VERSION "Generated from PQ35_46 ACAN KMatrix"

NS_ :

BS_:

BU_: XXX AFS Airbag Allrad AppGW_SK BAP_Tester BMS_Hybrid Bremse_ESP_AU714 Bremse_ESP_EPB_EBC460Vi Bremse_MK100_ESC Bremse_MK60EC Bremse_MK70MABS Bremse_TRW_EBC450M Bremse_TRW_ESP Daempfer EPB_TRW EPB_TRW_VW411CS ESP_AU316 FLA Gateway_PQ35 Getriebe_AG6 Getriebe_DL800_R8 Getriebe_DL800_ZSG_R8 Getriebe_DQ Getriebe_DQ_Hyb Getriebe_Sele Gurtmikro_PQ35 HCA LEH_Hybrid LH_EPS_APA LH_EPS_ZF_2G LH_EPS_ZF_3G LPG_Interface_Box LWR LWS Magne_Ride Motor_Diesel Motor_Hybrid Motor_Otto Motor_Slave PDC_PLA Quersperre_VAQ RKA_Plus SAK Waehlhebel Waehlhebel_Sele

BO_ 1827 NMH_ABS: 7 XXX
 SG_ NMH_ABS_Start_1 : 0|1@1+ (1,0) [1|1] "" BMS_Hybrid,EPB_TRW_VW411CS,Gateway_PQ35,Getriebe_AG6,Getriebe_DL800_ZSG_R8,LEH_Hybrid,Motor_Diesel,Motor_Hybrid,Motor_Otto
 SG_ NMH_ABS_Start_2 : 1|1@1+ (1,0) [1|1] "" XXX
 SG_ NMH_ABS_Normal_Mode_1 : 2|1@1+ (1,0) [1|1] "" XXX
 SG_ NMH_ABS_Normal_Mode_2 : 3|1@1+ (1,0) [1|1] "" XXX
 SG_ NMH_ABS_Per_WakeUp : 8|5@1+ (1,0) [0|3] "" XXX
 SG_ NMH_ABS_Fkt_WakeUp : 13|3@1+ (1,0) [0|0] "" XXX
 SG_ NMH_ABS_NM_aktiv_Klemme_15 : 16|1@1+ (1,0) [1|1] "" XXX
 SG_ NMH_ABS_NM_aktiv_Diagnose : 17|1@1+ (1,0) [1|1] "" XXX
 SG_ NMH_ABS_NM_aktiv_Start : 18|1@1+ (1,0) [1|1] "" XXX
 SG_ NMH_ABS_NL_aktiv_4 : 19|1@1+ (1,0) [1|1] "" XXX
 SG_ NMH_ABS_TimeOut_Fehler : 33|1@1+ (1,0) [1|1] "" XXX
 SG_ NMH_ABS_CAN_Diag_deaktiv : 34|1@1+ (1,0) [1|1] "" XXX
 SG_ NMH_ABS_KompSchutz : 35|1@1+ (1,0) [1|1] "" XXX
 SG_ NMH_ABS_Mute_Mode : 36|1@1+ (1,0) [1|1] "" XXX
 SG_ NMH_ABS_Transport_Mode : 37|1@1+ (1,0) [1|1] "" XXX
 SG_ NMH_ABS_Abschaltstufe_aktiv : 38|1@1+ (1,0) [1|1] "" XXX
 SG_ NMH_ABS_Eindraht_Fehler : 39|1@1+ (1,0) [1|1] "" XXX
 SG_ NMH_ABS_Car_WakeUp : 6|1@1+ (1,0) [1|1] "" XXX
 SG_ NMH_ABS_NL_aktiv_5 : 20|1@1+ (1,0) [1|1] "" XXX
 SG_ NMH_ABS_NL_aktiv_6 : 21|1@1+ (1,0) [1|1] "" XXX
 SG_ NMH_ABS_NL_aktiv_7 : 22|1@1+ (1,0) [1|1] "" XXX
 SG_ NMH_ABS_NL_aktiv_8 : 23|1@1+ (1,0) [1|1] "" XXX
 SG_ NMH_ABS_NL_0 : 24|1@1+ (1,0) [0|1] "" XXX
 SG_ NMH_ABS_NL_1 : 25|1@1+ (1,0) [0|1] "" XXX
 SG_ NMH_ABS_NL_2 : 26|1@1+ (1,0) [0|1] "" XXX
 SG_ NMH_ABS_NL_3 : 27|1@1+ (1,0) [0|1] "" XXX
 SG_ NMH_ABS_NL_4 : 28|1@1+ (1,0) [0|1] "" XXX
 SG_ NMH_ABS_NL_5 : 29|1@1+ (1,0) [0|1] "" XXX
 SG_ NMH_ABS_NL_6 : 30|1@1+ (1,0) [0|1] "" XXX
 SG_ NMH_ABS_NL_7 : 31|1@1+ (1,0) [0|1] "" XXX

BO_ 768 mTP_Dyn_Diag_1_1: 8 XXX
 SG_ TPDyn_Diag_1_1 : 0|64@1+ (1,0) [0|0] "" Gateway_PQ35

BO_ 769 mTP_Dyn_Diag_1_2: 8 XXX
 SG_ TPDyn_Diag_1_2 : 0|64@1+ (1,0) [0|0] "" Gateway_PQ35

BO_ 770 mTP_Dyn_Diag_1_3: 8 XXX
 SG_ TPDyn_Diag_1_3 : 0|64@1+ (1,0) [0|0] "" Gateway_PQ35

BO_ 771 mTP_Dyn_Diag_1_4: 8 XXX
 SG_ TPDyn_Diag_1_4 : 0|64@1+ (1,0) [0|0] "" Gateway_PQ35

BO_ 772 mTP_Dyn_Diag_1_5: 8 XXX
 SG_ TPDyn_Diag_1_5 : 0|64@1+ (1,0) [0|0] "" Gateway_PQ35

BO_ 773 mTP_Dyn_Diag_1_6: 8 XXX
 SG_ TPDyn_Diag_1_6 : 0|64@1+ (1,0) [0|0] "" Gateway_PQ35

BO_ 774 mTP_Dyn_Diag_1_7: 8 XXX
 SG_ TPDyn_Diag_1_7 : 0|64@1+ (1,0) [0|0] "" Gateway_PQ35

BO_ 775 mTP_Dyn_Diag_1_8: 8 XXX
 SG_ TPDyn_Diag_1_8 : 0|64@1+ (1,0) [0|0] "" Gateway_PQ35

BO_ 515 mTP_Er_ABS: 7 XXX
 SG_ ABS_TP_Er : 0|56@1+ (1,0) [0|0] "" Gateway_PQ35

BO_ 1440 mBremse_2: 8 XXX
 SG_ BR2_Blinkmode : 39|1@1+ (1,0) [0|1] "" Gateway_PQ35
 SG_ BR2_Querbeschl : 0|8@1+ (0.01,-1.27) [-1.27|1.27] "Unit_ForceOfGravi" AFS,Allrad,AppGW_SK,Daempfer,Gateway_PQ35,Getriebe_AG6,Getriebe_DL800_R8,Getriebe_DQ,Getriebe_DQ_Hyb,Getriebe_Sele,HCA,LWR,Magne_Ride,Motor_Diesel,Motor_Otto,RKA_Plus
 SG_ BR2_Zahnzahl : 0|6@1+ (1,0) [0|63] "" Gateway_PQ35,Getriebe_AG6,Getriebe_DL800_R8,Getriebe_DQ,Getriebe_DQ_Hyb,PDC_PLA,RKA_Plus
 SG_ BR2_Querb_Zahn : 8|1@1+ (1,0) [0|1] "" AFS,Allrad,AppGW_SK,Daempfer,Gateway_PQ35,Getriebe_AG6,Getriebe_DL800_R8,Getriebe_DQ,Getriebe_DQ_Hyb,Getriebe_Sele,HCA,LWR,Magne_Ride,Motor_Diesel,Motor_Otto,PDC_PLA,RKA_Plus
 SG_ BR2_mi_Radgeschw : 9|15@1+ (0.002,0) [0|65.278] "Unit_Hertz" Gateway_PQ35,Getriebe_DL800_R8,Getriebe_DQ,Getriebe_DQ_Hyb
 SG_ BR2_Lampe_ABS : 24|1@1+ (1,0) [0|1] "" Airbag,AppGW_SK,Gateway_PQ35
 SG_ BR2_Lampe_ASR : 25|1@1+ (1,0) [0|1] "" AppGW_SK,Gateway_PQ35,PDC_PLA
 SG_ BR2_Lampe_BK : 26|1@1+ (1,0) [0|1] "" Gateway_PQ35
 SG_ BR2_Lampe_RKA : 27|1@1+ (1,0) [0|1] "" AppGW_SK,Gateway_PQ35
 SG_ BR2_Zaehler : 28|4@1+ (1,0) [0|15] "" Daempfer,Gateway_PQ35,Getriebe_AG6,HCA,Magne_Ride
 SG_ BR2_Text : 32|4@1+ (1,0) [0|14] "" Gateway_PQ35,Getriebe_DL800_R8
 SG_ BR2_Aku_Warn : 36|2@1+ (1,0) [0|3] "" Gateway_PQ35
 SG_ BR2_HDC_aktiv : 38|1@1+ (1,0) [0|1] "" Gateway_PQ35,Getriebe_DL800_R8,Getriebe_DQ,Getriebe_DQ_Hyb,Motor_Diesel,Motor_Hybrid,Motor_Otto
 SG_ BR2_Wegimpulse : 40|11@1+ (1,0) [0|2047] "" AppGW_SK,Gateway_PQ35,Getriebe_DL800_R8,Getriebe_DQ,Getriebe_DQ_Hyb
 SG_ BR2_Ueberl_Imp : 51|1@1+ (1,0) [0|1] "" Gateway_PQ35
 SG_ BR2_Fehlereintr : 52|1@1+ (1,0) [0|1] "" Gateway_PQ35
 SG_ BR2_LampeHDC : 53|1@1+ (1,0) [0|1] "" Gateway_PQ35,Getriebe_DL800_R8,Getriebe_DQ,Getriebe_DQ_Hyb
 SG_ BR2_QB_Querbeschl : 54|1@1+ (1,0) [0|1] "" AFS,Allrad,AppGW_SK,Gateway_PQ35,HCA,LWR,Magne_Ride,Motor_Diesel,Motor_Otto,RKA_Plus
 SG_ BR2_Sta_Imp : 55|1@1+ (1,0) [0|1] "" Gateway_PQ35
 SG_ BR2_Impulszahl : 56|6@1+ (1,0) [0|63] "" AppGW_SK,Gateway_PQ35,Getriebe_AG6,Getriebe_DL800_R8,Getriebe_DQ,Getriebe_DQ_Hyb
 SG_ BR2_SleepInd : 62|1@1+ (1,0) [0|1] "" Gateway_PQ35
 SG_ BR2_Sta_Quer : 63|1@1+ (1,0) [0|1] "" Allrad,Gateway_PQ35,Getriebe_DL800_R8,Getriebe_DQ,Getriebe_DQ_Hyb

BO_ 416 mBremse_1: 8 XXX
 SG_ BR1_ASR_Anf : 0|1@1+ (1,0) [0|1] "" Airbag,Allrad,Gateway_PQ35,Getriebe_AG6,Getriebe_DL800_R8,Getriebe_DQ,Getriebe_DQ_Hyb,LH_EPS_APA,Motor_Diesel,Motor_Hybrid,Motor_Otto,PDC_PLA,RKA_Plus
 SG_ BR1_MSR_Anf : 1|1@1+ (1,0) [0|1] "" Airbag,Gateway_PQ35,Getriebe_AG6,Getriebe_DL800_R8,Getriebe_DQ,Getriebe_DQ_Hyb,LH_EPS_APA,Motor_Diesel,Motor_Hybrid,Motor_Otto,PDC_PLA,RKA_Plus
 SG_ BR1_ABS_Brems : 2|1@1+ (1,0) [0|1] "" Airbag,Allrad,Daempfer,EPB_TRW,EPB_TRW_VW411CS,Gateway_PQ35,Getriebe_AG6,Getriebe_DL800_R8,Getriebe_DQ,Getriebe_DQ_Hyb,HCA,LH_EPS_APA,Magne_Ride,Motor_Diesel,Motor_Hybrid,Motor_Otto,PDC_PLA,RKA_Plus
 SG_ BR1_EDS_Eingr : 3|1@1+ (1,0) [0|1] "" Airbag,Allrad,Daempfer,Gateway_PQ35,Getriebe_AG6,Getriebe_DL800_R8,Getriebe_DQ,Getriebe_DQ_Hyb,LH_EPS_APA,Motor_Diesel,Motor_Hybrid,Motor_Otto,PDC_PLA,RKA_Plus
 SG_ BR1_ESP_Eingr : 4|1@1+ (1,0) [0|1] "" AFS,Airbag,Allrad,Daempfer,Gateway_PQ35,Getriebe_AG6,Getriebe_DL800_R8,Getriebe_DQ,Getriebe_DQ_Hyb,Getriebe_Sele,HCA,LH_EPS_APA,LH_EPS_ZF_2G,LH_EPS_ZF_3G,Motor_Diesel,Motor_Hybrid,Motor_Otto,PDC_PLA,RKA_Plus
 SG_ BR1_ASR_Eingr : 5|2@1+ (1,0) [0|3] "" Gateway_PQ35,Getriebe_AG6,Getriebe_DL800_R8,Getriebe_DQ,Getriebe_DQ_Hyb,LH_EPS_APA
 SG_ BR1_EBV_Eingr : 7|1@1+ (1,0) [0|1] "" Daempfer,Gateway_PQ35,LH_EPS_APA,RKA_Plus
 SG_ BR1_Lampe_ABS : 8|1@1+ (1,0) [0|1] "" Gateway_PQ35
 SG_ BR1_Lampe_ASR : 9|1@1+ (1,0) [0|1] "" Gateway_PQ35
 SG_ BR1_Lampe_BK : 10|1@1+ (1,0) [0|1] "" Gateway_PQ35
 SG_ BR1_Lichtschalt : 11|1@1+ (1,0) [0|1] "" AFS,Allrad,Gateway_PQ35,LH_EPS_APA,LH_EPS_ZF_2G,LH_EPS_ZF_3G,LWR,Motor_Diesel,Motor_Hybrid,Motor_Otto,RKA_Plus
 SG_ BR1_StaDruckschw : 12|1@1+ (1,0) [0|1] "" Gateway_PQ35,Motor_Diesel,Motor_Hybrid,Motor_Otto
 SG_ BR1_Diagnose : 15|1@1+ (1,0) [0|1] "" Airbag,Gateway_PQ35
 SG_ BR1_Rad_kmh : 17|15@1+ (0.01,0) [0|326.39] "Unit_KiloMeterPerHour" Airbag,BMS_Hybrid,Daempfer,FLA,Gateway_PQ35,Getriebe_AG6,Getriebe_DL800_R8,Getriebe_DL800_ZSG_R8,Getriebe_DQ,Getriebe_DQ_Hyb,Getriebe_Sele,HCA,LH_EPS_APA,LH_EPS_ZF_2G,LH_EPS_ZF_3G,Magne_Ride,Motor_Diesel,Motor_Hybrid,Motor_Otto,PDC_PLA,SAK
 SG_ BR1_ASRMo_fa : 40|8@1+ (0.39,0) [0|99.06] "Unit_PerCent" Gateway_PQ35,Motor_Diesel,Motor_Hybrid,Motor_Otto
 SG_ BR1_MSR_Mo_inv : 40|8@1+ (-0.39,99.45) [0|99.06] "Unit_PerCent" Gateway_PQ35,Motor_Diesel,Motor_Hybrid,Motor_Otto
 SG_ BR1_MSR_Mo : 48|8@1+ (0.39,0) [0|99.06] "Unit_PerCent" Gateway_PQ35,Motor_Diesel,Motor_Hybrid,Motor_Otto
 SG_ BR1_Zaehler : 56|4@1+ (1,0) [0|15] "" Airbag,Daempfer,EPB_TRW,EPB_TRW_VW411CS,Gateway_PQ35,Getriebe_AG6,HCA,LH_EPS_APA,LH_EPS_ZF_2G,LH_EPS_ZF_3G,Magne_Ride,Motor_Diesel,Motor_Hybrid,Motor_Otto,PDC_PLA
 SG_ BR1_ASR_ESP : 60|1@1+ (1,0) [0|1] "" Gateway_PQ35
 SG_ BR1_ESPASR_passiv : 61|1@1+ (1,0) [0|1] "" Gateway_PQ35,Getriebe_AG6,Getriebe_DL800_R8,Getriebe_DQ,Getriebe_DQ_Hyb,Getriebe_Sele,HCA,Magne_Ride,Motor_Diesel,Motor_Otto,PDC_PLA
 SG_ BR1_Sta_ESP : 62|1@1+ (1,0) [0|1] "" Gateway_PQ35,Getriebe_DL800_R8,Getriebe_DQ,Getriebe_DQ_Hyb,Magne_Ride,Motor_Diesel,Motor_Otto,PDC_PLA,RKA_Plus
 SG_ BR1_Ersatz_Kmh : 63|1@1+ (1,0) [0|1] "" Airbag,Gateway_PQ35,HCA,LH_EPS_APA,LH_EPS_ZF_2G,LH_EPS_ZF_3G,Motor_Diesel,Motor_Hybrid,Motor_Otto,PDC_PLA
 SG_ BR1_MAD : 13|1@1+ (1,0) [0|1] "" Gateway_PQ35
 SG_ BR1_Sta_MAD : 14|1@1+ (1,0) [0|1] "" Gateway_PQ35
 SG_ BR1_BKV_aktiv : 16|1@1+ (1,0) [0|1] "" Gateway_PQ35,Motor_Diesel,Motor_Hybrid,Motor_Otto
 SG_ BR1_ASRMo_sl : 32|8@1+ (0.39,0) [0|99.06] "Unit_PerCent" Gateway_PQ35,Motor_Hybrid,Motor_Otto

BO_ 928 mBremse_10: 8 XXX
 SG_ B10_Checksumme : 0|8@1+ (1,0) [0|255] "" Gateway_PQ35,Motor_Diesel,Motor_Otto,PDC_PLA
 SG_ B10_Zaehler : 8|4@1+ (1,0) [0|15] "" Gateway_PQ35,Motor_Diesel,Motor_Otto,PDC_PLA
 SG_ B10_QB_Wegimp_VL : 12|1@1+ (1,0) [0|1] "" Gateway_PQ35,Motor_Diesel,Motor_Otto,PDC_PLA
 SG_ B10_QB_Wegimp_VR : 13|1@1+ (1,0) [0|1] "" Gateway_PQ35,Motor_Diesel,Motor_Otto,PDC_PLA
 SG_ B10_QB_Wegimp_HL : 14|1@1+ (1,0) [0|1] "" Gateway_PQ35,Motor_Diesel,Motor_Otto,PDC_PLA
 SG_ B10_QB_Wegimp_HR : 15|1@1+ (1,0) [0|1] "" Gateway_PQ35,Motor_Diesel,Motor_Otto,PDC_PLA
 SG_ B10_Wegimp_VL : 16|10@1+ (1,0) [0|1000] "" Gateway_PQ35,Motor_Diesel,Motor_Otto,PDC_PLA
 SG_ B10_Wegimp_VR : 26|10@1+ (1,0) [0|1000] "" Gateway_PQ35,Motor_Diesel,Motor_Otto,PDC_PLA
 SG_ B10_Wegimp_HL : 36|10@1+ (1,0) [0|1000] "" Gateway_PQ35,Motor_Diesel,Motor_Otto,PDC_PLA
 SG_ B10_Wegimp_HR : 46|10@1+ (1,0) [0|1000] "" Gateway_PQ35,Motor_Diesel,Motor_Otto,PDC_PLA
 SG_ B10_QB_Fahrtr_VL : 56|1@1+ (1,0) [0|1] "" Gateway_PQ35,PDC_PLA
 SG_ B10_QB_Fahrtr_VR : 57|1@1+ (1,0) [0|1] "" Gateway_PQ35,PDC_PLA
 SG_ B10_QB_Fahrtr_HL : 58|1@1+ (1,0) [0|1] "" Gateway_PQ35,PDC_PLA
 SG_ B10_QB_Fahrtr_HR : 59|1@1+ (1,0) [0|1] "" Gateway_PQ35,PDC_PLA
 SG_ B10_Fahrtr_VL : 60|1@1+ (1,0) [0|1] "" Gateway_PQ35,PDC_PLA
 SG_ B10_Fahrtr_VR : 61|1@1+ (1,0) [0|1] "" Gateway_PQ35,PDC_PLA
 SG_ B10_Fahrtr_HL : 62|1@1+ (1,0) [0|1] "" Gateway_PQ35,PDC_PLA
 SG_ B10_Fahrtr_HR : 63|1@1+ (1,0) [0|1] "" Gateway_PQ35,PDC_PLA

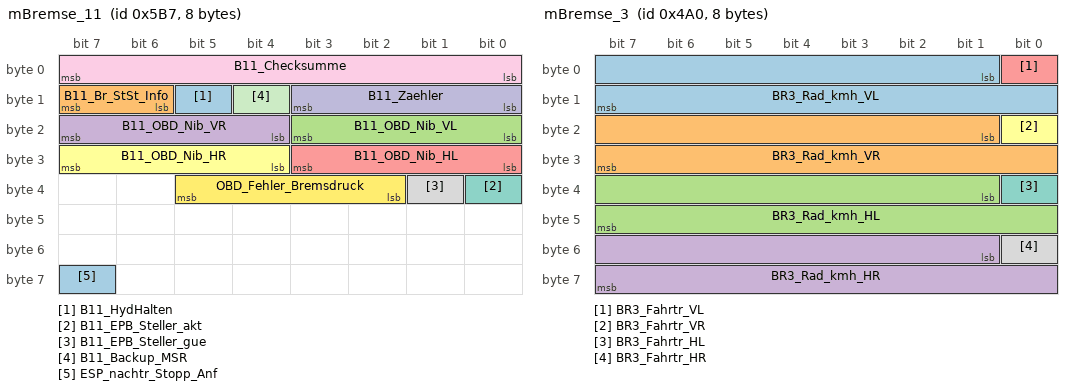
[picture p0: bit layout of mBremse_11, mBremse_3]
BO_ 1463 mBremse_11: 8 XXX
 SG_ B11_HydHalten : 13|1@1+ (1,0) [0|1] "" EPB_TRW_VW411CS,Gateway_PQ35,Getriebe_DQ,Getriebe_DQ_Hyb,Motor_Diesel,Motor_Otto,PDC_PLA
 SG_ B11_Br_StSt_Info : 14|2@1+ (1,0) [0|3] "" EPB_TRW_VW411CS,Gateway_PQ35,Motor_Diesel,Motor_Otto
 SG_ B11_OBD_Nib_VL : 16|4@1+ (1,0) [0|15] "" Gateway_PQ35,Motor_Diesel,Motor_Otto
 SG_ B11_OBD_Nib_VR : 20|4@1+ (1,0) [0|15] "" Gateway_PQ35,Motor_Diesel,Motor_Otto
 SG_ B11_OBD_Nib_HL : 24|4@1+ (1,0) [0|15] "" Gateway_PQ35,Motor_Diesel,Motor_Otto
 SG_ B11_OBD_Nib_HR : 28|4@1+ (1,0) [0|15] "" Gateway_PQ35,Motor_Diesel,Motor_Otto
 SG_ B11_EPB_Steller_akt : 32|1@1+ (1,0) [0|1] "" Gateway_PQ35,Motor_Diesel,Motor_Otto
 SG_ B11_EPB_Steller_gue : 33|1@1+ (1,0) [0|1] "" Gateway_PQ35,Motor_Diesel,Motor_Otto
 SG_ B11_Checksumme : 0|8@1+ (1,0) [0|255] "" Gateway_PQ35,Motor_Hybrid
 SG_ B11_Zaehler : 8|4@1+ (1,0) [0|15] "" Gateway_PQ35,Motor_Hybrid
 SG_ B11_Backup_MSR : 12|1@1+ (1,0) [0|1] "" Gateway_PQ35,Motor_Hybrid
 SG_ OBD_Fehler_Bremsdruck : 34|4@1+ (1,0) [0|15] "" Gateway_PQ35,Motor_Hybrid
 SG_ ESP_nachtr_Stopp_Anf : 63|1@1+ (1,0) [0|1] "" Gateway_PQ35,Motor_Diesel,Motor_Otto

BO_ 1184 mBremse_3: 8 XXX
 SG_ BR3_Rad_kmh_VL : 1|15@1+ (0.01,0) [0|326.39] "Unit_KiloMeterPerHour" AFS,Allrad,EPB_TRW,EPB_TRW_VW411CS,Gateway_PQ35,Getriebe_AG6,Getriebe_DL800_R8,Getriebe_DQ,Getriebe_DQ_Hyb,Getriebe_Sele,LH_EPS_APA,LH_EPS_ZF_2G,LH_EPS_ZF_3G,LWR,LWS,Magne_Ride,Motor_Diesel,Motor_Hybrid,Motor_Otto,PDC_PLA
 SG_ BR3_Rad_kmh_VR : 17|15@1+ (0.01,0) [0|326.39] "Unit_KiloMeterPerHour" AFS,Allrad,EPB_TRW,EPB_TRW_VW411CS,Gateway_PQ35,Getriebe_AG6,Getriebe_DL800_R8,Getriebe_DQ,Getriebe_DQ_Hyb,Getriebe_Sele,LH_EPS_APA,LH_EPS_ZF_2G,LH_EPS_ZF_3G,LWR,LWS,Magne_Ride,Motor_Diesel,Motor_Hybrid,Motor_Otto,PDC_PLA
 SG_ BR3_Rad_kmh_HL : 33|15@1+ (0.01,0) [0|326.39] "Unit_KiloMeterPerHour" AFS,Allrad,EPB_TRW,EPB_TRW_VW411CS,Gateway_PQ35,Getriebe_AG6,Getriebe_DL800_R8,Getriebe_DQ,Getriebe_DQ_Hyb,Getriebe_Sele,LH_EPS_APA,LH_EPS_ZF_2G,LH_EPS_ZF_3G,LWR,LWS,Magne_Ride,Motor_Diesel,Motor_Hybrid,Motor_Otto,PDC_PLA
 SG_ BR3_Rad_kmh_HR : 49|15@1+ (0.01,0) [0|326.39] "Unit_KiloMeterPerHour" AFS,Allrad,EPB_TRW,EPB_TRW_VW411CS,Gateway_PQ35,Getriebe_AG6,Getriebe_DL800_R8,Getriebe_DQ,Getriebe_DQ_Hyb,Getriebe_Sele,LH_EPS_APA,LH_EPS_ZF_2G,LH_EPS_ZF_3G,LWR,LWS,Magne_Ride,Motor_Diesel,Motor_Hybrid,Motor_Otto,PDC_PLA
 SG_ BR3_Fahrtr_VL : 0|1@1+ (1,0) [0|1] "" AFS,EPB_TRW_VW411CS,Gateway_PQ35,Getriebe_AG6,LWR,Magne_Ride
 SG_ BR3_Fahrtr_VR : 16|1@1+ (1,0) [0|1] "" AFS,EPB_TRW_VW411CS,Gateway_PQ35,Getriebe_AG6,LWR,Magne_Ride
 SG_ BR3_Fahrtr_HL : 32|1@1+ (1,0) [0|1] "" EPB_TRW_VW411CS,Gateway_PQ35,Getriebe_AG6,Magne_Ride
 SG_ BR3_Fahrtr_HR : 48|1@1+ (1,0) [0|1] "" EPB_TRW_VW411CS,Gateway_PQ35,Getriebe_AG6,Magne_Ride

BO_ 672 mBremse_4: 8 XXX
 SG_ BR4_Vorgabe_Mi : 0|8@1+ (7,-896) [-896|882] "Unit_NewtoMeter" Allrad,Gateway_PQ35
 SG_ BR4_Einheit : 16|2@1+ (1,0) [0|2] "" Allrad,Gateway_PQ35,Quersperre_VAQ
 SG_ BR4_Schwelle : 18|2@1+ (1,0) [0|3] "" Gateway_PQ35,Getriebe_AG6,Motor_Hybrid,Motor_Otto
 SG_ BR4_Lampentrennung_gue : 26|1@1+ (1,0) [0|1] "" Gateway_PQ35
 SG_ BR4_Lampe_ASRESP : 27|1@1+ (1,0) [0|1] "" AppGW_SK,Gateway_PQ35
 SG_ BR4_ESP_Off : 28|1@1+ (1,0) [0|1] "" Gateway_PQ35
 SG_ BR1_ASR_ESP : 29|1@1+ (1,0) [0|1] "" Gateway_PQ35
 SG_ BR4_Unterdruck : 32|8@1+ (4,0) [0|1016] "Unit_MilliBar" Gateway_PQ35,Getriebe_AG6,Motor_Hybrid,Motor_Otto
 SG_ BR4_Zaehler : 52|4@1+ (1,0) [0|15] "" Gateway_PQ35,Motor_Diesel,Motor_Hybrid,Motor_Otto,Quersperre_VAQ
 SG_ BR4_Checksum : 56|8@1+ (1,0) [0|255] "" Gateway_PQ35,Motor_Diesel,Motor_Hybrid,Motor_Otto,Quersperre_VAQ
 SG_ BR4_Vorgabe_Mi_308 : 0|8@1+ (0.7874015748031496063,-100.0000000000000000001) [0|100.0000000000000000001] "Unit_PerCent" Gateway_PQ35
 SG_ BR4_Vorgabe_Max : 0|8@1+ (10,0) [0|2540] "Unit_NewtoMeter" Gateway_PQ35,Quersperre_VAQ
 SG_ BR4_Vorgabe_Hi : 8|8@1+ (0.7874015748031496063,-100.0000000000000000001) [0|100.0000000000000000001] "Unit_PerCent" Gateway_PQ35
 SG_ BR4_Vorgabe_Min : 8|8@1+ (10,0) [0|2540] "Unit_NewtoMeter" Gateway_PQ35,Quersperre_VAQ
 SG_ BR4_Abschaltung_VL : 20|1@1+ (1,0) [0|1] "" Gateway_PQ35
 SG_ BR4_Abschaltung_VR : 21|1@1+ (1,0) [0|1] "" Gateway_PQ35
 SG_ BR4_Abschaltung_HL : 22|1@1+ (1,0) [0|1] "" Gateway_PQ35
 SG_ BR4_Abschaltung_HR : 23|1@1+ (1,0) [0|1] "" Gateway_PQ35
 SG_ BR4_Lampe_RKA : 24|1@1+ (1,0) [0|1] "" Gateway_PQ35
 SG_ BR4_Summer_RKA : 25|1@1+ (1,0) [0|1] "" Gateway_PQ35
 SG_ BR4_Status_ESP : 40|4@1+ (1,0) [0|5] "" Gateway_PQ35,Quersperre_VAQ
 SG_ BR4_MABS_Verbau : 51|1@1+ (1,0) [0|1] "" Gateway_PQ35
 SG_ BR4_RKA_Verbau : 30|2@1+ (1,0) [0|2] "" AppGW_SK,Gateway_PQ35

BO_ 1192 mBremse_5: 8 XXX
 SG_ BR5_Giergeschw : 0|14@1+ (0.01,0) [0|100] "Unit_DegreOfArcPerSecond" AFS,Allrad,Daempfer,FLA,Gateway_PQ35,HCA,LWR,Magne_Ride,PDC_PLA,RKA_Plus
 SG_ BR5_Sta_Gierrate : 14|1@1+ (1,0) [0|1] "" AFS,Allrad,Daempfer,FLA,Gateway_PQ35,HCA,LWR,Magne_Ride,PDC_PLA,RKA_Plus
 SG_ BR5_Vorzeichen : 15|1@1+ (1,0) [0|1] "" AFS,Allrad,Daempfer,FLA,Gateway_PQ35,HCA,LWR,Magne_Ride,PDC_PLA,RKA_Plus
 SG_ BR5_Bremsdruck : 16|12@1+ (0.1,0) [0|409.4] "Unit_Bar" Daempfer,EPB_TRW,EPB_TRW_VW411CS,Gateway_PQ35,Getriebe_AG6,Getriebe_DL800_R8,Getriebe_DQ,Getriebe_DQ_Hyb,HCA,Magne_Ride,Motor_Diesel,Motor_Otto,PDC_PLA
 SG_ BR5_Stillstand : 28|1@1+ (1,0) [0|1] "" Gateway_PQ35,HCA,Magne_Ride,PDC_PLA
 SG_ BR5_Druckgueltig : 29|1@1+ (1,0) [0|1] "" Daempfer,EPB_TRW,EPB_TRW_VW411CS,Gateway_PQ35,Getriebe_AG6,Getriebe_DL800_R8,Getriebe_DQ,Getriebe_DQ_Hyb,HCA,Magne_Ride,Motor_Diesel,Motor_Otto,PDC_PLA
 SG_ BR5_Sta_Druck : 30|1@1+ (1,0) [0|1] "" EPB_TRW_VW411CS,Gateway_PQ35
 SG_ BR5_Sign_Druck : 31|1@1+ (1,0) [0|1] "" Daempfer,EPB_TRW_VW411CS,Gateway_PQ35,Getriebe_AG6,Getriebe_DL800_R8,Getriebe_DQ,Getriebe_DQ_Hyb,HCA,Magne_Ride,Motor_Diesel,Motor_Otto
 SG_ BR5_Bremslicht : 43|1@1+ (1,0) [0|1] "" Gateway_PQ35
 SG_ BR5_AWV2_Bremsruck : 46|1@1+ (1,0) [0|1] "" Gateway_PQ35
 SG_ BR5_AWV2_Fehler : 47|1@1+ (1,0) [0|1] "" Gateway_PQ35
 SG_ BR5_Zaehler : 52|4@1+ (1,0) [0|15] "" Daempfer,EPB_TRW,EPB_TRW_VW411CS,Gateway_PQ35,Getriebe_AG6,HCA,Magne_Ride,Motor_Diesel,Motor_Hybrid,Motor_Otto,PDC_PLA
 SG_ BR5_Checksumme : 56|8@1+ (1,0) [0|255] "" Daempfer,EPB_TRW,EPB_TRW_VW411CS,Gateway_PQ35,Getriebe_AG6,HCA,Magne_Ride,Motor_Diesel,Motor_Hybrid,Motor_Otto
 SG_ ESP_Rollenmodus_Deaktivieren : 34|1@1+ (1,0) [0|1] "" Gateway_PQ35
 SG_ ESP_Stat_FallBack_eBKV : 35|1@1+ (1,0) [0|1] "" Gateway_PQ35
 SG_ ESP_Anforderung_EPB : 36|2@1+ (1,0) [0|3] "" EPB_TRW_VW411CS,Gateway_PQ35
 SG_ BR5_Anhi_akt : 41|1@1+ (1,0) [0|1] "" Gateway_PQ35,Getriebe_DL800_R8,Getriebe_DQ,Getriebe_DQ_Hyb
 SG_ BR5_v_Ueberw : 42|1@1+ (1,0) [0|1] "" Gateway_PQ35
 SG_ BR5_Fahrer_tritt_ZBR_Schw : 45|1@1+ (1,0) [0|1] "" Gateway_PQ35
 SG_ BR5_ECD_Lampe : 51|1@1+ (1,0) [0|1] "" Gateway_PQ35
 SG_ ESP_Autohold_aktiv : 38|1@1+ (1,0) [0|1] "" EPB_TRW_VW411CS,Gateway_PQ35,Motor_Diesel,Motor_Otto
 SG_ ESP_Autohold_Standby : 39|1@1+ (1,0) [0|1] "" EPB_TRW_VW411CS,Gateway_PQ35,Motor_Diesel,Motor_Otto
 SG_ BR5_Anhi_Sta : 40|1@1+ (1,0) [0|1] "" Gateway_PQ35,Getriebe_DL800_R8,Getriebe_DQ,Getriebe_DQ_Hyb
 SG_ BR5_Notbremsung : 44|1@1+ (1,0) [0|1] "" Gateway_PQ35
 SG_ BR5_ZT_Rueckk_Umsetz : 48|1@1+ (1,0) [0|1] "" Gateway_PQ35,Motor_Diesel,Motor_Otto
 SG_ BR5_ANB_CM_Rueckk_Umsetz : 49|1@1+ (1,0) [0|1] "" Gateway_PQ35
 SG_ BR5_HDC_bereit : 50|1@1+ (1,0) [0|1] "" Gateway_PQ35

BO_ 428 mBremse_8: 8 XXX
 SG_ BR8_Checksumme : 0|8@1+ (1,0) [0|255] "" Airbag,EPB_TRW,EPB_TRW_VW411CS,Gateway_PQ35,Getriebe_AG6,Getriebe_DL800_R8,Getriebe_DQ,Getriebe_DQ_Hyb,Motor_Diesel,Motor_Otto,PDC_PLA
 SG_ BR8_Zaehler : 8|4@1+ (1,0) [0|15] "" Airbag,EPB_TRW,EPB_TRW_VW411CS,Gateway_PQ35,Getriebe_AG6,Motor_Diesel,Motor_Otto,PDC_PLA
 SG_ BR8_Sta_ACC_Anf : 12|1@1+ (1,0) [0|1] "" Gateway_PQ35,Getriebe_AG6,Getriebe_DL800_R8,Getriebe_DQ,Motor_Diesel,Motor_Otto
 SG_ BR8_Verz_EPB_akt : 13|1@1+ (1,0) [0|1] "" EPB_TRW,EPB_TRW_VW411CS,Gateway_PQ35,Getriebe_AG6,Motor_Diesel,Motor_Otto
 SG_ BR8_Sta_Br_temp : 14|1@1+ (1,0) [0|1] "" Gateway_PQ35,Motor_Diesel,Motor_Otto
 SG_ BR8_Sta_Br_Druck : 15|1@1+ (1,0) [0|1] "" Gateway_PQ35,Motor_Diesel,Motor_Otto
 SG_ BR8_Istbeschl : 32|9@1+ (0.02,-7.22) [-7.22|2.98] "Unit_MeterPerSeconSquar" Gateway_PQ35,Motor_Diesel,Motor_Otto
 SG_ BR8_QB_LBeschl : 42|1@1+ (1,0) [0|1] "" AppGW_SK,EPB_TRW_VW411CS,Gateway_PQ35,Getriebe_DL800_R8,Getriebe_DQ,Getriebe_DQ_Hyb,Motor_Diesel,Motor_Otto,PDC_PLA
 SG_ BR8_aktBrSyst : 45|1@1+ (1,0) [0|1] "" Gateway_PQ35,Motor_Diesel,Motor_Otto
 SG_ BR8_StaBrSyst : 47|1@1+ (1,0) [0|1] "" Gateway_PQ35,Motor_Diesel,Motor_Otto
 SG_ BR8_Laengsbeschl : 48|10@1+ (0.03125,-16) [-15.96875|15.9375] "Unit_MeterPerSeconSquar" AppGW_SK,EPB_TRW_VW411CS,Gateway_PQ35,Getriebe_AG6,Getriebe_DL800_R8,Getriebe_DQ,Getriebe_DQ_Hyb,Motor_Diesel,Motor_Otto,PDC_PLA
 SG_ BR8_Sta_ADR_BR : 58|1@1+ (1,0) [0|1] "" Gateway_PQ35,Motor_Diesel,Motor_Otto
 SG_ BR8_Sta_VerzReg : 60|1@1+ (1,0) [0|1] "" Gateway_PQ35,Motor_Diesel,Motor_Otto
 SG_ BR8_Verz_EPB : 62|1@1+ (1,0) [0|1] "" EPB_TRW,EPB_TRW_VW411CS,Gateway_PQ35
 SG_ BR8_Check_EPB : 63|1@1+ (1,0) [0|1] "" EPB_TRW_VW411CS,Gateway_PQ35
 SG_ BR8_HHC_Haltebestaetigung : 16|1@1+ (1,0) [0|1] "" Gateway_PQ35,Getriebe_DL800_R8
 SG_ BR8_HHC_Signal_QBit : 17|1@1+ (1,0) [0|1] "" Gateway_PQ35,Getriebe_DL800_R8
 SG_ BR8_Sta_HW_BLS : 41|1@1+ (1,0) [0|1] "" Gateway_PQ35
 SG_ BR8_ESC_Mode : 43|2@1+ (1,0) [0|3] "" Gateway_PQ35
 SG_ BR8_Fa_bremst : 46|1@1+ (1,0) [0|1] "" Gateway_PQ35,Motor_Diesel,Motor_Otto
 SG_ BR8_Quattro : 59|1@1+ (1,0) [0|1] "" Gateway_PQ35
 SG_ BR8_Sta_BLS : 61|1@1+ (1,0) [0|1] "" Gateway_PQ35,Motor_Diesel,Motor_Otto
 SG_ ESP_MKB_ausloesbar : 20|1@1+ (1,0) [0|1] "" Airbag,Gateway_PQ35
 SG_ ESP_Haltebestaetigung : 21|1@1+ (1,0) [0|1] "" Gateway_PQ35,Motor_Diesel,Motor_Otto
 SG_ ESC_Motorstartverzoegerung : 22|1@1+ (1,0) [0|1] "" Gateway_PQ35,Motor_Diesel,Motor_Otto

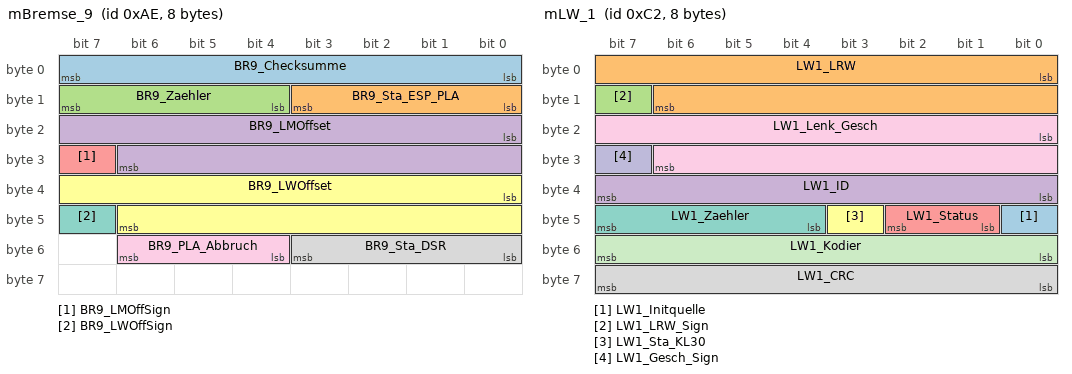
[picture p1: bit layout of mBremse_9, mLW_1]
BO_ 174 mBremse_9: 8 XXX
 SG_ BR9_Checksumme : 0|8@1+ (1,0) [0|255] "" LH_EPS_APA,LH_EPS_ZF_2G,LH_EPS_ZF_3G
 SG_ BR9_Sta_ESP_PLA : 8|4@1+ (1,0) [0|10] "" Getriebe_DQ,Getriebe_DQ_Hyb,PDC_PLA
 SG_ BR9_Zaehler : 12|4@1+ (1,0) [0|15] "" LH_EPS_APA,LH_EPS_ZF_2G,LH_EPS_ZF_3G
 SG_ BR9_LMOffset : 16|15@1+ (0.0003052,0) [0|10.0004884] "Unit_NewtoMeter" LH_EPS_APA,LH_EPS_ZF_2G,LH_EPS_ZF_3G
 SG_ BR9_LMOffSign : 31|1@1+ (1,0) [0|1] "" LH_EPS_APA,LH_EPS_ZF_2G,LH_EPS_ZF_3G
 SG_ BR9_LWOffset : 32|15@1+ (0.04375,0) [0|1433.55625] "Unit_DegreOfArc" LH_EPS_APA,LH_EPS_ZF_2G,LH_EPS_ZF_3G
 SG_ BR9_LWOffSign : 47|1@1+ (1,0) [0|1] "" LH_EPS_APA,LH_EPS_ZF_2G,LH_EPS_ZF_3G
 SG_ BR9_Sta_DSR : 48|4@1+ (1,0) [0|7] "" LH_EPS_APA,LH_EPS_ZF_2G,LH_EPS_ZF_3G
 SG_ BR9_PLA_Abbruch : 52|3@1+ (1,0) [1|6] "" PDC_PLA

BO_ 1986 mLWS_Init: 4 XXX
 SG_ LWI_Init_ID : 0|8@1+ (1,0) [0|255] "" LWS
 SG_ LWI_Codierbytes : 8|24@1+ (1,0) [0|16777215] "" LWS

BO_ 912 mGate_Komf_1: 8 XXX
 SG_ GK1_SleepAckn : 7|1@1+ (1,0) [0|1] "" Bremse_ESP_AU714,Bremse_MK60EC,Bremse_MK70MABS,Bremse_TRW_ESP,EPB_TRW,ESP_AU316,Getriebe_DL800_R8,Getriebe_DL800_ZSG_R8,Getriebe_DQ,Getriebe_DQ_Hyb,Getriebe_Sele,LH_EPS_APA,LH_EPS_ZF_2G,LH_EPS_ZF_3G,LWS,Motor_Diesel,Motor_Hybrid,Motor_Otto,Waehlhebel,Waehlhebel_Sele
 SG_ GK1_Sta_Anhaen : 1|1@1+ (1,0) [0|1] "" Bremse_ESP_EPB_EBC460Vi,Bremse_MK100_ESC,Bremse_MK60EC,Bremse_TRW_EBC450M,Bremse_TRW_ESP,ESP_AU316,Getriebe_DL800_R8,Getriebe_DQ,Getriebe_DQ_Hyb,HCA,Motor_Diesel,Motor_Otto,PDC_PLA,RKA_Plus
 SG_ GK1_Sta_Licht1 : 2|1@1+ (1,0) [0|1] "" AFS,AppGW_SK,Bremse_ESP_AU714,Bremse_ESP_EPB_EBC460Vi,Bremse_MK100_ESC,Bremse_MK60EC,Bremse_MK70MABS,Bremse_TRW_EBC450M,Bremse_TRW_ESP,EPB_TRW,EPB_TRW_VW411CS,ESP_AU316,FLA,LH_EPS_APA,LH_EPS_ZF_2G,LH_EPS_ZF_3G,Motor_Diesel,Motor_Otto,PDC_PLA
 SG_ GK1_Sta_Tuerkont : 4|1@1+ (1,0) [0|1] "" Bremse_ESP_EPB_EBC460Vi,Bremse_MK100_ESC,Bremse_MK60EC,Bremse_MK70MABS,Bremse_TRW_EBC450M,Bremse_TRW_ESP,EPB_TRW,EPB_TRW_VW411CS,ESP_AU316,Getriebe_DL800_R8,Getriebe_DQ,Getriebe_DQ_Hyb,Motor_Diesel,Motor_Hybrid,Motor_Otto,PDC_PLA
 SG_ GK1_Fa_Tuerkont : 16|1@1+ (1,0) [0|1] "" AppGW_SK,Bremse_ESP_EPB_EBC460Vi,Bremse_MK100_ESC,Bremse_MK60EC,Bremse_MK70MABS,Bremse_TRW_EBC450M,Bremse_TRW_ESP,EPB_TRW,EPB_TRW_VW411CS,ESP_AU316,Getriebe_AG6,Getriebe_DL800_R8,Getriebe_DQ,Getriebe_DQ_Hyb,Motor_Diesel,Motor_Hybrid,Motor_Otto,PDC_PLA
 SG_ GK1_Rueckfahr : 28|1@1+ (1,0) [1|1] "" AFS,Allrad,AppGW_SK,Bremse_ESP_AU714,Bremse_ESP_EPB_EBC460Vi,Bremse_MK100_ESC,Bremse_MK60EC,Bremse_MK70MABS,Bremse_TRW_EBC450M,Bremse_TRW_ESP,EPB_TRW,EPB_TRW_VW411CS,ESP_AU316,FLA,LH_EPS_APA,LH_EPS_ZF_2G,LH_EPS_ZF_3G,Motor_Diesel,Motor_Otto,PDC_PLA
 SG_ GK1_Anhaenger : 46|1@1+ (1,0) [0|1] "" Bremse_ESP_EPB_EBC460Vi,Bremse_MK100_ESC,Bremse_MK60EC,Bremse_TRW_EBC450M,Bremse_TRW_ESP,ESP_AU316,Getriebe_DL800_R8,Getriebe_DQ,Getriebe_DQ_Hyb,HCA,Motor_Diesel,Motor_Otto,PDC_PLA,RKA_Plus
 SG_ GK1_Wischer_vorn : 50|1@1+ (1,0) [0|1] "" AFS,Bremse_ESP_AU714,Bremse_ESP_EPB_EBC460Vi,Bremse_MK100_ESC,Bremse_MK60EC,Bremse_MK70MABS,Bremse_TRW_EBC450M,Bremse_TRW_ESP,ESP_AU316,HCA,Motor_Diesel,Motor_Hybrid,Motor_Otto
 SG_ GK1_Sta_ILM_F_1 : 51|1@1+ (1,0) [0|1] "" AFS,Bremse_ESP_AU714,Bremse_ESP_EPB_EBC460Vi,Bremse_MK100_ESC,Bremse_MK60EC,Bremse_MK70MABS,Bremse_TRW_EBC450M,Bremse_TRW_ESP,ESP_AU316,HCA,Motor_Diesel,Motor_Hybrid,Motor_Otto
 SG_ GK1_Warnblk_Status : 55|1@1+ (1,0) [1|1] "" AppGW_SK,Bremse_ESP_EPB_EBC460Vi,Bremse_MK100_ESC,Bremse_TRW_EBC450M,Bremse_TRW_ESP,ESP_AU316
 SG_ GK1_Sta_RDK_Warn : 0|1@1+ (1,0) [0|1] "" XXX
 SG_ GK1_Sta_Licht3 : 3|1@1+ (1,0) [0|1] "" AFS
 SG_ GK1_Sta_Li_vorn : 5|1@1+ (1,0) [0|1] "" AFS
 SG_ LIA_Standlicht : 6|1@1+ (1,0) [1|1] "" XXX
 SG_ GK1_CharismaModus : 8|4@1+ (1,0) [0|3] "" Daempfer,Getriebe_DL800_R8,Getriebe_DQ,Getriebe_DQ_Hyb,LH_EPS_APA,LH_EPS_ZF_2G,LH_EPS_ZF_3G,Magne_Ride,Motor_Diesel,Motor_Otto
 SG_ GK1_SamFktNr : 12|4@1+ (1,0) [0|1] "" Daempfer,Getriebe_DL800_R8,Getriebe_DQ,Getriebe_DQ_Hyb,LH_EPS_APA,LH_EPS_ZF_2G,LH_EPS_ZF_3G,Magne_Ride,Motor_Diesel,Motor_Otto
 SG_ GK1_RueckfahrSch : 17|1@1+ (1,0) [0|1] "" Bremse_ESP_AU714
 SG_ GK1_ELV_verrieg : 18|1@1+ (1,0) [0|1] "" XXX
 SG_ GK1_Sta_Kessy_2 : 19|1@1+ (1,0) [0|1] "" Motor_Diesel,Motor_Otto
 SG_ GK1_Sta_Stdhzg : 20|1@1+ (1,0) [0|1] "" Motor_Diesel,Motor_Hybrid,Motor_Otto
 SG_ GK1_SH_Verbau : 21|1@1+ (1,0) [0|1] "" Motor_Diesel,Motor_Hybrid,Motor_Otto
 SG_ GK1_ParkFrontWi : 22|1@1+ (1,0) [0|1] "" XXX
 SG_ GK1_KW_Warm : 23|1@1+ (1,0) [0|1] "" Motor_Diesel,Motor_Hybrid,Motor_Otto
 SG_ BCM_Remotestart_Betrieb : 24|1@1+ (1,0) [0|1] "" Getriebe_DQ,Getriebe_DQ_Hyb,Motor_Diesel,Motor_Otto
 SG_ BSK_HL_geoeffnet : 26|1@1+ (1,0) [0|1] "" AppGW_SK,Motor_Diesel,Motor_Otto,PDC_PLA
 SG_ BSK_HR_geoeffnet : 27|1@1+ (1,0) [0|1] "" AppGW_SK,Motor_Diesel,Motor_Otto,PDC_PLA
 SG_ GK1_BrLi_links : 29|1@1+ (1,0) [0|1] "" XXX
 SG_ GK1_BrLi_rechts : 30|1@1+ (1,0) [0|1] "" XXX
 SG_ GK1_BrLi_mitte : 31|1@1+ (1,0) [0|1] "" XXX
 SG_ GK1_BLS_ILM : 32|1@1+ (1,0) [0|1] "" XXX
 SG_ GK1_EDC_ILM : 33|1@1+ (1,0) [0|1] "" XXX
 SG_ GK1_Blinker_li : 34|1@1+ (1,0) [0|1] "" AFS,AppGW_SK,LWR,Motor_Diesel,Motor_Otto,PDC_PLA
 SG_ GK1_Blinker_re : 35|1@1+ (1,0) [0|1] "" AFS,AppGW_SK,LWR,Motor_Diesel,Motor_Otto,PDC_PLA
 SG_ GK1_def_P_verr : 36|1@1+ (1,0) [0|1] "" Getriebe_AG6
 SG_ GK1_LS1_Fernlicht : 37|1@1+ (1,0) [0|1] "" AFS,FLA,LWR
 SG_ GK1_Sta_Licht2 : 38|1@1+ (1,0) [0|1] "" AFS
 SG_ GK1_Sta_LSM : 39|1@1+ (1,0) [0|1] "" AFS,FLA,LWR,Motor_Diesel,Motor_Otto,PDC_PLA
 SG_ WI1_Front_Wasch : 40|1@1+ (1,0) [0|1] "" XXX
 SG_ BSK_BT_geoeffnet : 41|1@1+ (1,0) [0|1] "" AppGW_SK,Motor_Diesel,Motor_Otto,PDC_PLA
 SG_ BCM_CV_Taster : 42|1@1+ (1,0) [0|1] "" XXX
 SG_ BSK_HD_Hauptraste : 43|1@1+ (1,0) [0|1] "" Motor_Diesel,Motor_Hybrid,Motor_Otto
 SG_ BSK_Tankklappe : 44|1@1+ (1,0) [0|1] "" Motor_Hybrid
 SG_ EV1_Anf_Klemme_50 : 45|1@1+ (1,0) [0|1] "" Motor_Diesel,Motor_Otto
 SG_ GK1_BrLi_Anhaen : 47|1@1+ (1,0) [0|1] "" XXX
 SG_ GK1_Abblendlicht : 48|1@1+ (1,0) [0|1] "" AFS,AppGW_SK,FLA,LWR
 SG_ GK1_Fernlicht : 49|1@1+ (1,0) [0|1] "" AFS,AppGW_SK,FLA,LWR
 SG_ GK1_Abbl_VL_def : 52|1@1+ (1,0) [0|1] "" AFS
 SG_ GK1_Abbl_VR_def : 53|1@1+ (1,0) [0|1] "" AFS
 SG_ GK1_Blink_Autob : 54|1@1+ (1,0) [0|1] "" XXX
 SG_ GK1_SH_laeuft : 56|1@1+ (1,0) [0|1] "" XXX
 SG_ SH1_ein_Wasserpumpe : 57|1@1+ (1,0) [0|1] "" XXX
 SG_ GK1_Nebel_ein : 58|1@1+ (1,0) [0|1] "" AFS,AppGW_SK,FLA
 SG_ GK1_Bremslicht : 59|1@1+ (1,0) [0|1] "" XXX
 SG_ GK1_Anh_abgesteckt : 60|1@1+ (1,0) [0|1] "" XXX
 SG_ GK1_AnhKonLamp : 61|1@1+ (1,0) [0|1] "" XXX
 SG_ LDS_Stellung_AFL : 62|1@1+ (1,0) [1|1] "" XXX
 SG_ GK1_SH_Zusatzfkt : 63|1@1+ (1,0) [0|1] "" XXX
 SG_ BCM_Offroad_Taster : 25|1@1+ (1,0) [0|1] "" Bremse_ESP_EPB_EBC460Vi,ESP_AU316,Motor_Diesel,Motor_Otto

BO_ 194 mLW_1: 8 XXX
 SG_ LW1_Initquelle : 40|1@1+ (1,0) [0|1] "" Bremse_MK100_ESC,Bremse_MK60EC,Bremse_TRW_ESP,ESP_AU316,Gateway_PQ35,LH_EPS_APA,LH_EPS_ZF_2G
 SG_ LW1_LRW : 0|15@1+ (0.04375,0) [0|1433.55625] "Unit_DegreOfArc" AFS,Allrad,Bremse_ESP_EPB_EBC460Vi,Bremse_MK100_ESC,Bremse_MK60EC,Bremse_TRW_EBC450M,Bremse_TRW_ESP,Daempfer,ESP_AU316,Gateway_PQ35,Getriebe_DL800_R8,Getriebe_DQ,Getriebe_DQ_Hyb,Getriebe_Sele,LH_EPS_APA,LH_EPS_ZF_2G,LWR,Magne_Ride,Motor_Diesel,Motor_Hybrid,Motor_Otto,RKA_Plus
 SG_ LW1_LRW_Sign : 15|1@1+ (1,0) [0|1] "" AFS,Allrad,Bremse_ESP_EPB_EBC460Vi,Bremse_MK100_ESC,Bremse_MK60EC,Bremse_TRW_EBC450M,Bremse_TRW_ESP,Daempfer,ESP_AU316,Gateway_PQ35,Getriebe_DL800_R8,Getriebe_DQ,Getriebe_DQ_Hyb,LH_EPS_APA,LH_EPS_ZF_2G,LWR,Magne_Ride,Motor_Diesel,Motor_Hybrid,Motor_Otto,RKA_Plus
 SG_ LW1_ID : 32|8@1+ (1,0) [0|128] "" Allrad,Bremse_ESP_EPB_EBC460Vi,Bremse_MK100_ESC,Bremse_MK60EC,Bremse_TRW_EBC450M,Bremse_TRW_ESP,ESP_AU316,Gateway_PQ35,LH_EPS_APA,LH_EPS_ZF_2G,LWR,Magne_Ride
 SG_ LW1_Status : 41|2@1+ (1,0) [0|3] "" AFS,Allrad,Bremse_ESP_EPB_EBC460Vi,Bremse_MK100_ESC,Bremse_MK60EC,Bremse_TRW_EBC450M,Bremse_TRW_ESP,Daempfer,ESP_AU316,Gateway_PQ35,Getriebe_DL800_R8,Getriebe_DQ,Getriebe_DQ_Hyb,HCA,LH_EPS_APA,LH_EPS_ZF_2G,LWR,Magne_Ride,Motor_Diesel,Motor_Hybrid,Motor_Otto,RKA_Plus
 SG_ LW1_Sta_KL30 : 43|1@1+ (1,0) [0|1] "" Bremse_ESP_EPB_EBC460Vi,Bremse_MK100_ESC,Bremse_MK60EC,Bremse_TRW_EBC450M,Bremse_TRW_ESP,ESP_AU316,Gateway_PQ35,LH_EPS_APA,LWR,Magne_Ride
 SG_ LW1_Zaehler : 44|4@1+ (1,0) [0|15] "" AFS,Bremse_ESP_EPB_EBC460Vi,Bremse_MK100_ESC,Bremse_MK60EC,Bremse_TRW_EBC450M,Bremse_TRW_ESP,Daempfer,ESP_AU316,Gateway_PQ35,HCA,LH_EPS_APA,LWR,Magne_Ride
 SG_ LW1_CRC : 56|8@1+ (1,0) [0|255] "" AFS,Bremse_ESP_EPB_EBC460Vi,Bremse_MK100_ESC,Bremse_MK60EC,Bremse_TRW_EBC450M,Bremse_TRW_ESP,Daempfer,ESP_AU316,Gateway_PQ35,HCA,LH_EPS_APA,LWR,Magne_Ride
 SG_ LW1_Lenk_Gesch : 16|15@1+ (0.04375,0) [0|1433.55625] "Unit_DegreOfArcPerSecond" Bremse_MK100_ESC,Bremse_MK60EC,Gateway_PQ35,HCA,LH_EPS_APA,LH_EPS_ZF_2G,Magne_Ride
 SG_ LW1_Gesch_Sign : 31|1@1+ (1,0) [0|1] "" Bremse_MK100_ESC,Bremse_MK60EC,Gateway_PQ35,HCA,LH_EPS_APA,LH_EPS_ZF_2G,Magne_Ride
 SG_ LW1_Kodier : 48|8@1+ (1,0) [0|255] "" Gateway_PQ35,LH_EPS_APA

BO_ 1420 mMotor_10: 8 XXX
 SG_ M10_StartStopp_Fahrerwunsch : 44|2@1+ (1,0) [0|3] "" Bremse_MK60EC,Bremse_TRW_ESP,ESP_AU316,Gateway_PQ35,Getriebe_DL800_R8,Getriebe_DQ,Getriebe_DQ_Hyb,PDC_PLA
 SG_ M10_Status_StSt : 8|2@1+ (1,0) [0|3] "" AppGW_SK,Bremse_ESP_EPB_EBC460Vi,Bremse_MK100_ESC,Bremse_MK60EC,Bremse_TRW_EBC450M,Bremse_TRW_ESP,EPB_TRW,ESP_AU316,Gateway_PQ35,Getriebe_DL800_R8,Getriebe_DQ,Getriebe_DQ_Hyb,PDC_PLA
 SG_ M10_Wiederstart : 11|1@1+ (1,0) [0|1] "" AFS,Bremse_ESP_EPB_EBC460Vi,Bremse_MK100_ESC,Bremse_MK60EC,Bremse_TRW_EBC450M,Bremse_TRW_ESP,EPB_TRW,EPB_TRW_VW411CS,ESP_AU316,FLA,Gateway_PQ35,Getriebe_DL800_R8,Getriebe_DQ,Getriebe_DQ_Hyb,LWR,PDC_PLA
 SG_ M10_Anzeige : 0|4@1+ (1,0) [0|15] "" Gateway_PQ35
 SG_ M10_Anf_Kl75 : 4|1@1+ (1,0) [0|1] "" Gateway_PQ35
 SG_ MSG_Remotestart_Betrieb : 5|1@1+ (1,0) [0|1] "" Gateway_PQ35,Getriebe_DQ,Getriebe_DQ_Hyb
 SG_ M10_SpannungsAnf : 6|1@1+ (1,0) [0|1] "" Gateway_PQ35
 SG_ M10_UDruckDyn : 7|1@1+ (1,0) [0|1] "" Bremse_MK60EC,Gateway_PQ35
 SG_ M10_Freigabe_Reku : 14|2@1+ (1,0) [0|3] "" Gateway_PQ35
 SG_ M10_Fahrbereitschaft : 22|1@1+ (1,0) [0|1] "" Bremse_MK60EC,Gateway_PQ35,LH_EPS_ZF_2G,LH_EPS_ZF_3G
 SG_ M10_Hybrid : 23|1@1+ (1,0) [0|1] "" Bremse_MK60EC,Gateway_PQ35,LH_EPS_ZF_2G,LH_EPS_ZF_3G
 SG_ M10_EM_aktiv : 24|1@1+ (1,0) [0|1] "" Gateway_PQ35
 SG_ M10_VM_aktiv : 25|1@1+ (1,0) [0|1] "" Gateway_PQ35
 SG_ M10_HYB_Bereitlampe : 26|1@1+ (1,0) [0|1] "" Gateway_PQ35
 SG_ M10_HYB_Warnlampe : 27|1@1+ (1,0) [0|1] "" Gateway_PQ35
 SG_ M10_HYB_Fehlerlampe : 28|1@1+ (1,0) [0|1] "" Gateway_PQ35
 SG_ M10_Fehler_HV_Netz : 29|1@1+ (1,0) [0|1] "" Gateway_PQ35
 SG_ M10_EKlKomLeiRed : 30|2@1+ (1,0) [0|3] "" Gateway_PQ35
 SG_ M10_Klimadruck : 32|8@1+ (0.2,0) [0|37] "Unit_Bar" Gateway_PQ35
 SG_ M10_KompAusCode : 40|4@1+ (1,0) [0|7] "" Gateway_PQ35
 SG_ M10_Akustik : 46|2@1+ (1,0) [0|3] "" Gateway_PQ35
 SG_ M10_Text_1_Hybrid : 48|1@1+ (1,0) [0|1] "" Gateway_PQ35
 SG_ M10_Text_2_Hybrid : 49|1@1+ (1,0) [0|1] "" Gateway_PQ35
 SG_ M10_Text_3_Hybrid : 50|1@1+ (1,0) [0|1] "" Gateway_PQ35
 SG_ M10_Text_4_Hybrid : 51|1@1+ (1,0) [0|1] "" Gateway_PQ35
 SG_ M10_Text_5_Hybrid : 52|1@1+ (1,0) [0|1] "" Gateway_PQ35
 SG_ M10_Text_6_Hybrid : 53|1@1+ (1,0) [0|1] "" Gateway_PQ35
 SG_ M10_Text_7_Hybrid : 54|1@1+ (1,0) [0|1] "" Gateway_PQ35
 SG_ M10_Text_8_Hybrid : 55|1@1+ (1,0) [0|1] "" Gateway_PQ35
 SG_ M10_ShiftLockLampe : 56|1@1+ (1,0) [0|1] "" Gateway_PQ35
 SG_ MO_Auth_Aufforderung_WFS : 57|1@1+ (1,0) [0|1] "" Gateway_PQ35
 SG_ M10_BMSInfo_gue : 58|1@1+ (1,0) [0|1] "" Gateway_PQ35
 SG_ M10_VentilationReq : 59|1@1+ (1,0) [0|1] "" Gateway_PQ35
 SG_ M10_BattFanSpd : 60|4@1+ (10,0) [0|100] "Unit_PerCent" Gateway_PQ35
 SG_ M10_MotorStopp : 10|1@1+ (1,0) [0|1] "" AFS,AppGW_SK,Bremse_ESP_EPB_EBC460Vi,Bremse_MK100_ESC,Bremse_TRW_EBC450M,EPB_TRW,ESP_AU316,Gateway_PQ35,Getriebe_AG6,Getriebe_DL800_R8,Getriebe_DQ,Getriebe_DQ_Hyb,LWR,PDC_PLA
 SG_ M10_Schubabschaltung : 12|1@1+ (1,0) [0|1] "" Bremse_ESP_EPB_EBC460Vi,Bremse_MK100_ESC,Bremse_MK60EC,Bremse_TRW_EBC450M,Gateway_PQ35
 SG_ M10_Druck_err_gem : 13|1@1+ (1,0) [0|1] "" Bremse_ESP_EPB_EBC460Vi,Bremse_TRW_EBC450M,Gateway_PQ35
 SG_ M10_rel_Saugrohrdruck : 16|6@1+ (18,0) [0|1116] "Unit_MilliBar" Bremse_ESP_EPB_EBC460Vi,Bremse_MK100_ESC,Bremse_MK60EC,Bremse_TRW_EBC450M,Gateway_PQ35

BO_ 1152 mMotor_5: 8 XXX
 SG_ MO5_Motortyp : 0|6@1+ (1,0) [0|63] "" Allrad,AppGW_SK,Bremse_MK100_ESC,Bremse_MK60EC,Bremse_TRW_ESP,Gateway_PQ35,RKA_Plus
 SG_ MO5_Mp_Code : 6|2@1+ (1,0) [0|3] "" Allrad,AppGW_SK,BMS_Hybrid,Bremse_MK100_ESC,Bremse_MK60EC,Bremse_TRW_ESP,Gateway_PQ35,Getriebe_AG6,Getriebe_DL800_R8,Getriebe_DQ,Getriebe_DQ_Hyb,LEH_Hybrid,RKA_Plus
 SG_ MO5_max_Moment : 0|6@1+ (10,0) [0|630] "Unit_NewtoMeter" Gateway_PQ35
 SG_ MO5_Drehzahl : 0|6@1+ (100,0) [0|6300] "Unit_MinutInver" Gateway_PQ35
 SG_ MO5_Abgastyp : 0|1@1+ (1,0) [0|1] "" BMS_Hybrid,Gateway_PQ35,LEH_Hybrid
 SG_ MO5_Abgastyp2 : 1|1@1+ (1,0) [0|1] "" BMS_Hybrid,Gateway_PQ35,LEH_Hybrid
 SG_ MO5_Abgastyp3 : 2|1@1+ (1,0) [0|1] "" Gateway_PQ35
 SG_ OBD_Kaltstart_Denominator : 3|1@1+ (1,0) [0|1] "" BMS_Hybrid,Gateway_PQ35,LEH_Hybrid
 SG_ OBD_Minimum_Trip : 4|1@1+ (1,0) [0|1] "" BMS_Hybrid,Gateway_PQ35,Getriebe_AG6,Getriebe_DL800_R8,Getriebe_DQ,Getriebe_DQ_Hyb,LEH_Hybrid
 SG_ MO5_DPF_reg : 5|1@1+ (1,0) [0|1] "" Gateway_PQ35
 SG_ MO5_Vorgluehen : 9|1@1+ (1,0) [0|1] "" Gateway_PQ35
 SG_ MO5_E_Gas : 10|1@1+ (1,0) [0|1] "" Gateway_PQ35
 SG_ MO5_OBD_2 : 11|1@1+ (1,0) [0|1] "" Gateway_PQ35
 SG_ MO5_Heissl : 12|1@1+ (1,0) [0|1] "" AppGW_SK,Gateway_PQ35
 SG_ MO5_KlimaKompr : 13|1@1+ (1,0) [0|1] "" Gateway_PQ35
 SG_ MO5_Feld_kuehl : 14|1@1+ (1,0) [0|1] "" Gateway_PQ35
 SG_ MO5_KliKo_Red : 15|1@1+ (1,0) [0|1] "" Gateway_PQ35
 SG_ MO5_Verbrauch : 16|15@1+ (1,0) [0|32767] "Unit_MicroLiter" AppGW_SK,Gateway_PQ35
 SG_ MO5_UeberlVerb : 31|1@1+ (1,0) [0|1] "" Gateway_PQ35
 SG_ MO5_Luefter : 32|8@1+ (0.4,0) [0|101.6] "Unit_PerCent" Gateway_PQ35,Getriebe_DL800_R8,Getriebe_DQ,Getriebe_DQ_Hyb
 SG_ MO5_HLeuchte : 40|1@1+ (1,0) [0|1] "" Gateway_PQ35
 SG_ MO5_PartikelLamp : 41|1@1+ (1,0) [0|1] "" Gateway_PQ35
 SG_ MO5_Sta_BKU : 42|1@1+ (1,0) [0|1] "" Gateway_PQ35
 SG_ MO5_TypStartSteu : 43|1@1+ (1,0) [0|1] "" Gateway_PQ35
 SG_ MO5_TDE_Lampe : 44|1@1+ (1,0) [0|1] "" Gateway_PQ35
 SG_ MO5_TDE_Text : 45|1@1+ (1,0) [0|1] "" Gateway_PQ35
 SG_ MO5_DZM_Daempf : 46|1@1+ (1,0) [0|1] "" Gateway_PQ35
 SG_ MO5_Interlock : 47|1@1+ (1,0) [0|1] "" Bremse_ESP_AU714,EPB_TRW_VW411CS,Gateway_PQ35
 SG_ MO5_Start : 48|1@1+ (1,0) [0|1] "" Gateway_PQ35
 SG_ MO5_Anlasser : 49|1@1+ (1,0) [0|1] "" Gateway_PQ35
 SG_ MO5_GRA_Hauptsch : 50|1@1+ (1,0) [0|1] "" Gateway_PQ35
 SG_ MO5_Momente : 51|1@1+ (1,0) [0|1] "" Allrad,Bremse_ESP_AU714,Bremse_MK100_ESC,Bremse_MK60EC,Bremse_MK70MABS,EPB_TRW_VW411CS,Gateway_PQ35,Getriebe_AG6,Getriebe_DL800_R8,Getriebe_DQ,Getriebe_DQ_Hyb,RKA_Plus
 SG_ MO5_Motortext1 : 52|1@1+ (1,0) [0|1] "" Gateway_PQ35
 SG_ MO5_Motortext2 : 53|1@1+ (1,0) [0|1] "" Gateway_PQ35
 SG_ MO5_Motortext3 : 54|1@1+ (1,0) [0|1] "" Gateway_PQ35
 SG_ MO5_Motortext4 : 55|1@1+ (1,0) [0|1] "" Gateway_PQ35
 SG_ MO5_Checksumme : 56|8@1+ (1,0) [0|255] "" Bremse_ESP_AU714,Bremse_MK100_ESC,Bremse_MK60EC,Bremse_MK70MABS,EPB_TRW_VW411CS,Gateway_PQ35,Getriebe_AG6

BO_ 1408 mMotor_Flexia_neu: 8 XXX
 SG_ MFN_Warmup_Cycle : 5|1@1+ (1,0) [0|1] "" BMS_Hybrid,Bremse_TRW_ESP,ESP_AU316,Gateway_PQ35,Getriebe_AG6,Getriebe_DL800_R8,Getriebe_DL800_ZSG_R8,Getriebe_DQ,Getriebe_DQ_Hyb,Getriebe_Sele,LEH_Hybrid
 SG_ MFN_Zaehler : 0|2@1+ (1,0) [0|3] "" Bremse_ESP_AU714,Bremse_ESP_EPB_EBC460Vi,Bremse_TRW_EBC450M,Bremse_TRW_ESP,EPB_TRW,EPB_TRW_VW411CS,ESP_AU316,Gateway_PQ35
 SG_ MFN_Zaehler_278 : 2|2@1+ (1,0) [0|3] "" Bremse_ESP_AU714,Bremse_ESP_EPB_EBC460Vi,Bremse_TRW_EBC450M,Bremse_TRW_ESP,EPB_TRW,EPB_TRW_VW411CS,ESP_AU316,Gateway_PQ35
 SG_ MFN_Verbrenn_Typ : 7|1@1+ (1,0) [0|1] "" Bremse_ESP_AU714,Bremse_ESP_EPB_EBC460Vi,Bremse_TRW_EBC450M,Bremse_TRW_ESP,EPB_TRW,EPB_TRW_VW411CS,ESP_AU316,Gateway_PQ35,Getriebe_AG6,Getriebe_DL800_R8,Getriebe_DQ,Getriebe_DQ_Hyb
 SG_ MFN_Motorleistung : 40|9@1+ (1,0) [0|511] "Unit_KiloWatt" Bremse_ESP_AU714,Bremse_ESP_EPB_EBC460Vi,Bremse_TRW_EBC450M,Bremse_TRW_ESP,EPB_TRW,ESP_AU316,Gateway_PQ35
 SG_ MFN_Motorleistung_281 : 40|9@1+ (1,0) [0|511] "Unit_KiloWatt" Bremse_ESP_AU714,Bremse_ESP_EPB_EBC460Vi,Bremse_TRW_EBC450M,Bremse_TRW_ESP,EPB_TRW,ESP_AU316,Gateway_PQ35
 SG_ MFN_Hubraum : 56|7@1+ (0.1,0) [0|12.7] "Unit_Liter" Bremse_ESP_AU714,Bremse_ESP_EPB_EBC460Vi,Bremse_TRW_EBC450M,Bremse_TRW_ESP,EPB_TRW,ESP_AU316,Gateway_PQ35
 SG_ MFN_Hubraum_283 : 56|7@1+ (0.1,0) [0|12.7] "Unit_Liter" Bremse_ESP_AU714,Bremse_ESP_EPB_EBC460Vi,Bremse_TRW_EBC450M,Bremse_TRW_ESP,EPB_TRW,ESP_AU316,Gateway_PQ35
 SG_ MFN_Drive_Cycle : 4|1@1+ (1,0) [0|1] "" BMS_Hybrid,Gateway_PQ35,Getriebe_AG6,Getriebe_DL800_R8,Getriebe_DL800_ZSG_R8,Getriebe_DQ,Getriebe_DQ_Hyb,Getriebe_Sele,LEH_Hybrid
 SG_ MFN_NormedTrip : 6|1@1+ (1,0) [0|1] "" BMS_Hybrid,Gateway_PQ35,Getriebe_AG6,Getriebe_DL800_R8,Getriebe_DL800_ZSG_R8,Getriebe_DQ,Getriebe_DQ_Hyb,Getriebe_Sele,LEH_Hybrid
 SG_ MFN_Russindex : 8|16@1+ (0.00000002,0) [0|0.00131068] "" Gateway_PQ35
 SG_ MFN_Verschl : 8|16@1+ (0.00000002,0) [0|0.00131068] "" Gateway_PQ35
 SG_ MFN_Russindex_1488 : 8|16@1+ (0.00000002,0) [0|0.00131068] "" Gateway_PQ35
 SG_ MFN_Verschl_1489 : 8|16@1+ (0.00000002,0) [0|0.00131068] "" Gateway_PQ35
 SG_ MFN_Drz_max_Mo : 24|8@1+ (100,0) [0|25500] "Unit_MinutInver" Gateway_PQ35
 SG_ MFN_KurzzeitMW : 24|8@1+ (15,-1905) [-1890|1905] "Unit_MilliLiter" Gateway_PQ35
 SG_ MFN_Drz_max_Mo_1492 : 24|8@1+ (100,0) [0|25500] "Unit_MinutInver" Gateway_PQ35
 SG_ MFN_Interv_Wmin : 24|7@1+ (1000,0) [0|127000] "Unit_KiloMeter" Gateway_PQ35
 SG_ MFN_Fuell_Erk : 31|1@1+ (1,0) [0|1] "" Gateway_PQ35
 SG_ MFN_max_Moment : 32|8@1+ (10,0) [0|2550] "Unit_NewtoMeter" Gateway_PQ35
 SG_ MFN_Oelstand : 32|6@1+ (1,0) [0|63] "" Gateway_PQ35
 SG_ MFN_max_Moment_1497 : 32|8@1+ (10,0) [0|2550] "Unit_NewtoMeter" Gateway_PQ35
 SG_ MFN_Interv_Wmax : 32|7@1+ (1000,0) [0|127000] "Unit_KiloMeter" Gateway_PQ35
 SG_ MFN_Oelwarnung : 38|1@1+ (1,0) [0|1] "" Gateway_PQ35
 SG_ MFN_Sensorwarn : 39|1@1+ (1,0) [0|1] "" Gateway_PQ35
 SG_ MFN_MaxOelst : 39|5@1+ (100,0) [0|3100] "Unit_MilliLiter" Gateway_PQ35
 SG_ MFN_AnzMitOel : 40|4@1+ (100,0) [0|1500] "" Gateway_PQ35
 SG_ MFN_Max_Offset : 44|4@1+ (50,0) [0|750] "Unit_MilliLiter" Gateway_PQ35
 SG_ MFN_Anz_Mittel : 44|4@1+ (500,0) [500|7500] "" Gateway_PQ35
 SG_ MFN_Fuell_Hyst : 48|4@1+ (50,0) [0|750] "Unit_MilliLiter" Gateway_PQ35
 SG_ MFN_Interv_tmin : 48|6@1+ (1,0) [0|63] "Unit_Month" Gateway_PQ35
 SG_ MFN_Ventile : 49|3@1+ (1,0) [0|7] "" Gateway_PQ35
 SG_ MFN_Ventile_1508 : 49|3@1+ (1,0) [0|7] "" Gateway_PQ35
 SG_ MFN_Offset_Nachf : 52|6@1+ (10,0) [0|630] "Unit_MilliLiter" Gateway_PQ35
 SG_ MFN_Interv_tmax : 54|6@1+ (1,0) [0|63] "Unit_Month" Gateway_PQ35
 SG_ MFN_Tol_Oelwarn : 58|6@1+ (10,0) [0|630] "Unit_MilliLiter" Gateway_PQ35
 SG_ MFN_Str_Mittel : 60|4@1+ (25,0) [25|375] "Unit_KiloMeter" Gateway_PQ35
 SG_ MFN_Ansaugsys : 63|1@1+ (1,0) [0|1] "" Bremse_ESP_AU714,Gateway_PQ35
 SG_ MFN_Ansaugsys_1514 : 63|1@1+ (1,0) [0|1] "" Bremse_ESP_AU714,Gateway_PQ35
 SG_ MFN_Zylinder : 52|4@1+ (1,0) [0|15] "" Bremse_ESP_AU714,Bremse_ESP_EPB_EBC460Vi,EPB_TRW,ESP_AU316,Gateway_PQ35
 SG_ MFN_Zylinder_2161 : 52|4@1+ (1,0) [0|15] "" Bremse_ESP_EPB_EBC460Vi,EPB_TRW,ESP_AU316,Gateway_PQ35

CM_ "Generated from VW PQ35_46 ACAN KMatrix V5.20.6F, 2016-05-30.";
CM_ SG_ 1827 NMH_ABS_Start_1 "Zustand Start (<--Sleep)";
CM_ SG_ 1827 NMH_ABS_Start_2 "Zustand Start (<--Prepare to Sleep)";
CM_ SG_ 1827 NMH_ABS_Normal_Mode_1 "Zustand Normal Mode (<-- Start)";
CM_ SG_ 1827 NMH_ABS_Normal_Mode_2 "Zustand Normal Mode (<-- Ready to Sleep)";
CM_ SG_ 1827 NMH_ABS_Per_WakeUp "Weckurasche Peripherie | 0 = wenn Funktionswakeup | 1 = CAN | 2 = P-Wakeup, Ursache nicht bekannt | 3 = KL 15 HW (falls vorhanden)";
CM_ SG_ 1827 NMH_ABS_Fkt_WakeUp "\"Weckursache Funktion\" | 0 = wenn Peripheriewakeup";
CM_ SG_ 1827 NMH_ABS_NM_aktiv_Klemme_15 "NM-Nachlaufursache, nicht \"Ready To Sleep\" | 1 = Klemme 15 ein";
CM_ SG_ 1827 NMH_ABS_NM_aktiv_Diagnose "NM-Nachlaufursache, nicht \"Ready To Sleep\" | 1 = Diagnose bei Kl 15 aus";
CM_ SG_ 1827 NMH_ABS_NM_aktiv_Start "NM-Nachlaufursache, nicht \"Ready To Sleep\" | 1 = Mindestaktivzeit Zustand \"Start\"";
CM_ SG_ 1827 NMH_ABS_NL_aktiv_4 "Nachlaufursache 4 | 1 = kein Stillstand aller Raeder erkannt";
CM_ SG_ 1827 NMH_ABS_TimeOut_Fehler "1 = Timeout Fehlerspeichereintrag";
CM_ SG_ 1827 NMH_ABS_CAN_Diag_deaktiv "1 = Keine CAN Bus bezogene Eigendiagnose";
CM_ SG_ 1827 NMH_ABS_KompSchutz "1 = Funktionseinschraenkung aufgrund Komponentenschutz / WFS aktiv";
CM_ SG_ 1827 NMH_ABS_Mute_Mode "1 = Funktionseinschraenkung aufgrund Mute Mode aktiv, nur VW";
CM_ SG_ 1827 NMH_ABS_Transport_Mode "1 = Funktionseinschraenkung aufgrund Transport Mode aktiv";
CM_ SG_ 1827 NMH_ABS_Abschaltstufe_aktiv "1 = Funktionsabschaltung wegen Abschaltstufe";
CM_ SG_ 1827 NMH_ABS_Eindraht_Fehler "1 = Eindrahtbetrieb erkannt";
CM_ SG_ 1827 NMH_ABS_Car_WakeUp "Car WakeUp optional";
CM_ SG_ 1827 NMH_ABS_NL_aktiv_5 "Nachlaufursache 5";
CM_ SG_ 1827 NMH_ABS_NL_aktiv_6 "Nachlaufursache 6";
CM_ SG_ 1827 NMH_ABS_NL_aktiv_7 "Nachlaufursache 7";
CM_ SG_ 1827 NMH_ABS_NL_aktiv_8 "Nachlaufursache 8";
CM_ SG_ 1827 NMH_ABS_NL_0 "Nachlauf 0";
CM_ SG_ 1827 NMH_ABS_NL_1 "Nachlauf 1";
CM_ SG_ 1827 NMH_ABS_NL_2 "Nachlauf 2";
CM_ SG_ 1827 NMH_ABS_NL_3 "Nachlauf 3";
CM_ SG_ 1827 NMH_ABS_NL_4 "Nachlauf 4";
CM_ SG_ 1827 NMH_ABS_NL_5 "Nachlauf 5";
CM_ SG_ 1827 NMH_ABS_NL_6 "Nachlauf 6";
CM_ SG_ 1827 NMH_ABS_NL_7 "Nachlauf 7";
CM_ SG_ 768 TPDyn_Diag_1_1 "Tester | TP 2.0 Empfangskanal 1 fuer Tester";
CM_ SG_ 769 TPDyn_Diag_1_2 "Tester | TP 2.0 Empfangskanal 2 fuer Tester";
CM_ SG_ 770 TPDyn_Diag_1_3 "Tester | TP 2.0 Empfangskanal 3 fuer Tester";
CM_ SG_ 771 TPDyn_Diag_1_4 "Tester | TP 2.0 Empfangskanal 4 fuer Tester";
CM_ SG_ 772 TPDyn_Diag_1_5 "Tester | TP 2.0 Empfangskanal 5 fuer Tester";
CM_ SG_ 773 TPDyn_Diag_1_6 "Tester | TP 2.0 Empfangskanal 6 fuer Tester";
CM_ SG_ 774 TPDyn_Diag_1_7 "Tester | TP 2.0 Empfangskanal 7 fuer Tester";
CM_ SG_ 775 TPDyn_Diag_1_8 "Tester | TP 2.0 Empfangskanal 8 fuer Tester";
CM_ SG_ 515 ABS_TP_Er "TP 2.0 Eroeffnungskanal";
CM_ SG_ 1440 BR2_Blinkmode "Bremskontroll-Lampe soll im Warnfall mit 1Hz blinken, wenn das Bit gesetzt ist (z. Zt. nur bei VW) (nicht D1GP/BY61x/MK70 alt)";
CM_ SG_ 1440 BR2_Querbeschl "Wenn BR2_Querb_Zahn = 0: errechnete Groesse (bei ABS-Systemen) zur Kurvenfahrterkennung fuer das Getriebe, oder gemessener Sensorwert (sieheBR2_Sta_Quer) (im PQ35 kein Rohwert). Bei Linkskurve positives Vorzeichen. | Achtung: Die Guete bei errechneten Groessen (z. B. bei MK70 neu) kann situationsbedingt sehr schlecht sein! | | ESC-Systeme: 0xFF bedeutet Querbeschleunigungs-Sensor defekt. | | ABS-Systeme: 0x7F (= Initwert entspricht physikalisch 0 g, mit gesetztem Q-Bit) die Groesse kann fahrsituationsbedingt nicht berechnet werden (z. b. ABS-Regelung, v < X km/h) / | 0xFF (mit gesetztem Q-Bit) bedeutet hier die Groesse kann aufgrund im System vorliegender Fehler nicht berechnet werden. | Hinweis: ABS TRW EBC460 sendet noch bis KW22/14 0xFF, wenn die Groesse fahrsituationsbedingt nicht berechnet werden kann.";
CM_ SG_ 1440 BR2_Zahnzahl "Wenn Byte 2, Bit 0 = 1: Zaehnezahl des verwendeten Impulsrades";
CM_ SG_ 1440 BR2_Querb_Zahn "Byte 1 hat in der Hochlaufphase (Boschsystem: ca. 2s, Contisystem: ca. 1,7s) eine alternative Bedeutung: Zaehnezahl der Impulsraeder werden uebertragen | Querbeschl./Zaehnezahl";
CM_ SG_ 1440 BR2_mi_Radgeschw "Radumdrehungen / Sekunde sind Eingangsgroesse fuer die Geschwindigkeitsberechnung im Kombi; es wird der Mittelwert der permanent angetriebenen Raeder (alle ausser Audi B6/D3) ausgegeben oder bei Audi B6/D3 die Geschwindigkeit des linken Vorderrades; im Kombi wird aus dieser Raddrehzahl und dem Radumfang die Fahrzeuggeschwindigkeit errechnet | RPU: 4*2 Mittelwert HA , 4*4 zuschaltbar (starr) Mittelwert der HA , 4*4 Torsen Mittelwert aller Raeder | T5GP: 4*2 Mittelwert VA, 4*4 Haldex Mittelwert VA;;Konstanten: | V_INIT = 7FC4H (bzw. FF88H oder FF89H = 1111 1111 1000 100x B in 2-Byte-Schreibweise) (entspricht 65416 1/s) | V_Uspg = 7FD5H (bzw. FFAAH oder FFABH = 1111 1111 1010 101x B in 2-Byte-Schreibweise) (entspricht 65450 1/s) | V_Fehler = 7FE6H (bzw. FFCCH oder FFCDH = 1111 1111 1100 110x B in 2-Byte-Schreibweise) (entspricht 65484 1/s) | mittlere Raddrehzahl (Bremse 2)";
CM_ SG_ 1440 BR2_Lampe_ABS "Sicherheitswarnlampe, siehe Bremse_1 Byte 2, Bit 0 (nicht D1GP/BY61x/MK70 alt)";
CM_ SG_ 1440 BR2_Lampe_ASR "Zustand der Lampe wird auf dem CAN-Bus ausgegeben (auch Blinkinformation) | Fahrzeuge mit ASR/ESP/MABS-Funktionalitaet bedienen die Sicherheitswarnlampe | Init: 0 (ABS)/1 (ASR/ESP SILA), siehe Bremse_1 Byte 2, Bit 1 (nicht D1GP/BY61x/MK70 alt)";
CM_ SG_ 1440 BR2_Lampe_BK "(Blinktakt wird nur bei Audi wie bisher vom Kombi generiert) | Separate Bremskontroll-Lampe (Audi ab D3/C6) wird als Sicherheitswarnlampe aufgeprueft (Initwert 1) | Kombinierte Bremskontroll-Lampe (VW) wird aufgeprueft, siehe Bremse_1 Byte 2, Bit 2 Zustand der Lampe wird auf dem CAN-Bus ausgegeben (auch Blinkinformation) | Fahrzeuge mit ASR/ESP/MABS-Funktionalitaet bedienen die Sicherheitswarnlampe | Init: 0 (ABS)/1 (ASR/ESP SILA), siehe Bremse_1 Byte 2, Bit 1 (nicht D1GP/BY61x/MK70 alt) | Bremskontroll-Lampe";
CM_ SG_ 1440 BR2_Lampe_RKA "Reifen-Kontroll-Anzeige (indirekt messende Reifendruckueberwachung): siehe Bremse_4 Byte 4, Bit 0 Zustand der Lampe wird auf dem CAN-Bus ausgegeben (auch Blinkinformation) | Fahrzeuge mit ASR/ESP/MABS-Funktionalitaet bedienen die Sicherheitswarnlampe | Init: 0 (ABS)/1 (ASR/ESP SILA), siehe Bremse_1 Byte 2, Bit 1 (nicht D1GP/BY61x/MK70 alt)";
CM_ SG_ 1440 BR2_Zaehler "Ueberlaufender Zaehler (nicht D1GP/BY61x/MK70 alt)";
CM_ SG_ 1440 BR2_Text "0 Kein Text | 1 \"ESP Stoerung\" | 2 \"ABS Stoerung\" | 3 \"ESP/ABS Stoerung\" | 4 \"Werkstatt Bremse\" | 5 \"ASR Stoerung\" | 6 \"ESP Deaktiviert\", nur Audi A1 \"ESP SPORT\" | 7 \"ASR Deaktiviert\", nur Audi A1 \"ESP OFF\", Q3 \"ESP OFFROAD\" | 8 \"ESP Aktiviert\" | 9 \"Stoerung Hillholder\" (PQ46) \"Anfahrhilfe Fehler Werkstatt\" (T5GP) | 10 \"Keine Bremskraftverstaerkung\" | 11 \"ASR aktiviert\" | 12 \"ABS/ASR Stoerung\" | 13 \"Bitte Reifen pruefen\" | 14 \"ESP Sport\", nur Audi Q3 \"ESP OFF\" | 15 Reserviert | (nicht D1GP/BY61x/MK70 alt)";
CM_ SG_ 1440 BR2_Aku_Warn "1: Bremse steuert den Gong im Kombi ein Mal an (keine Akustik bei VW) | 2: Bremse steuert den Gong (Summer bei VW) im Kombi drei Mal an, z. Zt. nur in Kombination mit Text \"Werkstatt Bremse\" (Ausfall der EBV) | 3: Summeransteuerung ist durch Kombi auf 1 Sekunde festgelegt. Ausloesung durch 0 -> 1 Flanke. (bei VW: gelbe Warnung) | (nicht D1GP/BY61x/MK70 alt)";
CM_ SG_ 1440 BR2_HDC_aktiv "Die Funktion Bergabfahrassistent ist bei gesetztem Bit aktiv oder standby. | Das Motor SG nutzt Info zum Umschalten der GRA Funktion. | Das DQ-Getriebe nutzt die Info zur Kupplungsansteuerung. | | VW316/RPU: Bit=1 heisst HDC Standby oder aktiv | VW472 Cross: Bit=1, wenn HDC-Bremseneingriff aktiv | (nicht D1GP/BY61x/MK70 alt)";
CM_ SG_ 1440 BR2_Wegimpulse "Anzahl der Raddrehzahlimpulse (steigende und fallende Flanke) der Vorderachse (gemittelt) zur Wegstreckenzaehlung | bei Ausfall eines Drehzahlfuehlers wird der funktionsfaehige Sensor zur Ausgabe verwendet | Wegimpulse Vorderachse | | Im RPU wird die Hinterachse zur Ermittlung der Wegimpulse verwendet!";
CM_ SG_ 1440 BR2_Ueberl_Imp "der Wegimpuls-Zaehler ist mindestens einmal uebergelaufen (Reset des ABS-Steuergeraetes) kann damit erkannt werden | Wegimpulszaehlerstatus";
CM_ SG_ 1440 BR2_Fehlereintr "Bei gesetztem Bit ist mindestens ein Kundendienstfehler eingetragen";
CM_ SG_ 1440 BR2_LampeHDC "VW316/VW472 Cross: Funktionslampe Bergabfahrassistent (HDC) | Lampe ist an bei HDC im standby und blinkt mit 3,3 Hz bei aktiver Funktion. | Das DQ-Getriebe nutzt die Info zur Kupplungsansteuerung. | | RPU: Funktionslampe Bergabfahrassistent und Offroad-ABS | MK25A-ESP: Lampe ist an bei HDC im standby und blinkt mit 3,3 Hz bei aktiver Funktion (jeweils bis 30 km/h). | Oberhalb von 30 km/h leuchtet die Lampe dauerhaft (ab KW15/10). | MK25E-ABS: Funktionslampe Offroad-ABS | Lampe leuchtet dauerhaft (ab KW15/10) | | (ACHTUNG: war Lampe Reifendruckwarnung RB im PQ24)";
CM_ SG_ 1440 BR2_QB_Querbeschl "Definition nach CAN-Lastenheft | Hinweis zu CT-ESP: Bit wird auch gesetzt, wenn Querbeschl. bei ESP errechnet statt gemessen wird (nicht Colorado/Colorado GP, nicht D1GP/BY61x) | (ACHTUNG: war Summer Reifendruckwarnung RB im PQ24 und \"Status Bremsassistent\" im T5)";
CM_ SG_ 1440 BR2_Sta_Imp "Fehler wird gesetzt, wenn beide ABS-Drehzahlfuehler an der Vorderachse defekt sind | Fehlerstatus Wegimpulse | | Im RPU wird die Hinterachse zur Ermittlung der Wegimpulse verwendet!";
CM_ SG_ 1440 BR2_Impulszahl "Zaehnezahl des verwendeten Impulsrades";
CM_ SG_ 1440 BR2_SleepInd "Die Sleep-Bereitschaft wird nach Klemme 15 aus durch Setzen dieses Bits signalisiert (nicht VW D1/Colorado, nicht D1GP/BY61x, nicht RB PQ25) | NMHigh-Teilnehmer der PQ35/46 muessen das Signal nach Kl.-15 aus weiterhin bedienen oder dauerhaft auf 1 = 'Sleep bereit' setzen!";
CM_ SG_ 1440 BR2_Sta_Quer "Querbeschleunigung in Byte 1 wird errechnet oder beim ESP gemessen";
CM_ SG_ 416 BR1_ASR_Anf "Anforderungen in Byte 5 und 6 sind auszufuehren";
CM_ SG_ 416 BR1_MSR_Anf "Anforderung in Byte 7 ist auszufuehren; Byte 6 aendert seine Bedeutung, wenn dieses Bit gesetzt ist | MSR Anforderung";
CM_ SG_ 416 BR1_ABS_Brems "Antiblockiersystem, Bit zeigt auch Druckabbau an (z.B. ESP hat zuviel Druck aufgebaut oder ungebremste Regelung auf Bahnuebergang)";
CM_ SG_ 416 BR1_EDS_Eingr "Elektronische Differentialsperre | EDS Eingriff";
CM_ SG_ 416 BR1_ESP_Eingr "Fahrdynamikregelung | ESP Eingriff";
CM_ SG_ 416 BR1_ASR_Eingr "Wunsch an das Getriebe waehrend einer ASR Regelung, bei Audi nur 00 und 01 genutzt | ASR-Schaltbeeinflussung";
CM_ SG_ 416 BR1_EBV_Eingr "Elektronische Bremskraftverteilung, aktueller Eingriff (Druckhalten, Druckabbau), kein ABS / ESP-Eingriff | EBV Eingriff";
CM_ SG_ 416 BR1_Lampe_ABS "Sicherheitswarnlampe | Lampe ABS";
CM_ SG_ 416 BR1_Lampe_ASR "Zustand der Lampe wird auf dem CAN-Bus ausgegeben (auch Blinkinformation) | Fahrzeuge mit ASR/ESP/MABS-Funktionalitaet bedienen die Sicherheitswarnlampe | Init: 0/1(SILA) | Lampe ASR / ESP";
CM_ SG_ 416 BR1_Lampe_BK "rote Lampe wird angesteuert, z. B. bei EBV-Ausfall;(Sicherheitswarnlampe im Audi C6/D3, AU716 mit Initwert 1) | Bremskontroll-Lampe";
CM_ SG_ 416 BR1_Lichtschalt "ohne aktiven BKV wird hier der Bremslichtschalter (0 kein Bremsen, 1 Bremse betaetigt) uebertragen (ESP5.7, ESP 8, Mk60, T5GP/RPU(MK25A XT)) | ab PQ46 (mit Einsatz des einkanaligen Hall-BLS): Fahrer hat durch Pedalbetaetigung die Bremsdruckschwelle ueberschritten (nicht ACC oder EPB-Bremsung) | Im Colorado: Info wird erkannt, wenn der Fahrer einen aktiven BKV uebertritt (Loeseschalterinformation plus Plausibilitaet) | Nur im Porsche Cayenne wird das Bit auch bei Gespannstabilisierungseingriff gesetzt. | Bremslichtschalter / Bremsdruckschwelle ueberschritten";
CM_ SG_ 416 BR1_StaDruckschw "beim Bosch-ABS wird der Bremstestschalter (0 kein Bremsen, 1 Bremse betaetigt) uebertragen (D1GP/BY61x u. T5GP/RPU(MK25A XT) | ab PQ46: Druckschwelleninformation (Byte 2, Bit 3) kann noch nicht oder aufgrund eines Fehlers nicht ausgegeben werden (nicht Colorado) | Bei einem aktiven BKV wird im angesteuerten Zustand (z.B. bei ESP-Eingriff oder ADR-Bremsung) ohne Beeinflussung des Fahrers das Bremspedal betaetigt. In Byte 2, Bit 3 ist ersichtlich, ob der Fahrer den aktiven BKV uebertritt (im Colorado/T5GP). | Bremstestschalter / Druckschwellenstatus nicht verfuegbar / Status aktiver BKV";
CM_ SG_ 416 BR1_Diagnose "Kombi unterdrueckt z.B. den Gong | ABS-Diagnose";
CM_ SG_ 416 BR1_Rad_kmh "Low Byte 3, High Byte 4 (Aufloesung 1,28 km/h) | Bremse holt sich den Radumfang aus der Botschaft 'Kombi_3' | generell wird Mittelwert (alle ausser B6/D3) der permanent angetriebenen Raeder ausgegeben (d.h. bei Frontantrieb und gesteuertem Allrad (Haldex) Mittelwert der Vorderraeder, bei Allrad Mittelwert der 4 Raeder) oder bei Audi B6/D3 die Geschwindigkeit des linken Vorderrades, bei MSR oder ABS Eingriffen wird die ABS-Referenzgeschwindigkeit fuer >=200 msec eingespiegelt (Zeit wird mit Aktiv-Flanke getriggert). Beim Sensorfehler ist im ABS-SG ein Fehler gespeichert; Contiteves liefert sofort gueltige Werte | | RPU: 4*2 Mittelwert HA , 4*4 zuschaltbar (starr) Mittelwert der HA , 4*4 Torsen Mittelwert aller Raeder | T5GP: 4*2 Mittelwert VA, 4*4 Haldex Mittelwert VA | | Konstanten: | V_INIT = 7FC4H (bzw. FF88H oder FF89H = 1111 1111 1000 100x B in 2-Byte-Schreibweise) (entspricht 327,08 km/h) (nicht Colorado, D1GP/BY61x) | V_Uspg = 7FD5H (bzw. FFAAH oder FFABH = 1111 1111 1010 101x B in 2-Byte-Schreibweise) (entspricht 327,25 km/h) (nicht D1GP/BY61x) | V_Fehler = 7FE6H (bzw. FFCCH oder FFCDH = 1111 1111 1100 110x B in 2-Byte-Schreibweise) (entspricht 327,42 km/h) (nicht D1GP/BY61x) | Geschwindigkeit (Bremse 1)";
CM_ SG_ 416 BR1_ASRMo_fa "falls Byte 1, Bit 1 gleich 0;Achtung: Fehlerwert FFH wird nur benutzt, wenn es ein ASR-Eingriffsmoment ist - nicht beim bitinvertierten MSR-Moment;Hinweis T5GP/RPU: Bei zweikanaliger Anforderung muss Bremsensteuergeraet die Zuendwinkelreserve aus mMotor_2 Byte 8 auswerten. | | Hybrid: Interpretiert als Reduktion Summenmoment VM+EM | ASR Eingriffsmoment schnell";
CM_ SG_ 416 BR1_MSR_Mo_inv "falls Byte 1, Bit 1 gleich 1 | inverses MSR Eingriffsmoment";
CM_ SG_ 416 BR1_MSR_Mo "Hybrid: Interpretiert als Summenmoment VM+EM | MSR Eingriffsmoment";
CM_ SG_ 416 BR1_Zaehler "ueberlaufender Botschaftszaehler, um Eingriffsmoment als aktualisiert zu kennzeichnen | Zaehler (Bremse 1)";
CM_ SG_ 416 BR1_ASR_ESP "Kombi kann ggfs. die Lampe ansteuern | ASR/ESP-Steuergeraet";
CM_ SG_ 416 BR1_ESPASR_passiv "ESP oder ASR (oder beides, oder Teilfunktionen, solange Fahrer nicht bremst) vom Fahrer passiv getastet oder ASR/ESP Funktionsumschaltung oder ueber Rollenmodus deaktiviert";
CM_ SG_ 416 BR1_Sta_ESP "Steht fuer Stilllegung ESP mit Fehlerspeichereintrag. | Wird in TRW-Projekten auch im Rollenmodus und waehrend Nachlauf gesetzt.";
CM_ SG_ 416 BR1_Ersatz_Kmh "Geschwindigkeit wird als Ersatzwert ausgegeben (z.B. ein Sensor defekt, kein Radumfang gelernt, kein oder fehlerhafter Radumfang vom Kombi empfangen oder bei Contiteves und passiven Sensoren wird Hinterrad eingespiegelt) | Geschwindigkeits-Ersatzwert";
CM_ SG_ 416 BR1_MAD "OBD-Funktion (MAD-Signal), wird bei Teves / TRW z.Zt. nicht ausgegeben | Schlechtwegausblendung";
CM_ SG_ 416 BR1_Sta_MAD "ESP 5.7: Im ESP-Fehlerfall ist Bit \"ungueltig\" | ESP 8: Im ESP-Fehler ist Bit weiterhin \"gueltig\" | Initwert \"0\" wird gesendet, wenn Funktion umgesetzt | Initwert \"1\" wird gesendet, wenn Funktion nicht umgesetzt | Fehlerstatus Schlechtwegausblendung";
CM_ SG_ 416 BR1_BKV_aktiv "neues Status-Bit zur Vermeidung von Problemen waehrend der Uebergangszeit auf die neue Definition (BKV) und zur Darstellung des Fehlerzustandes: nur noch in T5 und im Colorado | Aktiver Bremskraftverstaerker";
CM_ SG_ 416 BR1_ASRMo_sl "wird in TRW Projekten nicht bedient (es wird 0 gesendet) | | Hybrid: | Interpretiert als Reduktion Summenmoment VM+EM | ASR Eingriffsmoment langsam";
CM_ SG_ 928 B10_Checksumme "Pruefsumme mit Endwert 0x0, Definition im CAN Lastenheft (HS-CAN V4.2a, LS-CAN V1.42)";
CM_ SG_ 928 B10_Zaehler "Ueberlaufender Botschaftszaehler, zur Lebenderkennung";
CM_ SG_ 928 B10_QB_Wegimp_VL "Definition nach CAN-Lastenheft | Qualifizierungsbit Wegimpulse VL";
CM_ SG_ 928 B10_QB_Wegimp_VR "Definition nach CAN-Lastenheft | Qualifizierungsbit Wegimpulse VR";
CM_ SG_ 928 B10_QB_Wegimp_HL "Definition nach CAN-Lastenheft | Qualifizierungsbit Wegimpulse HL";
CM_ SG_ 928 B10_QB_Wegimp_HR "Definition nach CAN-Lastenheft | Qualifizierungsbit Wegimpulse HR";
CM_ SG_ 928 B10_Wegimp_VL "Anzahl der Wegimpulse Vorderrad links (steigende und fallende Flanke) | Zaehler laeuft grundsaetzlich vorwaerts, auch bei Rueckwaertsfahrt";
CM_ SG_ 928 B10_Wegimp_VR "Anzahl der Wegimpulse Vorderrad rechts (steigende und fallende Flanke) | Zaehler laeuft grundsaetzlich vorwaerts, auch bei Rueckwaertsfahrt";
CM_ SG_ 928 B10_Wegimp_HL "Anzahl der Wegimpulse Vorderrad links (steigende und fallende Flanke) | Zaehler laeuft grundsaetzlich vorwaerts, auch bei Rueckwaertsfahrt";
CM_ SG_ 928 B10_Wegimp_HR "Anzahl der Wegimpulse Vorderrad links (steigende und fallende Flanke) | Zaehler laeuft grundsaetzlich vorwaerts, auch bei Rueckwaertsfahrt";
CM_ SG_ 928 B10_QB_Fahrtr_VL "Definition nach CAN-Lastenheft | Qualifizierungsbit Fahrtrichtung VL";
CM_ SG_ 928 B10_QB_Fahrtr_VR "Definition nach CAN-Lastenheft | Qualifizierungsbit Fahrtrichtung VR";
CM_ SG_ 928 B10_QB_Fahrtr_HL "Definition nach CAN-Lastenheft | Qualifizierungsbit Fahrtrichtung HL";
CM_ SG_ 928 B10_QB_Fahrtr_HR "Definition nach CAN-Lastenheft | Qualifizierungsbit Fahrtrichtung HR";
CM_ SG_ 928 B10_Fahrtr_VL "Fahrtrichtungserkennung Vorderrad links";
CM_ SG_ 928 B10_Fahrtr_VR "Fahrtrichtungserkennung Vorderrad rechts";
CM_ SG_ 928 B10_Fahrtr_HL "Fahrtrichtungserkennung Hinterrad links";
CM_ SG_ 928 B10_Fahrtr_HR "Fahrtrichtungserkennung Hinterrad rechts";
CM_ SG_ 1463 B11_HydHalten "Das Bit wird gesetzt, wenn das Fahrzeug durch den Berganfahrassistenten (Hill-Hold) oder PLA gehalten wird. | Hydraulisches Halten aktiv (nur in Verbindung mit Autohold) | Wird im TRW-Projekt EBC460 auch ohne Autohold bedient. | Im Conti-Projekt MK100 (T6 und Caddy4) gilt: | Das Bit wird gesetzt, wenn das Fahrzeug durch eine Bremsenanforderung wie z.B. HHC, ACC oder PLA im Stillstand hydraulisch gehalten wird.";
CM_ SG_ 1463 B11_Br_StSt_Info "Stopp-Freigabe/Start-Anforderung fuer den Start-Stopp-Koordinator | (Nicht Start/Stopp-faehige Bremsen-SGs senden die Bremse 11-Botschaft nicht oder konstant den Wert 3 Systemfehler -> Start/Stopp wird durch den Koordinator gesperrt.)";
CM_ SG_ 1463 B11_OBD_Nib_VL "Fehlerstatus des Radsensors vorne links | Da im MSG v-Fhz eine OBD-relevante Groesse ist, muessen im Fehlerfall erweiterte Diagnoseinformationen zur Signalquelle mittels GST (Generic Scan Tool) abrufbar sein. | Je nach Schnittstelle Radsensor/Bremsen-SG koennen nicht alle der genannten Fehlerarten erkannt werden. | KS = Kurzschluss | OC = Leitungsunterbrechung | RC = Rationality Check | OOR = Out of Range | 0000 = kein Fehler | 0001 = KS- | 0010 = KS+ | 0011 = OC | 0100 = OOR+ | 0101 = OOR- | 0110 = RC+ | 0111 = RC- | 1000 = KS+/OC | 1001 = KS-/OC | 1010 = KS-/KS+ | 1011 = KS-/KS+/OC | 1100 = frei | 1101 = frei | 1110 = frei | 1111 = frei";
CM_ SG_ 1463 B11_OBD_Nib_VR "Fehlerstatus des Radsensors vorne rechts | Da im MSG v-Fhz eine OBD-relevante Groesse ist, muessen im Fehlerfall erweiterte Diagnoseinformationen zur Signalquelle mittels GST (Generic Scan Tool) abrufbar sein. | Je nach Schnittstelle Radsensor/Bremsen-SG koennen nicht alle der genannten Fehlerarten erkannt werden. | KS = Kurzschluss | OC = Leitungsunterbrechung | RC = Rationality Check | OOR = Out of Range | 0000 = kein Fehler | 0001 = KS- | 0010 = KS+ | 0011 = OC | 0100 = OOR+ | 0101 = OOR- | 0110 = RC+ | 0111 = RC- | 1000 = KS+/OC | 1001 = KS-/OC | 1010 = KS-/KS+ | 1011 = KS-/KS+/OC | 1100 = frei | 1101 = frei | 1110 = frei | 1111 = frei";
CM_ SG_ 1463 B11_OBD_Nib_HL "Fehlerstatus des Radsensors hinten links | Da im MSG v-Fhz eine OBD-relevante Groesse ist, muessen im Fehlerfall erweiterte Diagnoseinformationen zur Signalquelle mittels GST (Generic Scan Tool) abrufbar sein. | Je nach Schnittstelle Radsensor/Bremsen-SG koennen nicht alle der genannten Fehlerarten erkannt werden. | KS = Kurzschluss | OC = Leitungsunterbrechung | RC = Rationality Check | OOR = Out of Range | 0000 = kein Fehler | 0001 = KS- | 0010 = KS+ | 0011 = OC | 0100 = OOR+ | 0101 = OOR- | 0110 = RC+ | 0111 = RC- | 1000 = KS+/OC | 1001 = KS-/OC | 1010 = KS-/KS+ | 1011 = KS-/KS+/OC | 1100 = frei | 1101 = frei | 1110 = frei | 1111 = frei";
CM_ SG_ 1463 B11_OBD_Nib_HR "Fehlerstatus des Radsensors hinten rechts | Da im MSG v-Fhz eine OBD-relevante Groesse ist, muessen im Fehlerfall erweiterte Diagnoseinformationen zur Signalquelle mittels GST (Generic Scan Tool) abrufbar sein. | Je nach Schnittstelle Radsensor/Bremsen-SG koennen nicht alle der genannten Fehlerarten erkannt werden. | KS = Kurzschluss | OC = Leitungsunterbrechung | RC = Rationality Check | OOR = Out of Range | 0000 = kein Fehler | 0001 = KS- | 0010 = KS+ | 0011 = OC | 0100 = OOR+ | 0101 = OOR- | 0110 = RC+ | 0111 = RC- | 1000 = KS+/OC | 1001 = KS-/OC | 1010 = KS-/KS+ | 1011 = KS-/KS+/OC | 1100 = frei | 1101 = frei | 1110 = frei | 1111 = frei";
CM_ SG_ 1463 B11_EPB_Steller_akt "Reserviert fuer Information fuer Start-Stopp-Koordinator. | Fuer zukuenftige EPB (nach PQ46/VW416) nicht mehr notwendig. | EPB-Steller verfaehrt";
CM_ SG_ 1463 B11_EPB_Steller_gue "Reserviert fuer Information fuer Start-Stopp-Koordinator. | Fuer zukuenftige EPB (nach PQ46/VW416) nicht mehr notwendig. | EPB-Steller-Info gueltig";
CM_ SG_ 1463 B11_Checksumme "Pruefsumme mit Endwert 0x0, Definition im CAN Lastenheft (HS-CAN V4.2a, LS-CAN V1.42)";
CM_ SG_ 1463 B11_Zaehler "Ueberlaufender Botschaftszaehler, zur Lebenderkennung";
CM_ SG_ 1463 B11_Backup_MSR "Signal wird nur im Jetta Hybrid (PQ35) benoetigt/unterstuetzt. Ist das BackupMSR nicht verfuegbar, so darf keine Rekuperation ausgefuehrt werden (Rekuperationsverbot)";
CM_ SG_ 1463 OBD_Fehler_Bremsdruck "Da im Hybrid der Bremsdruck eine OBD-relevante Groesse ist, muessen im Fehlerfall erweiterte Diagnoseinformationen zur Signalquelle mittels GST (Generic Scan Tool) abrufbar sein. | Je nach Schnittstelle Bremsen-SG koennen nicht alle der genannten Fehlerarten erkannt werden. | KS = Kurzschluss | OC = Leitungsunterbrechung | RC = Rationality Check | OOR = Out of Range | 0000 = kein Fehler | 0001 = KS- | 0010 = KS+ | 0011 = OC | 0100 = OOR+ | 0101 = OOR- | 0110 = RC+ | 0111 = RC- | 1000 = KS+/OC | 1001 = KS-/OC | 1010 = KS-/KS+ | 1011 = KS-/KS+/OC | 1100 = frei | 1101 = frei | 1110 = frei | 1111 = frei";
CM_ SG_ 1463 ESP_nachtr_Stopp_Anf "Dieses Signal dient dem Motor als Trigger, dass ein nachtraeglicher Motorstopp eingeleitet werden kann, wenn es die Bedingungen des StSt Koordinators dies zulassen.";
CM_ SG_ 1184 BR3_Rad_kmh_VL "Low Byte 1, High Byte 2 (Aufloesung 1,28 km/h) | Radgeschwindigkeit bezieht sich auf den 'Kombi 3' Reifenumfang | | Konstanten: | V_INIT = 7FC4H (bzw. FF88H oder FF89H = 1111 1111 1000 100x B in 2-Byte-Schreibweise) (entspricht 327,08 km/h) (nicht Colorado, D1GP/BY61x) | V_Uspg = 7FD5H (bzw. FFAAH oder FFABH = 1111 1111 1010 101x B in 2-Byte-Schreibweise) (entspricht 327,25 km/h) (nicht D1GP/BY61x) | V_Fehler = 7FE6H (bzw. FFCCH oder FFCDH = 1111 1111 1100 110x B in 2-Byte-Schreibweise) (entspricht 327,42 km/h) (nicht D1GP/BY61x)";
CM_ SG_ 1184 BR3_Rad_kmh_VR "Low Byte 3, High Byte 4 (Aufloesung 1,28 km/h) | Radgeschwindigkeit bezieht sich auf den 'Kombi 3` Reifenumfang | Konstanten: | V_INIT = 7FC4H (bzw. FF88H oder FF89H = 1111 1111 1000 100x B in 2-Byte-Schreibweise) (entspricht 327,08 km/h) (nicht Colorado, D1GP/BY61x) | V_Uspg = 7FD5H (bzw. FFAAH oder FFABH = 1111 1111 1010 101x B in 2-Byte-Schreibweise) (entspricht 327,25 km/h) (nicht D1GP/BY61x) | V_Fehler = 7FE6H (bzw. FFCCH oder FFCDH = 1111 1111 1100 110x B in 2-Byte-Schreibweise) (entspricht 327,42 km/h) (nicht D1GP/BY61x)";
CM_ SG_ 1184 BR3_Rad_kmh_HL "Low Byte 5, High Byte 6 (Aufloesung 1,28 km/h) | Radgeschwindigkeit bezieht sich auf den 'Kombi 3` Reifenumfang | Konstanten: | V_INIT = 7FC4H (bzw. FF88H oder FF89H = 1111 1111 1000 100x B in 2-Byte-Schreibweise) (entspricht 327,08 km/h) (nicht Colorado, D1GP/BY61x) | V_Uspg = 7FD5H (bzw. FFAAH oder FFABH = 1111 1111 1010 101x B in 2-Byte-Schreibweise) (entspricht 327,25 km/h) (nicht D1GP/BY61x) | V_Fehler = 7FE6H (bzw. FFCCH oder FFCDH = 1111 1111 1100 110x B in 2-Byte-Schreibweise) (entspricht 327,42 km/h) (nicht D1GP/BY61x)";
CM_ SG_ 1184 BR3_Rad_kmh_HR "Low Byte 7, High Byte 8 (Aufloesung 1,28 km/h) | Radgeschwindigkeit bezieht sich auf den 'Kombi 3` Reifenumfang | Konstanten: | V_INIT = 7FC4H (bzw. FF88H oder FF89H = 1111 1111 1000 100x B in 2-Byte-Schreibweise) (entspricht 327,08 km/h) (nicht Colorado, D1GP/BY61x) | V_Uspg = 7FD5H (bzw. FFAAH oder FFABH = 1111 1111 1010 101x B in 2-Byte-Schreibweise) (entspricht 327,25 km/h) (nicht D1GP/BY61x) | V_Fehler = 7FE6H (bzw. FFCCH oder FFCDH = 1111 1111 1100 110x B in 2-Byte-Schreibweise) (entspricht 327,42 km/h) (nicht D1GP/BY61x)";
CM_ SG_ 1184 BR3_Fahrtr_VL "Fahrtrichtungserkennung (im Audi D3/C6 und Colorado)";
CM_ SG_ 1184 BR3_Fahrtr_VR "Fahrtrichtungserkennung (im Audi D3/C6 und Colorado)";
CM_ SG_ 1184 BR3_Fahrtr_HL "Fahrtrichtungserkennung (im Audi D3/C6 und Colorado)";
CM_ SG_ 1184 BR3_Fahrtr_HR "Fahrtrichtungserkennung (im Audi D3/C6 und Colorado)";
CM_ SG_ 672 BR4_Vorgabe_Mi "Einheit Kupplungswert ist 0. | Vorgabe fuer das Kupplungsmoment vom Bremsen Steuergeraet an die Allradkupplung, 'Kupplung schnell offen` heisst, dass der Befehl ohne Rampe sofort ausgefuehrt werden muss; der Arbeitsbereich geht von 0 (=80H) Nm (Kupplung gesteuert offen) bis 882 (=FEH) Nm | negativer Wertebereich praktisch nicht moeglich | ACHTUNG im T5GP noch alte Aufloesung 0-378 Nm | Kupplungsmoment";
CM_ SG_ 672 BR4_Einheit "Die Einheit und der Wertebereich in Byte 1 und 2 wird mit diesem Bit gekennzeichnet (z.B. zur Verbaukontrolle nutzbar): | 0: Nm (Haldex) | 1: Normierung auf 0..100% | 2: Nm (VAQ) | Hinweis: Statischer (konstanter) Wert abhaengig vom Fahrzeugprojekt! | Einheit Kupplungswert (Bremse 4)";
CM_ SG_ 672 BR4_Schwelle "Byte 5 (BKV-Unterdruck) wird nur von speziellem HBV-Regler ausgegeben | Unterdruckschwellwert";
CM_ SG_ 672 BR4_Lampentrennung_gue "Bei gesetztem Bit sind die Informationen in mBremse_4, Byte 4, Bit 3,4,5 gueltig. Das Kombiinstrument erkennt daran, ob die Bremse die Bits ESP-Off-Lampe und ESP/ASR-Funktionslampe unterstuetzt. Falls ungueltig, verwendet das Kombi weiterhin das Lampenbit in mBremse_2. Reine ABS-Systeme (ohne ASR) senden \"0\" (oder gar keine Botschaft mBremse_4)";
CM_ SG_ 672 BR4_Lampe_ASRESP "Zustand der Fahrdynamikregelungslampe (ASR und/oder ESP)";
CM_ SG_ 672 BR4_ESP_Off "Bit zur Ansteuerung der separaten ESP-Off-Lampe im Kombi (Gesetzesforderung USA)";
CM_ SG_ 672 BR1_ASR_ESP "Kombi kann ggfs. die Lampe ansteuern | ASR/ESP-Steuergeraet";
CM_ SG_ 672 BR4_Unterdruck "der maximale Wert wird auf 1016 mbar begrenzt | Es ist der Initwert zu senden, wenn der Unterdruckschwellwert (Byte 3, Bit 3,2) auf 00 (kein Signal) steht, weil das ESP nicht ueber einen Unterdrucksensor verfuegt. | (Nur fuer HBV-Regler PQ35 und TRW-HBV-Regler PQ46)";
CM_ SG_ 672 BR4_Zaehler "Ueberlaufender Botschaftszaehler, zur Lebenderkennung";
CM_ SG_ 672 BR4_Checksum "Pruefsumme mit Endwert 0x0, Definition im CAN Lastenheft (HS-CAN V4.2a, LS-CAN V1.42)";
CM_ SG_ 672 BR4_Vorgabe_Mi_308 "Einheit der Kupplungssteifigkeit ist 1 (Prozente) ; nicht PQ35/46 | ABS-Vorgabewert fuer Kupplungssteifigkeit Mitte";
CM_ SG_ 672 BR4_Vorgabe_Max "Einheit Kupplungswert ist 2. | Max. Vorgabegrenzwert des Arbeitsbereiches der Kupplung durch das ESP (nur im PQ35 mit VAQ) | Vorgabewert fuer Kupplung Max";
CM_ SG_ 672 BR4_Vorgabe_Hi "Einheit der Kupplungssteifigkeit ist 1 (Prozente) ; nur im Colorado/Touareg GP | ABS-Vorgabewert fuer Kupplungssteifigkeit hinten";
CM_ SG_ 672 BR4_Vorgabe_Min "Einheit Kupplungswert ist 2. | Min. Vorgabegrenzwert des Arbeitsbereiches der Kupplung durch das ESP (nur im PQ35 mit VAQ) | Vorgabewert fuer Kupplung Min";
CM_ SG_ 672 BR4_Abschaltung_VL "Temperaturabschaltung ; nicht VW | EDS-Abschaltung VL";
CM_ SG_ 672 BR4_Abschaltung_VR "Temperaturabschaltung ; nicht VW | EDS-Abschaltung VR";
CM_ SG_ 672 BR4_Abschaltung_HL "Temperaturabschaltung ; nicht VW | EDS-Abschaltung HL";
CM_ SG_ 672 BR4_Abschaltung_HR "Temperaturabschaltung ; nicht VW | EDS-Abschaltung HR";
CM_ SG_ 672 BR4_Lampe_RKA "Warnlampe Reifen-Kontroll-Anzeige (Software im Bremsensteuergeraet) | z.Zt. nur bei Contiteves PQ35 | (zukuenftig in Bremse_2)";
CM_ SG_ 672 BR4_Summer_RKA "Summer zur Reifen-Kontroll-Anzeige wird nach Setzen des Bits fuer eine Sekunde angesteuert | z. Zt. nur bei Contiteves PQ35 | (zukuenftig in Bremse_2)";
CM_ SG_ 672 BR4_Status_ESP "Statusmaschine (fuer VAQ im PQ35)";
CM_ SG_ 672 BR4_MABS_Verbau "0: ESP oder reines ABS verbaut, jedoch kein MABS mit ASR-Funktion | 1: MABS mit ASR-Funktion verbaut";
CM_ SG_ 672 BR4_RKA_Verbau "0x0: kein RKA verbaut bzw. Verbauzustand RKA in der Bremse unbekannt (RKA-Signale aus mBremse_2 werden im Kombi ausgegeben, aber keine Timeoutreaktion des Roadmap-Kombis bzgl. RKA) | 0x1: RKA-Signale ueber mBremse_2 mit Timeout-Reaktion des Kombis auf mBremse_2 | 0x2: RKA-Signale ueber mBremse_RKA (vor Umbenennung mRDK_1_D3, ID 0x443) mit Timeout-Reaktion des Kombis auf mBremse_RKA | 0x3: reserviert";
CM_ SG_ 1192 BR5_Giergeschw "Low Byte 1, High Byte 2 | nicht offsetkorrigierte, gemessene Giergeschwindigkeit | tatsaechliche Aufloesung Bosch ESP: 0,27 Grad/s | Nur bei ABS-Systemen: Die Werte 3FFDH und 3FFEH zur Systemidentifikation kommen nur, wenn Gierrate ungueltig (Byte 2, Bit 6) gesetzt ist.";
CM_ SG_ 1192 BR5_Sta_Gierrate "keine Filterung | ungueltiger Wert kann z.B. aufgrund einer Unterspannung oder in der Initialisierungsphase ausgegeben werden | Gierrate ungueltig";
CM_ SG_ 1192 BR5_Vorzeichen "Linkskurve positiv, Rechtskurve negativ! | Vorzeichen der Giergeschwindigkeit";
CM_ SG_ 1192 BR5_Bremsdruck "Realer Messbereich ist in der jeweiligen Fachabteilung zu erfragen. | Low Byte 1, High Byte 2, aktueller nicht offsetkorrigierter Bremsdruck im Hauptbremszylinder (ungefiltert) | Bremsdruck (Bremse 5)";
CM_ SG_ 1192 BR5_Stillstand "Fahrzeug steht (Algorithmus im Bremsensteuergeraet) | im PQ35/46 alle 4 Radgeschwindigkeiten 0 | Stillstand-Flag";
CM_ SG_ 1192 BR5_Druckgueltig "Bremsdruck ungueltig";
CM_ SG_ 1192 BR5_Sta_Druck "Zur Plausibilisierung: Bremsdruck wird vom ESP aufgebaut (z.B. Vorladepumpe). Nachlauf muss vom Empfaenger beruecksichtigt werden. | Bei RB ESP 5.7, ESP 8, CT Mk60, MK25A XT und TRW EBC440 wird immer 0 ausgegeben, weil Drucksignal am Hauptbremszylinder nicht von Vorladepumpe kommen kann | Status Bremsdruck durch ESP-System (Bremse 5)";
CM_ SG_ 1192 BR5_Sign_Druck "Vorzeichen Bremsdruck";
CM_ SG_ 1192 BR5_Bremslicht "Bit wird gesetzt bei Bremslicht-Ansteuerung durch die Funktionen Gespannstabilisierung, RCTA oder MKB. | Hinweis: Signal wurde wg. Funktionserweiterung umbenannt (vorher BR5_AnhStabAktiv bzw. GWB_TSP_aktiv)";
CM_ SG_ 1192 BR5_AWV2_Bremsruck "Rueckmeldung Bremse ans AWV: Von AWV2 angefordeter Bremsruck wird aktuell durchgefuehrt. (im AU716 und Touareg GP, PQ46 ab 45/08, MK60EC mit Einsatz LidarKamera, nicht D1GP/BY61x)";
CM_ SG_ 1192 BR5_AWV2_Fehler "Meldung an die Funktion AWV2 (z. Z. auf ACC-SG) wenn das ESP-SG einen Kommunikationsfehler oder unplausible Daten feststellt (Touareg GP und PQ46 ab 45/08, MK60EC mit Einsatz LidarKamera, nicht D1GP/BY61x) | Im VW120 fuer CV-Funktion";
CM_ SG_ 1192 BR5_Zaehler "Ueberlaufender Botschaftszaehler, zur Lebenderkennung";
CM_ SG_ 1192 BR5_Checksumme "Pruefsumme mit Endwert 0x0, Definition im CAN Lastenheft (HS-CAN V4.2a, LS-CAN V1.42)";
CM_ SG_ 1192 ESP_Rollenmodus_Deaktivieren "Zwang zum Abbruch des Rollenmodus mit anschliessender ESP-Vollfunktion. | MQB: Zwang zum Abbruch des Rollenmodus in allen Funktionsteilnehmern (Empfaenger) mit anschliessender ESP-Vollfunktion (Sender). | Signal wird vom ESP dauerhaft mit gueltigen Werten bedatet. | Wenn gesetzt, bleibt Signal bis Busruhe gesetzt.";
CM_ SG_ 1192 ESP_Stat_FallBack_eBKV "Das Signal zeigt dem eBKV an, ob die HBV-Funktion im ESC verfuegbar ist.";
CM_ SG_ 1192 ESP_Anforderung_EPB "ESP fordert von der EPB Oeffnen bzw. Schliessen an. Notwendig wegen Autohold-Funktion. | Bedienung nur im VW411CS.";
CM_ SG_ 1192 BR5_Anhi_akt "Anfahrhilfe wird angesteuert";
CM_ SG_ 1192 BR5_v_Ueberw "Funktion Geschwindigkeitsueberwachung ist aktuell verfuegbar (Getriebe_1-Bits werden beachtet) (nur im Colorado)";
CM_ SG_ 1192 BR5_Fahrer_tritt_ZBR_Schw "Signal fuer AWV | 0 = Fahrer uebertritt aktuell gueltige ZBR-Schwelle nicht | 1 = Fahrer uebertritt aktuell gueltige ZBR-Schwelle";
CM_ SG_ 1192 BR5_ECD_Lampe "Bremslichtansteuerung durch ECD-Funktion (nicht PQ35/46)";
CM_ SG_ 1192 ESP_Autohold_aktiv "Rueckmeldung an EPB, dass Autohold aktiv ist. | Bedienung nur im VW411CS.";
CM_ SG_ 1192 ESP_Autohold_Standby "Rueckmeldung an EPB, dass der Fahrer die Funktion Autohold mindestens einmal angefordert hat. Im Fall eines ESP-Ausfalles oder einer Uebernahmeaufforderung erfolgt die EPB-Zuschaltung nur nach Setzen dieses Bits. Bit wird gesetzt nach Betaetigung des Autohold-Tasters und wenn ESP incl. Aktivierungsbedingungen (z.B. Gurt gesteckt, ...) dazu bereit ist. | Bedienung nur im VW411CS.";
CM_ SG_ 1192 BR5_Anhi_Sta "Bei gesetztem Fehler steht die Anfahrhilfe nicht zur Verfuegung";
CM_ SG_ 1192 BR5_Notbremsung "Automatische Aktivierung des Warnblinkers und Bremsflaechenvergroesserung bei Notbremsung. Funktion im ESP8 & ILM-Hinten ab Audi C6 erstmalig implementiert. (nicht PQ46) (nicht D1GP/BY61x) | Notbremsanzeige";
CM_ SG_ 1192 BR5_ZT_Rueckk_Umsetz "Signal fuer AWV | Das Signal dient als Rueckmeldung zum ACC bzw. CV-Sensor, dass eine angeforderte Zielbremsung/Teilbremsung durchgefuehrt wird. Die positive Rueckmeldung loest u.a. eine entsprechende Fahrerinformation im Kombiinstrument aus";
CM_ SG_ 1192 BR5_ANB_CM_Rueckk_Umsetz "Signal fuer AWV | Das Signal dient als Rueckmeldung zum ACC, dass eine angeforderte ANB-CM durchgefuehrt wird. Die positive Rueckmeldung loest u.a. eine entsprechende Fahrerinformation im Kombiinstrument aus";
CM_ SG_ 1192 BR5_HDC_bereit "Flag wird vom ESP gesetzt, wenn ueber den HDC-Taster das BCM das Bit \"HDC-Taster\" sendet und der Systemzustand die Aktivierung der Funktion zulaesst | Nur in AU316 genutzt";
CM_ SG_ 428 BR8_Checksumme "Pruefsumme mit Endwert 0x0, Definition im CAN Lastenheft (HS-CAN V4.2a, LS-CAN V1.42) | | Verfuegbarkeit der Botschaft mBremse_8 speziell bei ABS/MABS-Systemen bitte ueber die Fachababteilung erfragen!";
CM_ SG_ 428 BR8_Zaehler "Ueberlaufender Botschaftszaehler, zur Lebenderkennung";
CM_ SG_ 428 BR8_Sta_ACC_Anf "gueltige ACC-Anforderung zur Verzoegerungsrege-lung ECD / Bremsenregelung wird ausgefuehrt: Druckaufbau ueber Standby hinaus (im PQ46 aus Motor_Bremse) (nur bei Audi auch GRA+-Anforderung moeglich) | Status Bremse ACC-Anforderung";
CM_ SG_ 428 BR8_Verz_EPB_akt "Bei gesetzten Bit wird Verzoegerungswunsch von EPB umgesetzt. | Verzoegerung durch EPB aktiviert";
CM_ SG_ 428 BR8_Sta_Br_temp "ECD-Bremsscheibentemperaturmodell ;Reaktion durch ACC, GRA od. EPB | Status Bremse Bremstemperatur";
CM_ SG_ 428 BR8_Sta_Br_Druck "bei gesetztem Bit liegt p > ca. 2 bar an, hervorgerufen durch Fahrer, ASR, FZR, ECD, Bremsenregler...bei Abfall des Bits ist p < X bar, bei aktivem ECD-Eingriff Ende des Eingriffs (fuer den PQ46 noch in Klaerung) | Status Bremsdruck";
CM_ SG_ 428 BR8_Istbeschl "Fahrzeugbeschleunigung als Referenzwert fuer ACC (abgeleitet aus der Geschwindigkeit, die in Bremse 1 uebertragen wird) (nur fuer Ueberwachungszwecke)";
CM_ SG_ 428 BR8_QB_LBeschl "Definition nach CAN-Lastenheft | Qualifizierungsbit Laengsbeschleunigung";
CM_ SG_ 428 BR8_aktBrSyst "Bremssystem kann aufgrund einer externen Anforderung (z.B. Motor_Bremse) aktiv bremsen | Aktives Bremssystem";
CM_ SG_ 428 BR8_StaBrSyst "Aktives Bremssystem setzt Anforderungen von externem System (Andocken/ Standby oder Verzoegerung) um | Status aktives Bremssystem";
CM_ SG_ 428 BR8_Laengsbeschl "Laengsbeschleunigung (im PQ12/25/35 ausstattungsabhaengig (z.B. Allrad, Start/Stopp,...)): Sensorwert, im PQ46 Rohwert, im PQ35 kein Rohwert | | Sensorverbau, Signalbedienung und Verfuegbarkeit der Botschaft mBremse_8 speziell bei ABS/MABS-Systemen bitte ueber die Fachababteilung erfragen!";
CM_ SG_ 428 BR8_Sta_ADR_BR "Rueckmeldung zum ACC bezueglich Pruefung der Checksumme, des Botschaftszaehlers und des langen Timeout der ACC-1 Botschaft. Wird gesetzt bei ACC-Verzoegerungsanforderungen groesser einer applizierbaren Schwelle. (bei Audi GRA+ Rueckmeldung zum Motor) (bei VW: Rueckmeldung zum Motor; Pruefung auf Motor_Bremse-Botschaft) | Konsistenz ACC Botschaft";
CM_ SG_ 428 BR8_Sta_VerzReg "ESP kann die Verzoegerungsregelung / Bremsenregelung nicht ausfuehren | Status Verzoegerungsregler";
CM_ SG_ 428 BR8_Verz_EPB "Bei gesetzten Bit ist der Verzoegerungsregler fuer EPB verfuegbar.";
CM_ SG_ 428 BR8_Check_EPB "Bei nicht gesetztem Bit wird die EPB Botschaft nicht empfangen oder Inhalt ist unplausibel (Checksumme, Botschaftszaehler) | EPB Botschaft plausibel";
CM_ SG_ 428 BR8_HHC_Haltebestaetigung "Der Bremsdruck ist ausreichend um das Fzg. zu halten (P kann ausgelegt werden).";
CM_ SG_ 428 BR8_HHC_Signal_QBit "Das Signal zeigt an, ob das Signal BR8_HHC_Haltebestaetigung gueltig ist.";
CM_ SG_ 428 BR8_Sta_HW_BLS "Endstufe Bremslichtschalter-Ausgang defekt | Status Hardware BLS-Ausgang";
CM_ SG_ 428 BR8_ESC_Mode "Anzeige \"ESC Mode\" (ESP-Modus) nur im MY10 Bentley-Kombi | (war \"AWV1 Basisparametersatz HBA\" Rueckmeldung des aktuell codierten Parametersatzes ans ACC nur Audi C6/AU716)";
CM_ SG_ 428 BR8_Fa_bremst "Fahrer bremst bzw. bremst staerker als aktives Bremssystem (nur benoetigt fuer aktive Bremssysteme) | Nur im Porsche Cayenne wird das Bit auch bei Gespannstabilisierungseingriff gesetzt.";
CM_ SG_ 428 BR8_Quattro "Information darueber, ob das Fahrzeug Front- oder Allradantrieb (Quattro) hat (nicht bedient im PQ35/46)";
CM_ SG_ 428 BR8_Sta_BLS "ESP hat Fehler in der Erfassung des Bremslichtschalters erkannt | Status BLS";
CM_ SG_ 428 ESP_MKB_ausloesbar "ESP hat Funktion Multi-Kollisions-Bremsung freigeschaltet";
CM_ SG_ 428 ESP_Haltebestaetigung "Rueckmeldung vom ESP-SG, dass das Fahrzeug aufgrund einer externen Bremsanforderung (z. B. ACC, PLA, ANB, o. ae.) abgebremst wurde und im Stillstand gehalten wird.";
CM_ SG_ 428 ESC_Motorstartverzoegerung "Mit dem Signal \"Motorstartverzoegerung\" wird den aktiven Teilnehmern ermoeglicht, einen Motorstart durch die Start-Stop-Funktion zu verzoegern.";
CM_ SG_ 174 BR9_Checksumme "Pruefsumme mit Endwert 0x0, Definition im CAN Lastenheft (HS-CAN V4.2a, LS-CAN V1.42)";
CM_ SG_ 174 BR9_Sta_ESP_PLA "Zustand der Statusmaschine der Bremse fuer die korrespondierenden Statusmaschine in dem PLA-SG.";
CM_ SG_ 174 BR9_Zaehler "Freilaufender Botschaftszaehler, dient als Quelle des Botschaftsspiegels in Lenkhilfe_3 Botschaft";
CM_ SG_ 174 BR9_LMOffset "reale Aufloesung 0,01 Nm | Anforderung Lenkmomenten-Offset";
CM_ SG_ 174 BR9_LMOffSign "Vorzeichen Anforderung Lenkmomenten-Offset";
CM_ SG_ 174 BR9_LWOffset "positiver Lenkradwinkel: nach links | negativer Lenkradwinkel: nach rechts | Anforderung Lenkwinkel-Offset";
CM_ SG_ 174 BR9_LWOffSign "Vorzeichen Anforderung Lenkwinkel-Offset";
CM_ SG_ 174 BR9_Sta_DSR "0 DSR deaktiviert | 1 DSR Anforderung nicht ausfuehrbar (ESP Fehlerstatus) | 2 Kommunikation zum ESP-SG gestoert | 3 ESP bzgl. DSR funktionsbereit | 4 offen | 5 externer Momenteneingriff angefordert | 6 externer Lenkwinkeleingriff angefordert | 7 externer Momenten und Lenkwinkeleingriff angefordert | 8..15 reserviert | Status DSR";
CM_ SG_ 174 BR9_PLA_Abbruch "Wenn der Bremseingriff abgebrochen wurde, wird in diesem Signal der Grund des Abbruchs dargestellt. Dies ist nur gueltig, wenn der Status BR9_Sta_ESP_PLA = \"10\" ist.";
CM_ SG_ 1986 LWI_Init_ID "ID fuer LWS_Init";
CM_ SG_ 1986 LWI_Codierbytes "Codierbytes";
CM_ SG_ 912 GK1_SleepAckn "Nach Empfang des 'Sleep-Acknowledge' (Klemme 15 aus) muss der Sendebetrieb sofort eingestellt werden | Die CAN-Schnittstelle (empfangseitig) wird nach der Wartezeit (750 ms) komplett abgeschaltet (nicht Colorado) | Touareg GP u. D1GP setzen das Bit nach 'Kl.15 aus' (3-maliges Senden) | BCM PQ25 setzt Bit nach 'Kl.15 aus' dauerhaft, wenn (BR1_Rad_kmh = 0 oder BR1 Timeout). | Ruecksetzen des Bits erst nach 'Kl.15 ein'";
CM_ SG_ 912 GK1_Sta_Anhaen "Anhaenger-Botschaft nicht empfangen (1,6 s/200 ms) | | Zykluszeit der Quellbotschaft [ms]: 800 | | Veraltet Bit fuer die Signale: | | Botschaft mGate_Komf_1: | Byte 6, Bit 6 GK1_Anhaenger | Byte 6, Bit 7 GK1_BrLi_Anhaen";
CM_ SG_ 912 GK1_Sta_Licht1 "Licht-Botschaft nicht empfangen (100 ms) | Das integrierte Gateway (BCM) sendet dauerhaft \"0\", da es ggf. fuer die genannten Signale Originalsender ist! | | Zykluszeit der Quellbotschaft [ms]: 50 | | Veraltet Bit fuer die Signale: | | Botschaft mGate_Komf_1: | Byte 1, Bit 6 LIA_Standlicht | Byte 4, Bit 4 GK1_Rueckfahr | Byte 7, Bit 0 GK1_Abblendlicht | Byte 7, Bit 1 GK1_Fernlicht | Byte 7, Bit 7 GK1_Warnblk_Status | Byte 8, Bit 2 GK1_Nebel_ein | Byte 8, Bit 3 GK1_Bremslicht | | Botschaft mGate_Komf_2: | Byte 2, Bit 3 GK2_Blk_L_Kontrolle | Byte 2, Bit 4 GK2_Blk_R_Kontrolle | Byte 4, Bit 5 GK2_AFL_Schalter | Byte 4, Bit 6 GK2_Nebelschluss";
CM_ SG_ 912 GK1_Sta_Tuerkont "mBSG_Kombi-Botschaft nicht empfangen (100 ms) | Das integrierte Gateway (BCM) sendet dauerhaft \"0\", da es ggf. fuer die genannten Signale Originalsender ist! | | Zykluszeit der Quellbotschaft [ms]: 50 | | Veraltet Bit fuer die Signale: | | Botschaft mGate_Komf_1: | Byte 3, Bit 0 GK1_Fa_Tuerkont | Byte 4, Bit 0 BCM_Remotestart_Betrieb | Byte 4, Bit 1 BCM_Offroad_Taster | Byte 4, Bit 2 BSK_HL_geoeffnet | Byte 4, Bit 3 BSK_HR_geoeffnet | Byte 6, Bit 1 BSK_BT_geoeffnet | Byte 6, Bit 2 BCM_CV_Taster | Byte 6, Bit 3 BSK_HD_Hauptraste | Byte 6, Bit 4 BSK_Tankklappe";
CM_ SG_ 912 GK1_Fa_Tuerkont "Status der Drehfalle Fahrertuer";
CM_ SG_ 912 GK1_Rueckfahr "1 = Rueckfahrlicht ein";
CM_ SG_ 912 GK1_Anhaenger "1 = Anhaenger erkannt | Anhaenger erkannt (Gateway Komfort 1)";
CM_ SG_ 912 GK1_Wischer_vorn "1 = Frontwischer aktiv, d.h. Intervall / Regensensor / Sufe1 / Stufe2, d.h. Wischer ist in Bewegung";
CM_ SG_ 912 GK1_Sta_ILM_F_1 "ILM_Fahrer_1-Botschaft nicht empfangen (2 s) | Wischer_1 Botschaft nicht empfangen (400 msec) | ILM_Fahrer_1 veraltet / Wischer 1 veraltet | | Zykluszeit der Quellbotschaft [ms]: 200 | | Veraltet Bit fuer die Signale: | | Botschaft mGate_Komf_1: | Byte 3, Bit 6 GK1_ParkFrontWi | Byte 6, Bit 0 WI1_Front_Wasch | Byte 7, Bit 2 GK1_Wischer_vorn";
CM_ SG_ 912 GK1_Warnblk_Status "1 = solange Warnblinken aktiviert ist | 0 = kein Warnblinken aktiv | Statische Anzeige Warnblinklicht ist eingeschaltet";
CM_ SG_ 912 GK1_Sta_RDK_Warn "RDK-Botschaft nicht empfangen (1,6 s/200 ms)";
CM_ SG_ 912 GK1_Sta_Licht3 "Licht_hinten-Botschaft nicht empfangen (200 ms nur Audi) | mLicht_3-Botschaft veraltet (2 s Colorado) | reserviert im PQ35/46 (Init 0 im PQ35/46)";
CM_ SG_ 912 GK1_Sta_Li_vorn "Licht_vorne-Botschaft nicht empfangen (2 s, nur Audi) | reserviert im PQ35/46 (Init 0 im PQ35/46)";
CM_ SG_ 912 LIA_Standlicht "1 = Standlicht eingeschaltet (BCM_PQ25: Schalterinformation) | Vorsicht Sleep-Mode! | Kl58, Standlicht ein";
CM_ SG_ 912 GK1_CharismaModus "Charisma-Modus | Nur gueltig, wenn GK1_SamFktNr auf den Wert 1 gesetzt ist";
CM_ SG_ 912 GK1_SamFktNr "Sammelfunktions-Nr. | Die gueltigen SF werden mit jeder neuen Botschaft hochgezaehlt. Bei Aenderung wird mit Inhibit 50ms das Hochzaehlen mit der entsprech. SF-Nr. unterbrochen.";
CM_ SG_ 912 GK1_RueckfahrSch "Info wird aus 'ILM_Fahrer_1', Byte 2, Bit 1 (nur bei Audi) entnommen | Rueckfahrlichtschalter";
CM_ SG_ 912 GK1_ELV_verrieg "ELV im Zustand verriegelt | Fuer das Signal in der mELV_Kessy_WFS [0x373] gilt: Signal erst nach Ruecksprache mit ELV Funktionsverantwortung nutzen.";
CM_ SG_ 912 GK1_Sta_Kessy_2 "Kessy 2 (400 msec Col.), mELV_Kessy_WFS (200 msec PQ46), mELV_1 (2000msec PQ35/PQ25) wird nicht empfangen";
CM_ SG_ 912 GK1_Sta_Stdhzg "mStheizung_1 wird nicht empfangen (400 ms) | | Zykluszeit der Quellbotschaft [ms]: 200 | | Veraltet Bit fuer die Signale: | | Botschaft mGate_Komf_1: | Byte 3, Bit 5 GK1_SH_Verbau | Byte 3, Bit 7 GK1_KW_Warm | Byte 8, Bit 1 SH1_ein_Wasserpumpe";
CM_ SG_ 912 GK1_SH_Verbau "1 = Steuergeraet ist Standheizung, d.h. kann auch ohne Klemme 15 heizen | 0 = Steuergeraet ist Zuheizer, d.h. kann nur mit Klemme 15 betrieben werden | Status (Verbau) SH-Steuergeraet";
CM_ SG_ 912 GK1_ParkFrontWi "1= Frontwischer in Parklage";
CM_ SG_ 912 GK1_KW_Warm "Bit zeigt an, dass die Standheizung das Wasser im Heizungskreislauf erwaermt hat und dieses in den Kuehlkreislauf des Motors abgibt bzw. kuerzlich abgegeben hat. | Kuehlwasser erwaermt";
CM_ SG_ 912 BCM_Remotestart_Betrieb "Anforderung Remotestartbetrieb";
CM_ SG_ 912 BSK_HL_geoeffnet "Status der Drehfalle Tuer hinten links";
CM_ SG_ 912 BSK_HR_geoeffnet "Status der Drehfalle Tuer hinten rechts";
CM_ SG_ 912 GK1_BrLi_links "1 = defekt | Bremsleuchte hinten links defekt (s. Gateway Komfort 1)";
CM_ SG_ 912 GK1_BrLi_rechts "1 = defekt | Bremsleuchte hinten rechts defekt (s. Gateway Komfort 1)";
CM_ SG_ 912 GK1_BrLi_mitte "1 = defekt | 3. Bremsleuchte defekt (s. Gateway Komfort 1)";
CM_ SG_ 912 GK1_BLS_ILM "Bremse 1, Byte 2, Bit 3 widerspricht der Hardware-Leitung vom BLS zum ILM hinten (nur bei Audi): Info wird aus 'Licht hinten' entnommen | BLS ILM unplausibel";
CM_ SG_ 912 GK1_EDC_ILM "Bremse 5, Byte 7, Bit 3 widerspricht der Hardware-Leitung vom ESP zum ILM hinten (nur bei Audi): Info wird aus 'Licht hinten' entnommen | ECD ILM unplausibel";
CM_ SG_ 912 GK1_Blinker_li "Richtungsblinken links betaetigt (s. Gateway Komfort)";
CM_ SG_ 912 GK1_Blinker_re "Richtungsblinken rechts betaetigt (s. Gateway Komfort)";
CM_ SG_ 912 GK1_def_P_verr "1 = Defekt des P-Verriegelt-Schalters erkannt | 0 = P-Verriegelt-Schalter o.K | eine Anzeige im Kombi soll mit diesem Bit realisiert werden. | Defekterkennung des Park Verriegeltschalters im Waehlhebel";
CM_ SG_ 912 GK1_LS1_Fernlicht "Fernlichtschalter | PQ25: Das Signal wird nur bei verbautem BCM-Licht aktiv bedient. Das Signal kennzeichnet die Betaetigung der Lichthupe oder des Fernlichtes.";
CM_ SG_ 912 GK1_Sta_Licht2 "Licht 2-Botschaft wird nicht empfangen (2 s) | ACHTUNG: Quellbotschaft kommt als Event! Keine Ausfalldiagnose moeglich! | Das integrierte Gateway (BCM) sendet dauerhaft \"0\", da es ggf. fuer die genannten Signale Originalsender ist! | | Veraltet Bit fuer die Signale: | | Botschaft mGate_Komf_1: | Byte 4, Bit 5 GK1_BrLi_links | Byte 4, Bit 6 GK1_BrLi_rechts | Byte 4, Bit 7 GK1_BrLi_mitte | Byte 7, Bit 4 GK1_Abbl_VL_def | Byte 7, Bit 5 GK1_Abbl_VR_def";
CM_ SG_ 912 GK1_Sta_LSM "LSM-Botschaft wird nicht empfangen (200 ms) | Das integrierte Gateway (BCM) sendet dauerhaft \"0\", da es ggf. fuer die genannten Signale Originalsender ist! | | Zykluszeit der Quellbotschaft [ms]: 100 | | Veraltet Bit fuer die Signale: | | Botschaft mGate_Komf_1: | Byte 5, Bit 2 GK1_Blinker_li | Byte 5, Bit 3 GK1_Blinker_re | Byte 5, Bit 4 GK1_def_P_verr | Byte 5, Bit 5 GK1_LS1_Fernlicht | | Botschaft mGate_Komf_2: | Byte 2, Bit 5 LS1_Lichthupe | Byte 8, Bit 6 LS1_FAS_Taster | Byte 8, Bit 7 LS1_Fehler_FAS_Taster";
CM_ SG_ 912 WI1_Front_Wasch "1 = Wascherpumpe Front aktiv";
CM_ SG_ 912 BSK_BT_geoeffnet "Status der Drehfalle Beifahrertuer";
CM_ SG_ 912 BCM_CV_Taster "Zeigt die Betaetigung des am BCM angeschlossenen Tasters zur Umschaltung des CV-Sensors | (nicht AU210/316)";
CM_ SG_ 912 BSK_HD_Hauptraste "Status der Heckdeckel-Hauptraste";
CM_ SG_ 912 BSK_Tankklappe "Es wird ein Text 'Tankklappe offen' oder das CAR-Outline Symbol im Kombi angezeigt. Die rechte Schiebetuer geht in den lokalen 'E-KiSi-Modus', solange die Tankklappe geoeffnet ist.";
CM_ SG_ 912 EV1_Anf_Klemme_50 "Signal wird zur Plausibilisierung parallel zum Klemmensignal auf dem CAN uebertragen | Anforderung Klemme_50";
CM_ SG_ 912 GK1_BrLi_Anhaen "1 = Anhaenger Bremslicht defekt | Anhaenger Bremslicht defekt (s. Gateway_Komfort_1)";
CM_ SG_ 912 GK1_Abblendlicht "Statusmeldungen fuer Anzeige im Kombi | Kl56b Abblendlicht ein";
CM_ SG_ 912 GK1_Fernlicht "1 = Licht ein | Kl56a Fernlicht ein | PQ25: Das Signal wird nur bei verbautem BCM-Licht aktiv bedient";
CM_ SG_ 912 GK1_Abbl_VL_def "1 = defekt | Abblendlicht vorne links defekt";
CM_ SG_ 912 GK1_Abbl_VR_def "1 = defekt | Abblendlicht vorne rechts defekt";
CM_ SG_ 912 GK1_Blink_Autob "Aktueller Zustand aus Blinkmodi-Botschaft entnommen | Blinken_Autobahn";
CM_ SG_ 912 GK1_SH_laeuft "Nur im D3 wird diese Info auch aus \"Klima1_D3\" entnommen | Standheizung laeuft";
CM_ SG_ 912 SH1_ein_Wasserpumpe "1 = Wasserpumpe der Standheizung (gesteuert von der Climatonic) einschalten";
CM_ SG_ 912 GK1_Nebel_ein "1 = Nebelscheinwerfer eingeschaltet | Kl83a Nebellicht ein | Im VW250 wird dieses Signal nicht bedient.";
CM_ SG_ 912 GK1_Bremslicht "1 = Bremslicht eingeschaltet";
CM_ SG_ 912 GK1_Anh_abgesteckt "Aktueller Zustand des Anhaengers wird aus Anhaenger-Botschaft entnommen | Anhaenger abgesteckt";
CM_ SG_ 912 GK1_AnhKonLamp "Akt. Zustand der Anhaengerblinklampe (Taktsignal) wird aus BSG-Botschaft entnommen (nur T5) | Kontrolllampe Anhaenger";
CM_ SG_ 912 LDS_Stellung_AFL "Nur im Q7: Lichtdrehschalterstellung Auto";
CM_ SG_ 912 GK1_SH_Zusatzfkt "Zusatzfunktionen der Standheizung sind verfuegbar, wenn DLC von mStHeizung_1 >=7 | (Gueltigkeit von GK1_KW_Warm in Zusammenhang mit den Veraltet-Bit)";
CM_ SG_ 912 BCM_Offroad_Taster "Zeigt die Betaetigung des am BCM angeschlossenen Offroad-Tasters. | Nur im AU316: Zeigt die Betaetigung des am BCM angeschlossenen HDC-Tasters an.";
CM_ SG_ 194 LW1_Initquelle "Lenkwinkelsensor wird ueber Raddrehzahl oder 'Geradeausfahrt'-Bit der EPS initialisiert | Quelle fuer Init";
CM_ SG_ 194 LW1_LRW "Low Byte 1, High Byte 2 | 0 geradeaus | 7FFFH am Anschlag | Lenkradwinkel";
CM_ SG_ 194 LW1_LRW_Sign "positiver Lenkradwinkel: nach links | negativer Lenkradwinkel: nach rechts | Lenkradwinkel_Sign";
CM_ SG_ 194 LW1_ID "Nullpunktabgleich des LWS noch nicht durchgefuehrt | Sonstige Fzg (ausser PQ35 s. u.): ESP-Steuergeraet uebergibt beim Nullpunktabgleich eine ID-Nummer an den LWS. | Die Zufallszahl (<>0) wird nach erfolgreichem Nullpunktabgleich als Lenkwinkel_ID uebernommen | | PQ35/46/VW32x/VW411: Bit 7 auf 1 (entspricht 80H) steht fuer Sensor ist kalibriert";
CM_ SG_ 194 LW1_Status "\"o.k.\": absoluter Lenkradwinkel und Lenkradwinkelgeschwindigkeit werden korrekt berechnet | \"no init\": Sensor ist nicht initialisiert, absoluter Lenkradwinkel kann noch nicht berechnet werden, kein Fehler | \"sporadischer Fehler\": Sensor ist bis zum Ausschalten der Zuendung abgeschaltet | \"dauerhafter Fehler\": Sensor ist permanent abgeschaltet | | Hinweis fuer den separaten LWS PQ24/25 Valeo, PQ25 Kostal, A-Entry Kostal: | Der Wert wechselt nach 10 Min. Kl.-15 aus auf \"no init\". Beim nachfolgenden Kl.-15 ein bleibt der Status solange auf \"no init\", bis das Lenkrad (minimal) bewegt wird.";
CM_ SG_ 194 LW1_Sta_KL30 "(z.Zt. nur Kostal-Sensor) | Sensor ist nach KL30-Ausfall nicht initialisiert, absoluter Lenkradwinkel kann noch nicht berechnet werden, Segmenterkennung durch Auswertung der Radsignale | Status_KL30_Ausfall";
CM_ SG_ 194 LW1_Zaehler "freilaufender Botschaftszaehler";
CM_ SG_ 194 LW1_CRC "Definition nach Lastenheft 'Uebertragungsmodul fuer ESP': | Einerkomplement des Ergebnisses der 8 Bit Addition von Byte 1, 2, 3, 4 und 6. | Pruefsumme (Lenkwinkel 1)";
CM_ SG_ 194 LW1_Lenk_Gesch "Low Byte 3, High Byte 4 | 0 keine Bewegung | 7FFFH maximale Geschwindigkeit | Lenkradwinkel-Geschwindigkeit";
CM_ SG_ 194 LW1_Gesch_Sign "Lenkradwinkel-Geschwindigkeit_Sign";
CM_ SG_ 194 LW1_Kodier "Der separate LWS gibt Kodierdaten aus: Multiplex-Ausgabe der 3 Kodierbytes abh. Vom Zaehler in Byte 6 (Bit 7 oder 6 ungleich 0)";
CM_ SG_ 1420 M10_StartStopp_Fahrerwunsch "Fahreraktivitaet Start/Stopp";
CM_ SG_ 1420 M10_Status_StSt "Systemstatus des Start-Stopp-Koordinators | 0 = System in diesem Kl15 Zyklus nicht verfuegbar (Sicherheitsabschaltung, Sensorfehler erkannt, Funktion nicht implementiert) | 1 = Abschaltung ueber Hauptschalter | 2 = System aktiv, Motorlauf nicht notwendig (Freigaben aller Komponenten liegen vor) | 3 = System aktiv, Motorlauf notwendig bzw. Wiederstart erforderlich (mindestens eine Komponentenfreigabe fehlt)";
CM_ SG_ 1420 M10_Wiederstart "Motorwiederstart durch Start-Stopp-Koordinator. \"Wiederstart aktiv\" wird vom Koordinator gesetzt sobald der Wiederstart angetriggert wird und bleibt bis zum Startende gesetzt. (bleibt beim Erststart 0)";
CM_ SG_ 1420 M10_Anzeige "Anzeige Start/Stopp_Automatikstart | | 0 = keine Anzeige | | Start/Stopp: | 1 = Motor in Stoppbetrieb (Symbol \"A\") | 2 = Systemfehler Start-Stopp (VW ID_TXT_2022.1) | 3 = Motor manuell starten (VW ID_TXT_2022.0) | 5 = Temporaer nicht verfuegbar (Symbol \"durchgestrichenes A\") | 9 = Unerwuenschter Motorstillstand | | Automatikstart: | 12 = Motor startet | 13 = Kupplung betaetigen | 14 = Waehlhebel in P/N Position | 15 = Bremse treten";
CM_ SG_ 1420 M10_Anf_Kl75 "Anforderung an das BSG/BCM bei Konzepten mit Startersteuerung durch das MSG: Beim Erststart fordert das MSG mit diesem Signal das Ausschalten der KL75-Verbraucher an. (Bei einem Wiederstart innerhalb der Start-Stopp-Funktionalitaet bleib das Signal gesetzt.) | Anforderung KL75";
CM_ SG_ 1420 MSG_Remotestart_Betrieb "Wenn das MSG fuer den Remotestartbetrieb bereit ist, wird dieses Signal gesendet und wird solange \"aktiv\" gesendet wie das MSG den Remotestart unterstuetzt.";
CM_ SG_ 1420 M10_SpannungsAnf "Forderung des Motor-SGs zur Spannungsanhebung";
CM_ SG_ 1420 M10_UDruckDyn "0 = Der Saugrohrunterdruckwert ueberstieg mind. einmal mehr als 50mbar (in Richtung Vakuum), bezogen auf den hoechsten Saugrohrunterdruckwert aus der aktuellen und letzen CAN-Ausgabe (siehe mMotor_10, Byte 3, Bit 5..0). | 1 = Der Saugrohrunterdruckwert war immer weniger als 50mbar angestiegen (in Richtung Vakuum), bezogen auf den hoechsten Saugrohrunterdruckwert aus der aktuellen und letzen CAN-Ausgabe (siehe mMotor_10, Byte 3, Bit 5..0). | Saugrohrunterdruckdynamik";
CM_ SG_ 1420 M10_Freigabe_Reku "Empfehlung des Motor-SG's zur Spannungsabsenkung/-anhebung fuer den Rekuperationsbetrieb (PQ25, PQ35/46, AU210, C6, AU716, Touareg GP, Hybrid-Projekte) | Freigabe Rekuperation";
CM_ SG_ 1420 M10_Fahrbereitschaft "Signal steuert u.a. in der Lenkhilfe zusammen mit weiteren Informationen den Modewechsel in den \"Drivemode\" | Fahrbereitschaft";
CM_ SG_ 1420 M10_Hybrid "Anhand dieses Signals plausibilisiert die Lenkhilfe das Bit Fahrbereitschaft | Hybrid";
CM_ SG_ 1420 M10_EM_aktiv "fuer Kombiinstrument zur Steuerung der Anzeigen und Auswertung (z.B. Reichweite, DOeW usw.) | E-Motor aktiv";
CM_ SG_ 1420 M10_VM_aktiv "fuer Kombiinstrument zur Steuerung der Anzeigen und Auswertung (z.B. Reichweite, DOeW usw.) | V-Motor aktiv";
CM_ SG_ 1420 M10_HYB_Bereitlampe "gruene Anzeige im Kombiinstrument zur Signalisierung der Bereitschaft des Hybridsystems | Lampe Hybrid-Bereitschaft";
CM_ SG_ 1420 M10_HYB_Warnlampe "gelbe Anzeige im Kombiinstrument zur Signalisierung der Warnmeldung des Hybridsystems | Lampe Hybrid-Warnung";
CM_ SG_ 1420 M10_HYB_Fehlerlampe "rote Anzeige im Kombiinstrument zur Signalisierung der Sicherheitsmeldung des Hybridsystems | Lampe Hybrid-Fehler";
CM_ SG_ 1420 M10_Fehler_HV_Netz "Im HV-Bordnetz ist fehlerbedingt kein generatorischer Betrieb moeglich. Das 12V-Bordnetz wird ueber den DC/DC-Wandler allein aus der Traktionsbatterie gespeist. Um diesen Zustand moeglichst lange aufrechterhalten zu koennen, sollten Komfort-Verbraucher abgeschaltet werden. (Hybrid) | Fehler HV-Netz";
CM_ SG_ 1420 M10_EKlKomLeiRed "Anforderung an die Klimasteuerung, die Leistungsaufnahme des E-Kompressors bei schlechtem SOC und in bestimmten Fahrsituationen zu begrenzen. | (Das bereits bestehende Signal \"Klimakompressor aus\" Motor5, Byte2, Bit5 als stets umzusetzende Anforderung bleibt unveraendert bestehen.) | 0 keine Leistungsbegr. gewuenscht | 1 Leistungsbegr. auf 75% der max. Leistung | 2 Leistungsbegr. auf 50% der max. Leistung | 3 Leistungsbegr. auf 25% der max. Leistung | E-Klimakompressor Leistungsbegrenzung";
CM_ SG_ 1420 M10_Klimadruck "Drucksensor am Motor-SG (China Modell X/Y)";
CM_ SG_ 1420 M10_KompAusCode "Abschaltbedingungen im Motor fuer den Klimakompressor (China Modell X/Y) | Kompressor-Aus-Code";
CM_ SG_ 1420 M10_Akustik "Anforderung einer Akustikwarnung im Kombi (durch Hybrid- oder Start/Stopp-Koordinator) | 0 = keine Akustik | 1 = Akustik 1 (Gong 1000 bei VW) | 2 = Akustik 2 (3xSummer2000 bei VW) | 3 = frei";
CM_ SG_ 1420 M10_Text_1_Hybrid "Diese Texte werden projektspezifisch zwischen Motor und Kombi abgestimmt. | Inhalte bitte in den Fachabteilungen erfragen.";
CM_ SG_ 1420 M10_Text_2_Hybrid "Diese Texte werden projektspezifisch zwischen Motor und Kombi abgestimmt. | Inhalte bitte in den Fachabteilungen erfragen.";
CM_ SG_ 1420 M10_Text_3_Hybrid "Diese Texte werden projektspezifisch zwischen Motor und Kombi abgestimmt. | Inhalte bitte in den Fachabteilungen erfragen.";
CM_ SG_ 1420 M10_Text_4_Hybrid "Diese Texte werden projektspezifisch zwischen Motor und Kombi abgestimmt. | Inhalte bitte in den Fachabteilungen erfragen.";
CM_ SG_ 1420 M10_Text_5_Hybrid "Diese Texte werden projektspezifisch zwischen Motor und Kombi abgestimmt. | Inhalte bitte in den Fachabteilungen erfragen.";
CM_ SG_ 1420 M10_Text_6_Hybrid "Diese Texte werden projektspezifisch zwischen Motor und Kombi abgestimmt. | Inhalte bitte in den Fachabteilungen erfragen.";
CM_ SG_ 1420 M10_Text_7_Hybrid "Diese Texte werden projektspezifisch zwischen Motor und Kombi abgestimmt. | Inhalte bitte in den Fachabteilungen erfragen.";
CM_ SG_ 1420 M10_Text_8_Hybrid "Diese Texte werden projektspezifisch zwischen Motor und Kombi abgestimmt. | Inhalte bitte in den Fachabteilungen erfragen.";
CM_ SG_ 1420 M10_ShiftLockLampe "Bei Automatikstart/Startersteuerung im MSG: In Automatik-Fahrzeugen ist Betaetigen der Bremse Freigabebedingung fuer den Startwunsch. (ergaenzend/alternativ zur Textanzeige)";
CM_ SG_ 1420 MO_Auth_Aufforderung_WFS "WFS";
CM_ SG_ 1420 M10_BMSInfo_gue "Die vom MSG aus dem Hybrid-CAN gespiegelten Daten \"M10_VentilationReq\" und \"M10_BattFanSpd\" sind gueltig (Botschaften vom Hybrid-CAN vor weniger als 1000ms empfangen). | BMS Hybrid Info gueltig";
CM_ SG_ 1420 M10_VentilationReq "BMS fordert bei Climatronic die Oeffnung der Umluftklappe an. Signal wird vom MSG von Hybrid-CAN auf den A-CAN gespiegelt (mBMS_HYB_6, Byte 8, Bit 1 aus Hybrid-CAN DF > V1.5)";
CM_ SG_ 1420 M10_BattFanSpd "Relativwert der Batterieluefter-Ansteuerung bezogen auf Maximalwert. Signal wird vom MSG von Hybrid-CAN auf den A-CAN gespiegelt | (mBMS_HYB_3, Byte 7, Bit 7..4 aus Hybrid-CAN DF > V1.5)";
CM_ SG_ 1420 M10_MotorStopp "Motor-Stopp durch Start-Stopp-Koordinator. Das Signal wird nur bei einem Motorstopp durch den Start-Stopp-Koordinator gesetzt. Bei Abwuergen des Motors oder nach Abstellen des Motors ueber KL15 (Nachlauf) bleibt das Signal inaktiv. | Stopp-Modus aktiv wird erst nach Wiederstartende zurueckgenommen, wenn der Motor stabil laeuft und Moment abgefordert werden kann.";
CM_ SG_ 1420 M10_Schubabschaltung "ESP plausibilisiert Unterdrucksensor nur bei aktiver Schubabschaltung | Schubabschaltung";
CM_ SG_ 1420 M10_Druck_err_gem "0: mind. eine Modellrechnung wird zur Berechnung des relativen Saugrohrdrucks (Byte 3, Bit 5..0) herangezogen. | 1: Relativer Saugrohrdruck wird ausschliesslich ueber Messgroessen bestimmt. | Rel. Saugrohrdruck errechnet/gemessen";
CM_ SG_ 1420 M10_rel_Saugrohrdruck "Der Wert gibt an, um wieviel mbar der Saugrohrdruck unterhalb des Umgebungsdrucks liegt. Ueberdruck im Saugrohr wird nicht ausgegeben. | 0: Saugrohrdruck >= Umgebungsdruck | Relativer Saugrohrdruck";
CM_ SG_ 1152 MO5_Motortyp "Motor Multiplex-Info (Motortyp) (Code 10) | Bit 3...0: Zweizylinder 2 Dreizylinder 3 Vierzylinder 4 Fuenfzylinder 5 Sechszylinder 6 Achtzylinder 8 Zehnzylinder 10 Zwoelfzylinder 12 Fuenfzehnzylinder 13 Sechzehnzylinder 14 Achtzehnzylinder 15 | Bit 4: Turbo_Motor 0 Saug_Motor 1 | Bit 5: Otto_Motor 0 Diesel_Motor 1";
CM_ SG_ 1152 MO5_Mp_Code "Motor Multiplex-Code und Multiplex-Info sind verkettet; der Multiplex-Code wird nach 4 Uebertragungen weitergeschaltet; dieser Mechanismus wiederholt sich somit nach 4 x 4 = 16 Umlaufzeiten";
CM_ SG_ 1152 MO5_max_Moment "Motor Multiplex-Info (maximales Drehmoment) (Code 00)";
CM_ SG_ 1152 MO5_Drehzahl "Motor Multiplex-Info (Drehzahl bei max. Drehmoment) (Code 01)";
CM_ SG_ 1152 MO5_Abgastyp "Motor Multiplex-Info (Abgastyp) (Code 11) | (Info: war \"normierter Verbrauch\" teilw. noch im PQ25, T5GP)";
CM_ SG_ 1152 MO5_Abgastyp2 "Motor Multiplex-Info (Abgastyp) (Code 11) | (Info: war \"normierter Verbrauch\" teilw. noch im PQ25, T5GP)";
CM_ SG_ 1152 MO5_Abgastyp3 "Motor Multiplex-Info (Abgastyp) (Code 11) | (Info: war \"normierter Verbrauch\" teilw. noch im PQ25, T5GP)";
CM_ SG_ 1152 OBD_Kaltstart_Denominator "Bestimmte Diagnosen werden nur unter Kaltstartbedingungen durchgefuehrt, der entsprechende Denominator bei IUMPR-pflichtigen Systemen wird anhand dieses vom MSG gebildeten Signals inkrementiert. (Entspricht EVAP-Denominator)";
CM_ SG_ 1152 OBD_Minimum_Trip "Grundlage OBD-Gesetz CCR 1968.2 (d)(4.3) Denominator Specifications | Bildung des General Denominator \"Normed Trip\": | - 600 sec. (kumulativ) Zeit nach Motorstart | - 300 sec. (kumulativ) mit Fahrzeuggeschwindigkeit > 25 mph (40 km/h) | - 30 sec. (kontinuierlich) Leerlauf | Wenn alle diese Bedingungen erfuellt wurden ist ein OBD_Min_Normed_Trip erfuellt.";
CM_ SG_ 1152 MO5_DPF_reg "Motor Multiplex-Info (Abgastyp) (Code 11) | (Info: war \"normierter Verbrauch\" teilw. noch im PQ25, T5GP)";
CM_ SG_ 1152 MO5_Vorgluehen "Diesel-Vorgluehlampe und Diesel-Systemlampe";
CM_ SG_ 1152 MO5_E_Gas "E-Gas Systemlampe (nicht bei Diesel-Projekten)";
CM_ SG_ 1152 MO5_OBD_2 "OBD bzw MIL Lampe wird vom Motorsteuergeraet angesteuert, die Information in der Getriebe 1 Botschaft (Byte 6, Bit 7..4) wird vom Motorsteuergeraet an das Kombi weitergereicht";
CM_ SG_ 1152 MO5_Heissl "Ansteuerung der Kuehlwassertemperatur-Heissleuchte (Sensor nur noch am Motorsteuergeraet): Temperatur-Schaltschwellen mit Hysterese (bei VW D1/Colorado Kombi derzeit noch nicht genutzt)";
CM_ SG_ 1152 MO5_KlimaKompr "Motor-Steuergeraet schaltet Klimakompressor aus";
CM_ SG_ 1152 MO5_Feld_kuehl "Die Kennfeldkuehlung ist in diesem Fahrzeug verbaut und hat keinen Systemfehler";
CM_ SG_ 1152 MO5_KliKo_Red "Klimakompressor-Leistungsreduzierung";
CM_ SG_ 1152 MO5_Verbrauch "Motor-Steuergeraet interner Verbrauchszaehler, der vom Kombi zyklisch ausgelesen wird, um die Einspritzmenge zur Verbrauchsberechnung aufzusummieren; aus diesem Zaehlerstand werden Momentan- und Durchschnittsverbrauch berechnet; das Ueberlauf-Bit (Byte 4, Bit 7) ist zu beruecksichtigen | | Hinweis Erdgas-Projekt: Bei Erdgasbetrieb wird die Gas-Verbrauchsmenge in Einheit mg ausgegeben.";
CM_ SG_ 1152 MO5_UeberlVerb "Der Motor-Steuergeraet interne Verbrauchszaehler ist mindestens einmal uebergelaufen. Dieses Bit wird genutzt, um erkennen zu koennen, das das Motorsteuergeraet aus dem Reset-Zustand hochlaeuft";
CM_ SG_ 1152 MO5_Luefter "Istzustand der Kuehlerluefteransteuerung ueber die PWM Schnittstelle | Luefterstufen (z.B. 14) werden in Prozente umgerechnet | Werte > 100% sind unzulaessig (Mittelwert bei zwei Lueftern) | Kuehlerluefteransteuerung (Motor 5)";
CM_ SG_ 1152 MO5_HLeuchte "Klimaanlage musste aufgrund einer Uebertemperaturerkennung abgeschaltet werden (Schwelle entspricht der Heissleuchtenvorwarnschwelle) | Heissleuchtenvorwarnung";
CM_ SG_ 1152 MO5_PartikelLamp "Partikelfilter-Lampe wird eingeschaltet";
CM_ SG_ 1152 MO5_Sta_BKU "Der Defekt der elektrischen Pumpe zur Verbesserung der Unterdruckversorgung wird angezeigt (nur Porsche Colorado) | Fehlerstatus Bremskraftunterstuetzungspumpe";
CM_ SG_ 1152 MO5_TypStartSteu "Startersteuerung durch das MSG bedeutet entweder manueller Start gesteuert vom MSG, Automatikstart gesteuert vom MSG oder SULEV-Automatikstart (PQ35/46) mit Startersteuerung im MSG und Relaisansteuerung durch das BCM | Typ Startersteuerung";
CM_ SG_ 1152 MO5_TDE_Lampe "Ansteuerung Tankdeckel-Warnlampe Kombiinstrument (nur Ottomotoren)";
CM_ SG_ 1152 MO5_TDE_Text "Anzeige im Kombiinstrument, dass Tankdeckel offen sein koennte (nur Ottomotoren) | Motortext-Bit Tankdeckelwarnung";
CM_ SG_ 1152 MO5_DZM_Daempf "Daempfungskonstanten des Drehzahlmessers im Kombi koennen umgeschaltet werden";
CM_ SG_ 1152 MO5_Interlock "Interlockschalter muss beim Handschalter betaetigt sein, damit ein Motorstart erlaubt ist (z.Zt. bei Audi-Handschalter mit Automatikstart und VW mit Automatikstart) | Bei Stufenautomaten (VW) wird Bit abhaengig von PN gesetzt.";
CM_ SG_ 1152 MO5_Start "Bit wird gesetzt, wenn der Motor beim Automatikstart (nur im VW D1/Colorado Otto; nicht bei sonstigen Audi) gestartet werden darf (Motorstillstand, Emissionsmassnahmen sind erfuellt,..) | Anlasser Freigabe";
CM_ SG_ 1152 MO5_Anlasser "\"Anlasser darf angesteuert werden\" bedeutet bei \"Typ Startersteuerung = 0\", dass die externe Startersteuerung im BSG/BCM/Kessy den Anlasser aus Motorsicht ansteuern darf. | Bei \"Typ Startersteuerung = 1\" bedeutet es, dass eine KL50-Anforderung an das MSG zum Start fuehren wird. (Beim SULEV-Automatikstart wurde vor PQ35GP fuer das BSG hier dauerhaft \"0\" ausgegeben. Ab PQ35GP Bedienung gemaess Spezifikation.) | Anlasser Ausspuren";
CM_ SG_ 1152 MO5_GRA_Hauptsch "z.Zt. bei VW (nicht bei Audi): Schalter gerastet ein (bei Taster der Ausgang des Status Flipflops) | Porsche: Anforderungen GRA-Bereitschafts-Lampe an/aus | GRA-Hauptschalter/ GRA-Bereitschaft";
CM_ SG_ 1152 MO5_Momente "Normwert MDI wird verdoppelt | Doppelte Momente";
CM_ SG_ 1152 MO5_Motortext1 "Text 1: Motorstrg Werkstatt | (im Audi TTRS: \"Werkstatt aufsuchen\")";
CM_ SG_ 1152 MO5_Motortext2 "Text 2: Abgas Werkstatt (wg. Gesetzesbestimmungen nicht mehr verwenden)";
CM_ SG_ 1152 MO5_Motortext3 "Text 3: Fehler im Kraftstoffsystem";
CM_ SG_ 1152 MO5_Motortext4 "Text 4: Partikelfilter benoetigt Regeneration";
CM_ SG_ 1152 MO5_Checksumme "Pruefsumme mit Endwert 0x0, Definition im CAN Lastenheft (HS-CAN V4.2a, LS-CAN V1.42)";
CM_ SG_ 1408 MFN_Warmup_Cycle "Mit dem WarmUp Cycle wird der Verlernzaehler im Gateway inkrementiert";
CM_ SG_ 1408 MFN_Zaehler "ueberlaufender Botschaftszaehler, die Bits 0 und 1 werden zum Multiplexen der Bytes 2..8 benutzt | (Hinweis: Im dbc-File nur wg. Nutzung als Multiplexor auf zwei Signale aufgetrennt, Bit 3..0 ist aber als ein Signal (Zaehler) umzusetzen)";
CM_ SG_ 1408 MFN_Zaehler_278 "ueberlaufender Botschaftszaehler, die Bits 0 und 1 werden zum Multiplexen der Bytes 2..8 benutzt | (Hinweis: Im dbc-File nur wg. Nutzung als Multiplexor auf zwei Signale aufgetrennt, Bit 3..0 ist aber als ein Signal (Zaehler) umzusetzen)";
CM_ SG_ 1408 MFN_Verbrenn_Typ "Unterscheidung otto oder dieselspezifische Groessen | Verbrennungsart";
CM_ SG_ 1408 MFN_Motorleistung "Byte 1 Bit 0 = 0, d.h. bei Zaehlerstand 0,2,4,6,8,10,12,14 Wiederholrate 2 sec | maximale Motorleistung (Byte 6 + MSB in Byte 7 Bit 0)";
CM_ SG_ 1408 MFN_Motorleistung_281 "Byte 1 Bit 0 = 0, d.h. bei Zaehlerstand 0,2,4,6,8,10,12,14 Wiederholrate 2 sec | maximale Motorleistung (Byte 6 + MSB in Byte 7 Bit 0)";
CM_ SG_ 1408 MFN_Hubraum "Byte 1 Bit 0 = 0, d.h. bei Zaehlerstand 0,2,4,6,8,10,12,14 Wiederholrate 2 sec | Hubraum";
CM_ SG_ 1408 MFN_Hubraum_283 "Byte 1 Bit 0 = 0, d.h. bei Zaehlerstand 0,2,4,6,8,10,12,14 Wiederholrate 2 sec | Hubraum";
CM_ SG_ 1408 MFN_Drive_Cycle "Driving Cycle";
CM_ SG_ 1408 MFN_NormedTrip "gesetzlich definierte 'Normed Condition' erfuellt; 'General Denominator' darf erhoeht werden";
CM_ SG_ 1408 MFN_Russindex "Byte 1 Bit 0 = 0, d.h. bei Zaehlerstand 0,2,4,6,8,10,12,14 Wiederholrate 2 sec | Ist beim Dieselmotor ein von Motordrehzahl und der Einspritzmenge abhaengiger Russwert, beim Ottomotor ist der Wert 0 | 0000H Motor aus | FFFFH .. unplausibler/fehlerhafter Wert | Russaequivalent";
CM_ SG_ 1408 MFN_Verschl "Byte 1 Bit 0 = 1, d.h. bei Zaehlerstand 1,3,5,7,9,11,13,15 Wiederholrate 2 sec | Ist beim Dieselmotor ein von der Motordrehzahl und der Oeltemperatur abhaengiger Verschleisswert, beim Ottomotor ein Verbrauchsaequivalent , das von der Oeltemperatur, dem Fuellstand und dem Verbrauch abhaengt | 0000H Motor aus | FFFFH . unplausibler/fehlerhafter Wert | Verschleiss- bzw. Verbrauchsaequivalent";
CM_ SG_ 1408 MFN_Russindex_1488 "Byte 1 Bit 0 = 0, d.h. bei Zaehlerstand 0,2,4,6,8,10,12,14 Wiederholrate 2 sec | Ist beim Dieselmotor ein von Motordrehzahl und der Einspritzmenge abhaengiger Russwert, beim Ottomotor ist der Wert 0 | 0000H Motor aus | FFFFH .. unplausibler/fehlerhafter Wert | Russaequivalent";
CM_ SG_ 1408 MFN_Verschl_1489 "Byte 1 Bit 0 = 1, d.h. bei Zaehlerstand 1,3,5,7,9,11,13,15 Wiederholrate 2 sec | Ist beim Dieselmotor ein von der Motordrehzahl und der Oeltemperatur abhaengiger Verschleisswert, beim Ottomotor ein Verbrauchsaequivalent , das von der Oeltemperatur, dem Fuellstand und dem Verbrauch abhaengt | 0000H Motor aus | FFFFH . unplausibler/fehlerhafter Wert | Verschleiss- bzw. Verbrauchsaequivalent";
CM_ SG_ 1408 MFN_Drz_max_Mo "Byte 1 Bit 0 = 0, d.h. bei Zaehlerstand 0,2,4,6,8,10,12,14 Wiederholrate 2 sec | Drehzahl fuer maximales Moment";
CM_ SG_ 1408 MFN_KurzzeitMW "Byte 1 Bit 0 = 1 und Bit 1 = 0, d.h. bei Zaehlerstand 1,5,9,13 Wiederholrate 4 sec | gemittelte Oelstandsdifferenz (Differenz aus aktuellen Fuellstandswerte und kompensierter Oelniveauschwelle) bezogen auf Oelwarnschwelle | Kurzzeitmittelwert";
CM_ SG_ 1408 MFN_Drz_max_Mo_1492 "Byte 1 Bit 0 = 0, d.h. bei Zaehlerstand 0,2,4,6,8,10,12,14 Wiederholrate 2 sec | Drehzahl fuer maximales Moment";
CM_ SG_ 1408 MFN_Interv_Wmin "Byte 1 Bit 0 = 1 und Bit 1 = 1, d.h. bei Zaehlerstand 3,7,11,15 Wiederholrate 4 sec | Minimale Kilometeranzahl bis zum Service";
CM_ SG_ 1408 MFN_Fuell_Erk "Ueberfuellungserkennung aktiviert nur fuer WIV 3.1 im Audi C6";
CM_ SG_ 1408 MFN_max_Moment "Byte 1 Bit 0 = 0, d.h. bei Zaehlerstand 0,2,4,6,8,10,12,14 Wiederholrate 2 sec | Maximales Drehmoment";
CM_ SG_ 1408 MFN_Oelstand "Byte 1 Bit 0 = 1 und Bit 1 = 0, d.h. bei Zaehlerstand 1,5,9,13 Wiederholrate 4 sec | Anzahl der in die gemittelte Oelstandsdifferenz eingeflossenen Differenzen | Oelstandszaehler";
CM_ SG_ 1408 MFN_max_Moment_1497 "Byte 1 Bit 0 = 0, d.h. bei Zaehlerstand 0,2,4,6,8,10,12,14 Wiederholrate 2 sec | Maximales Drehmoment";
CM_ SG_ 1408 MFN_Interv_Wmax "Byte 1 Bit 0 = 1 und Bit 1 = 1, d.h. bei Zaehlerstand 3,7,11,15 Wiederholrate 4 sec | Maximale Kilometeranzahl bis zum Service";
CM_ SG_ 1408 MFN_Oelwarnung "Byte 1 Bit 0 = 1 und Bit 1 = 0, d.h. bei Zaehlerstand 1,5,9,13 Wiederholrate 4 sec | aktive Warnmoeglichkeit vom Motor (Vorhalt)";
CM_ SG_ 1408 MFN_Sensorwarn "Byte 1 Bit 0 = 1 und Bit 1 = 0, d.h. bei Zaehlerstand 1,5,9,13 Wiederholrate 4 sec | Sensorwarnung bei unplausiblen oder fehlendem Signal";
CM_ SG_ 1408 MFN_MaxOelst "Byte 1 Bit 0 = 1 und Bit 1 = 1, d.h. bei Zaehlerstand 3,7,11,15 Wiederholrate 4 sec | Schwellwert fuer Maximum-Oelstand (entspricht der oberen Markierung am Peilstab) (nur fuer WIV 3.1 im Audi C6)";
CM_ SG_ 1408 MFN_AnzMitOel "Byte 1 Bit 0 = 1 und Bit 1 = 0, d.h. bei Zaehlerstand 1,5,9,13 Wiederholrate 4 sec | Geforderte Anzahl Oelstandsdifferenzen fuer die Auswertung des schnellen Oelfuellstandsmittelwertes (nur fuer WIV 3.1 im Audi C6)";
CM_ SG_ 1408 MFN_Max_Offset "Byte 1 Bit 0 = 1 und Bit 1 = 0, d.h. bei Zaehlerstand 1,5,9,13 Wiederholrate 4 sec | Offset auf den Maximum-Oelstand, ab dem Ueberfuellung erkannt werden soll (nur fuer WIV 3.1 im Audi C6)";
CM_ SG_ 1408 MFN_Anz_Mittel "Byte 1 Bit 0 = 1 und Bit 1 = 1, d.h. bei Zaehlerstand 3,7,11,15 Wiederholrate 4 sec | Minimale geforderte Anzahl der Oelstandsdifferenzen fuer Auswertung | Anzahl Mittelung / Anzahl Mittelung genauer Oelstandsmittelwert";
CM_ SG_ 1408 MFN_Fuell_Hyst "Byte 1 Bit 0 = 1 und Bit 1 = 0, d.h. bei Zaehlerstand 1,5,9,13 Wiederholrate 4 sec | Nach erfolgter Ueberfuellungserkennung muss der nachfolgende Oelstand-Kurzzeitmittelwert diese Hysterese unterschreiten, damit das Ueberfuellungsbit zurueckgesetzt wird (nur fuer WIV 3.1 im Audi C6) | Ueberfuellungsschwellen-Hysterese";
CM_ SG_ 1408 MFN_Interv_tmin "Byte 1 Bit 0 = 1 und Bit 1 = 1, d.h. bei Zaehlerstand 3,7,11,15 Wiederholrate 4 sec | Minimales Zeitintervall bis zum Service";
CM_ SG_ 1408 MFN_Ventile "Byte 1 Bit 0 = 0, d.h. bei Zaehlerstand 0,2,4,6,8,10,12,14 Wiederholrate 2 sec | Anzahl der Ventile pro Zylinder";
CM_ SG_ 1408 MFN_Ventile_1508 "Byte 1 Bit 0 = 0, d.h. bei Zaehlerstand 0,2,4,6,8,10,12,14 Wiederholrate 2 sec | Anzahl der Ventile pro Zylinder";
CM_ SG_ 1408 MFN_Offset_Nachf "Byte 1 Bit 0 = 1 und Bit 1 = 0, d.h. bei Zaehlerstand 1,5,9,13 Wiederholrate 4 sec | Offset fuer Nachfuellerkennung | Oelwarnschwellen-Offset";
CM_ SG_ 1408 MFN_Interv_tmax "Byte 1 Bit 0 = 1 und Bit 1 = 1, d.h. bei Zaehlerstand 3,7,11,15 Wiederholrate 4 sec | Maximales Zeitintervall bis zum Service";
CM_ SG_ 1408 MFN_Tol_Oelwarn "Byte 1 Bit 0 = 1 und Bit 1 = 0, d.h. bei Zaehlerstand 1,5,9,13 Wiederholrate 4 sec | Toleranz fuer Oelwarnschwelle bei geringer Restlaufstrecke";
CM_ SG_ 1408 MFN_Str_Mittel "Byte 1 Bit 0 = 1 und Bit 1 = 1, d.h. bei Zaehlerstand 3,7,11,15 Wiederholrate 4 sec | Minimal geforderte Fahrstrecke fuer Oelstandsauswertung";
CM_ SG_ 1408 MFN_Ansaugsys "Byte 1 Bit 0 = 0, d.h. bei Zaehlerstand 0,2,4,6,8,10,12,14 Wiederholrate 2 sec | Ansaugsystem";
CM_ SG_ 1408 MFN_Ansaugsys_1514 "Byte 1 Bit 0 = 0, d.h. bei Zaehlerstand 0,2,4,6,8,10,12,14 Wiederholrate 2 sec | Ansaugsystem";
CM_ SG_ 1408 MFN_Zylinder "Byte 1 Bit 0 = 0, d.h. bei Zaehlerstand 0,2,4,6,8,10,12,14 Wiederholrate 2 sec | Anzahl der Zylinder (1xWert bis 12 Zyl.,13 = 15 Zyl., 14 = 16 Zyl., 15 = 18 Zyl.)";
CM_ SG_ 1408 MFN_Zylinder_2161 "Byte 1 Bit 0 = 0, d.h. bei Zaehlerstand 0,2,4,6,8,10,12,14 Wiederholrate 2 sec | Anzahl der Zylinder (1xWert bis 12 Zyl.,13 = 15 Zyl., 14 = 16 Zyl., 15 = 18 Zyl.)";
BA_DEF_ BO_ "GenMsgCycleTime" INT 0 65535;
BA_DEF_ BO_ "GenMsgSendType" STRING ;
BA_DEF_ SG_ "GenSigSendType" STRING ;
BA_DEF_DEF_ "GenMsgCycleTime" 0;
BA_DEF_DEF_ "GenMsgSendType" "";
BA_DEF_DEF_ "GenSigSendType" "";
BA_ "GenMsgCycleTime" BO_ 1827 200;
BA_ "GenMsgSendType" BO_ 1827 "NoMsgSendType";
BA_ "GenSigSendType" SG_ 1827 NMH_ABS_Start_1 "Cyclic";
BA_ "GenSigSendType" SG_ 1827 NMH_ABS_Start_2 "Cyclic";
BA_ "GenSigSendType" SG_ 1827 NMH_ABS_Normal_Mode_1 "Cyclic";
BA_ "GenSigSendType" SG_ 1827 NMH_ABS_Normal_Mode_2 "Cyclic";
BA_ "GenSigSendType" SG_ 1827 NMH_ABS_Per_WakeUp "Cyclic";
BA_ "GenSigSendType" SG_ 1827 NMH_ABS_Fkt_WakeUp "Cyclic";
BA_ "GenSigSendType" SG_ 1827 NMH_ABS_NM_aktiv_Klemme_15 "Cyclic";
BA_ "GenSigSendType" SG_ 1827 NMH_ABS_NM_aktiv_Diagnose "Cyclic";
BA_ "GenSigSendType" SG_ 1827 NMH_ABS_NM_aktiv_Start "Cyclic";
BA_ "GenSigSendType" SG_ 1827 NMH_ABS_NL_aktiv_4 "Cyclic";
BA_ "GenSigSendType" SG_ 1827 NMH_ABS_TimeOut_Fehler "Cyclic";
BA_ "GenSigSendType" SG_ 1827 NMH_ABS_CAN_Diag_deaktiv "Cyclic";
BA_ "GenSigSendType" SG_ 1827 NMH_ABS_KompSchutz "Cyclic";
BA_ "GenSigSendType" SG_ 1827 NMH_ABS_Mute_Mode "Cyclic";
BA_ "GenSigSendType" SG_ 1827 NMH_ABS_Transport_Mode "Cyclic";
BA_ "GenSigSendType" SG_ 1827 NMH_ABS_Abschaltstufe_aktiv "Cyclic";
BA_ "GenSigSendType" SG_ 1827 NMH_ABS_Eindraht_Fehler "Cyclic";
BA_ "GenSigSendType" SG_ 1827 NMH_ABS_Car_WakeUp "Cyclic";
BA_ "GenSigSendType" SG_ 1827 NMH_ABS_NL_aktiv_5 "Cyclic";
BA_ "GenSigSendType" SG_ 1827 NMH_ABS_NL_aktiv_6 "Cyclic";
BA_ "GenSigSendType" SG_ 1827 NMH_ABS_NL_aktiv_7 "Cyclic";
BA_ "GenSigSendType" SG_ 1827 NMH_ABS_NL_aktiv_8 "Cyclic";
BA_ "GenSigSendType" SG_ 1827 NMH_ABS_NL_0 "Cyclic";
BA_ "GenSigSendType" SG_ 1827 NMH_ABS_NL_1 "Cyclic";
BA_ "GenSigSendType" SG_ 1827 NMH_ABS_NL_2 "Cyclic";
BA_ "GenSigSendType" SG_ 1827 NMH_ABS_NL_3 "Cyclic";
BA_ "GenSigSendType" SG_ 1827 NMH_ABS_NL_4 "Cyclic";
BA_ "GenSigSendType" SG_ 1827 NMH_ABS_NL_5 "Cyclic";
BA_ "GenSigSendType" SG_ 1827 NMH_ABS_NL_6 "Cyclic";
BA_ "GenSigSendType" SG_ 1827 NMH_ABS_NL_7 "Cyclic";
BA_ "GenMsgSendType" BO_ 768 "NoMsgSendType";
BA_ "GenSigSendType" SG_ 768 TPDyn_Diag_1_1 "OnChange";
BA_ "GenMsgSendType" BO_ 769 "NoMsgSendType";
BA_ "GenSigSendType" SG_ 769 TPDyn_Diag_1_2 "OnChange";
BA_ "GenMsgSendType" BO_ 770 "NoMsgSendType";
BA_ "GenSigSendType" SG_ 770 TPDyn_Diag_1_3 "OnChange";
BA_ "GenMsgSendType" BO_ 771 "NoMsgSendType";
BA_ "GenSigSendType" SG_ 771 TPDyn_Diag_1_4 "OnChange";
BA_ "GenMsgSendType" BO_ 772 "NoMsgSendType";
BA_ "GenSigSendType" SG_ 772 TPDyn_Diag_1_5 "OnChange";
BA_ "GenMsgSendType" BO_ 773 "NoMsgSendType";
BA_ "GenSigSendType" SG_ 773 TPDyn_Diag_1_6 "OnChange";
BA_ "GenMsgSendType" BO_ 774 "NoMsgSendType";
BA_ "GenSigSendType" SG_ 774 TPDyn_Diag_1_7 "OnChange";
BA_ "GenMsgSendType" BO_ 775 "NoMsgSendType";
BA_ "GenSigSendType" SG_ 775 TPDyn_Diag_1_8 "OnChange";
BA_ "GenMsgSendType" BO_ 515 "NoMsgSendType";
BA_ "GenSigSendType" SG_ 515 ABS_TP_Er "OnChange";
BA_ "GenMsgCycleTime" BO_ 1440 20;
BA_ "GenMsgSendType" BO_ 1440 "Cyclic";
BA_ "GenSigSendType" SG_ 1440 BR2_Blinkmode "Cyclic";
BA_ "GenSigSendType" SG_ 1440 BR2_Querbeschl "NoSigSendType";
BA_ "GenSigSendType" SG_ 1440 BR2_Zahnzahl "NoSigSendType";
BA_ "GenSigSendType" SG_ 1440 BR2_Querb_Zahn "Cyclic";
BA_ "GenSigSendType" SG_ 1440 BR2_mi_Radgeschw "Cyclic";
BA_ "GenSigSendType" SG_ 1440 BR2_Lampe_ABS "Cyclic";
BA_ "GenSigSendType" SG_ 1440 BR2_Lampe_ASR "Cyclic";
BA_ "GenSigSendType" SG_ 1440 BR2_Lampe_BK "Cyclic";
BA_ "GenSigSendType" SG_ 1440 BR2_Lampe_RKA "Cyclic";
BA_ "GenSigSendType" SG_ 1440 BR2_Zaehler "Cyclic";
BA_ "GenSigSendType" SG_ 1440 BR2_Text "Cyclic";
BA_ "GenSigSendType" SG_ 1440 BR2_Aku_Warn "Cyclic";
BA_ "GenSigSendType" SG_ 1440 BR2_HDC_aktiv "Cyclic";
BA_ "GenSigSendType" SG_ 1440 BR2_Wegimpulse "Cyclic";
BA_ "GenSigSendType" SG_ 1440 BR2_Ueberl_Imp "Cyclic";
BA_ "GenSigSendType" SG_ 1440 BR2_Fehlereintr "Cyclic";
BA_ "GenSigSendType" SG_ 1440 BR2_LampeHDC "Cyclic";
BA_ "GenSigSendType" SG_ 1440 BR2_QB_Querbeschl "NoSigSendType";
BA_ "GenSigSendType" SG_ 1440 BR2_Sta_Imp "Cyclic";
BA_ "GenSigSendType" SG_ 1440 BR2_Impulszahl "Cyclic";
BA_ "GenSigSendType" SG_ 1440 BR2_SleepInd "Cyclic";
BA_ "GenSigSendType" SG_ 1440 BR2_Sta_Quer "Cyclic";
BA_ "GenMsgCycleTime" BO_ 416 10;
BA_ "GenMsgSendType" BO_ 416 "Cyclic";
BA_ "GenSigSendType" SG_ 416 BR1_ASR_Anf "Cyclic";
BA_ "GenSigSendType" SG_ 416 BR1_MSR_Anf "Cyclic";
BA_ "GenSigSendType" SG_ 416 BR1_ABS_Brems "Cyclic";
BA_ "GenSigSendType" SG_ 416 BR1_EDS_Eingr "Cyclic";
BA_ "GenSigSendType" SG_ 416 BR1_ESP_Eingr "Cyclic";
BA_ "GenSigSendType" SG_ 416 BR1_ASR_Eingr "Cyclic";
BA_ "GenSigSendType" SG_ 416 BR1_EBV_Eingr "Cyclic";
BA_ "GenSigSendType" SG_ 416 BR1_Lampe_ABS "Cyclic";
BA_ "GenSigSendType" SG_ 416 BR1_Lampe_ASR "Cyclic";
BA_ "GenSigSendType" SG_ 416 BR1_Lampe_BK "Cyclic";
BA_ "GenSigSendType" SG_ 416 BR1_Lichtschalt "Cyclic";
BA_ "GenSigSendType" SG_ 416 BR1_StaDruckschw "Cyclic";
BA_ "GenSigSendType" SG_ 416 BR1_Diagnose "Cyclic";
BA_ "GenSigSendType" SG_ 416 BR1_Rad_kmh "Cyclic";
BA_ "GenSigSendType" SG_ 416 BR1_ASRMo_fa "NoSigSendType";
BA_ "GenSigSendType" SG_ 416 BR1_MSR_Mo_inv "NoSigSendType";
BA_ "GenSigSendType" SG_ 416 BR1_MSR_Mo "Cyclic";
BA_ "GenSigSendType" SG_ 416 BR1_Zaehler "Cyclic";
BA_ "GenSigSendType" SG_ 416 BR1_ASR_ESP "Cyclic";
BA_ "GenSigSendType" SG_ 416 BR1_ESPASR_passiv "Cyclic";
BA_ "GenSigSendType" SG_ 416 BR1_Sta_ESP "Cyclic";
BA_ "GenSigSendType" SG_ 416 BR1_Ersatz_Kmh "Cyclic";
BA_ "GenSigSendType" SG_ 416 BR1_MAD "Cyclic";
BA_ "GenSigSendType" SG_ 416 BR1_Sta_MAD "Cyclic";
BA_ "GenSigSendType" SG_ 416 BR1_BKV_aktiv "Cyclic";
BA_ "GenSigSendType" SG_ 416 BR1_ASRMo_sl "Cyclic";
BA_ "GenMsgCycleTime" BO_ 928 20;
BA_ "GenMsgSendType" BO_ 928 "Cyclic";
BA_ "GenSigSendType" SG_ 928 B10_Checksumme "Cyclic";
BA_ "GenSigSendType" SG_ 928 B10_Zaehler "Cyclic";
BA_ "GenSigSendType" SG_ 928 B10_QB_Wegimp_VL "Cyclic";
BA_ "GenSigSendType" SG_ 928 B10_QB_Wegimp_VR "Cyclic";
BA_ "GenSigSendType" SG_ 928 B10_QB_Wegimp_HL "Cyclic";
BA_ "GenSigSendType" SG_ 928 B10_QB_Wegimp_HR "Cyclic";
BA_ "GenSigSendType" SG_ 928 B10_Wegimp_VL "Cyclic";
BA_ "GenSigSendType" SG_ 928 B10_Wegimp_VR "Cyclic";
BA_ "GenSigSendType" SG_ 928 B10_Wegimp_HL "Cyclic";
BA_ "GenSigSendType" SG_ 928 B10_Wegimp_HR "Cyclic";
BA_ "GenSigSendType" SG_ 928 B10_QB_Fahrtr_VL "Cyclic";
BA_ "GenSigSendType" SG_ 928 B10_QB_Fahrtr_VR "Cyclic";
BA_ "GenSigSendType" SG_ 928 B10_QB_Fahrtr_HL "Cyclic";
BA_ "GenSigSendType" SG_ 928 B10_QB_Fahrtr_HR "Cyclic";
BA_ "GenSigSendType" SG_ 928 B10_Fahrtr_VL "Cyclic";
BA_ "GenSigSendType" SG_ 928 B10_Fahrtr_VR "Cyclic";
BA_ "GenSigSendType" SG_ 928 B10_Fahrtr_HL "Cyclic";
BA_ "GenSigSendType" SG_ 928 B10_Fahrtr_HR "Cyclic";
BA_ "GenMsgCycleTime" BO_ 1463 100;
BA_ "GenMsgSendType" BO_ 1463 "Cyclic";
BA_ "GenSigSendType" SG_ 1463 B11_HydHalten "Cyclic";
BA_ "GenSigSendType" SG_ 1463 B11_Br_StSt_Info "Cyclic";
BA_ "GenSigSendType" SG_ 1463 B11_OBD_Nib_VL "Cyclic";
BA_ "GenSigSendType" SG_ 1463 B11_OBD_Nib_VR "Cyclic";
BA_ "GenSigSendType" SG_ 1463 B11_OBD_Nib_HL "Cyclic";
BA_ "GenSigSendType" SG_ 1463 B11_OBD_Nib_HR "Cyclic";
BA_ "GenSigSendType" SG_ 1463 B11_EPB_Steller_akt "Cyclic";
BA_ "GenSigSendType" SG_ 1463 B11_EPB_Steller_gue "Cyclic";
BA_ "GenSigSendType" SG_ 1463 B11_Checksumme "Cyclic";
BA_ "GenSigSendType" SG_ 1463 B11_Zaehler "Cyclic";
BA_ "GenSigSendType" SG_ 1463 B11_Backup_MSR "Cyclic";
BA_ "GenSigSendType" SG_ 1463 OBD_Fehler_Bremsdruck "Cyclic";
BA_ "GenSigSendType" SG_ 1463 ESP_nachtr_Stopp_Anf "Cyclic";
BA_ "GenMsgCycleTime" BO_ 1184 10;
BA_ "GenMsgSendType" BO_ 1184 "Cyclic";
BA_ "GenSigSendType" SG_ 1184 BR3_Rad_kmh_VL "Cyclic";
BA_ "GenSigSendType" SG_ 1184 BR3_Rad_kmh_VR "Cyclic";
BA_ "GenSigSendType" SG_ 1184 BR3_Rad_kmh_HL "Cyclic";
BA_ "GenSigSendType" SG_ 1184 BR3_Rad_kmh_HR "Cyclic";
BA_ "GenSigSendType" SG_ 1184 BR3_Fahrtr_VL "Cyclic";
BA_ "GenSigSendType" SG_ 1184 BR3_Fahrtr_VR "Cyclic";
BA_ "GenSigSendType" SG_ 1184 BR3_Fahrtr_HL "Cyclic";
BA_ "GenSigSendType" SG_ 1184 BR3_Fahrtr_HR "Cyclic";
BA_ "GenMsgCycleTime" BO_ 672 10;
BA_ "GenMsgSendType" BO_ 672 "Cyclic";
BA_ "GenSigSendType" SG_ 672 BR4_Vorgabe_Mi "NoSigSendType";
BA_ "GenSigSendType" SG_ 672 BR4_Einheit "Cyclic";
BA_ "GenSigSendType" SG_ 672 BR4_Schwelle "Cyclic";
BA_ "GenSigSendType" SG_ 672 BR4_Lampentrennung_gue "Cyclic";
BA_ "GenSigSendType" SG_ 672 BR4_Lampe_ASRESP "Cyclic";
BA_ "GenSigSendType" SG_ 672 BR4_ESP_Off "Cyclic";
BA_ "GenSigSendType" SG_ 672 BR1_ASR_ESP "Cyclic";
BA_ "GenSigSendType" SG_ 672 BR4_Unterdruck "Cyclic";
BA_ "GenSigSendType" SG_ 672 BR4_Zaehler "Cyclic";
BA_ "GenSigSendType" SG_ 672 BR4_Checksum "Cyclic";
BA_ "GenSigSendType" SG_ 672 BR4_Vorgabe_Mi_308 "NoSigSendType";
BA_ "GenSigSendType" SG_ 672 BR4_Vorgabe_Max "NoSigSendType";
BA_ "GenSigSendType" SG_ 672 BR4_Vorgabe_Hi "NoSigSendType";
BA_ "GenSigSendType" SG_ 672 BR4_Vorgabe_Min "NoSigSendType";
BA_ "GenSigSendType" SG_ 672 BR4_Abschaltung_VL "Cyclic";
BA_ "GenSigSendType" SG_ 672 BR4_Abschaltung_VR "Cyclic";
BA_ "GenSigSendType" SG_ 672 BR4_Abschaltung_HL "Cyclic";
BA_ "GenSigSendType" SG_ 672 BR4_Abschaltung_HR "Cyclic";
BA_ "GenSigSendType" SG_ 672 BR4_Lampe_RKA "Cyclic";
BA_ "GenSigSendType" SG_ 672 BR4_Summer_RKA "Cyclic";
BA_ "GenSigSendType" SG_ 672 BR4_Status_ESP "Cyclic";
BA_ "GenSigSendType" SG_ 672 BR4_MABS_Verbau "Cyclic";
BA_ "GenSigSendType" SG_ 672 BR4_RKA_Verbau "Cyclic";
BA_ "GenMsgCycleTime" BO_ 1192 20;
BA_ "GenMsgSendType" BO_ 1192 "Cyclic";
BA_ "GenSigSendType" SG_ 1192 BR5_Giergeschw "Cyclic";
BA_ "GenSigSendType" SG_ 1192 BR5_Sta_Gierrate "Cyclic";
BA_ "GenSigSendType" SG_ 1192 BR5_Vorzeichen "Cyclic";
BA_ "GenSigSendType" SG_ 1192 BR5_Bremsdruck "Cyclic";
BA_ "GenSigSendType" SG_ 1192 BR5_Stillstand "Cyclic";
BA_ "GenSigSendType" SG_ 1192 BR5_Druckgueltig "Cyclic";
BA_ "GenSigSendType" SG_ 1192 BR5_Sta_Druck "Cyclic";
BA_ "GenSigSendType" SG_ 1192 BR5_Sign_Druck "Cyclic";
BA_ "GenSigSendType" SG_ 1192 BR5_Bremslicht "Cyclic";
BA_ "GenSigSendType" SG_ 1192 BR5_AWV2_Bremsruck "Cyclic";
BA_ "GenSigSendType" SG_ 1192 BR5_AWV2_Fehler "Cyclic";
BA_ "GenSigSendType" SG_ 1192 BR5_Zaehler "Cyclic";
BA_ "GenSigSendType" SG_ 1192 BR5_Checksumme "Cyclic";
BA_ "GenSigSendType" SG_ 1192 ESP_Rollenmodus_Deaktivieren "Cyclic";
BA_ "GenSigSendType" SG_ 1192 ESP_Stat_FallBack_eBKV "Cyclic";
BA_ "GenSigSendType" SG_ 1192 ESP_Anforderung_EPB "Cyclic";
BA_ "GenSigSendType" SG_ 1192 BR5_Anhi_akt "Cyclic";
BA_ "GenSigSendType" SG_ 1192 BR5_v_Ueberw "Cyclic";
BA_ "GenSigSendType" SG_ 1192 BR5_Fahrer_tritt_ZBR_Schw "Cyclic";
BA_ "GenSigSendType" SG_ 1192 BR5_ECD_Lampe "Cyclic";
BA_ "GenSigSendType" SG_ 1192 ESP_Autohold_aktiv "Cyclic";
BA_ "GenSigSendType" SG_ 1192 ESP_Autohold_Standby "Cyclic";
BA_ "GenSigSendType" SG_ 1192 BR5_Anhi_Sta "Cyclic";
BA_ "GenSigSendType" SG_ 1192 BR5_Notbremsung "Cyclic";
BA_ "GenSigSendType" SG_ 1192 BR5_ZT_Rueckk_Umsetz "Cyclic";
BA_ "GenSigSendType" SG_ 1192 BR5_ANB_CM_Rueckk_Umsetz "Cyclic";
BA_ "GenSigSendType" SG_ 1192 BR5_HDC_bereit "Cyclic";
BA_ "GenMsgCycleTime" BO_ 428 20;
BA_ "GenMsgSendType" BO_ 428 "Cyclic";
BA_ "GenSigSendType" SG_ 428 BR8_Checksumme "Cyclic";
BA_ "GenSigSendType" SG_ 428 BR8_Zaehler "Cyclic";
BA_ "GenSigSendType" SG_ 428 BR8_Sta_ACC_Anf "Cyclic";
BA_ "GenSigSendType" SG_ 428 BR8_Verz_EPB_akt "Cyclic";
BA_ "GenSigSendType" SG_ 428 BR8_Sta_Br_temp "Cyclic";
BA_ "GenSigSendType" SG_ 428 BR8_Sta_Br_Druck "Cyclic";
BA_ "GenSigSendType" SG_ 428 BR8_Istbeschl "Cyclic";
BA_ "GenSigSendType" SG_ 428 BR8_QB_LBeschl "Cyclic";
BA_ "GenSigSendType" SG_ 428 BR8_aktBrSyst "Cyclic";
BA_ "GenSigSendType" SG_ 428 BR8_StaBrSyst "Cyclic";
BA_ "GenSigSendType" SG_ 428 BR8_Laengsbeschl "Cyclic";
BA_ "GenSigSendType" SG_ 428 BR8_Sta_ADR_BR "Cyclic";
BA_ "GenSigSendType" SG_ 428 BR8_Sta_VerzReg "Cyclic";
BA_ "GenSigSendType" SG_ 428 BR8_Verz_EPB "Cyclic";
BA_ "GenSigSendType" SG_ 428 BR8_Check_EPB "Cyclic";
BA_ "GenSigSendType" SG_ 428 BR8_HHC_Haltebestaetigung "Cyclic";
BA_ "GenSigSendType" SG_ 428 BR8_HHC_Signal_QBit "Cyclic";
BA_ "GenSigSendType" SG_ 428 BR8_Sta_HW_BLS "Cyclic";
BA_ "GenSigSendType" SG_ 428 BR8_ESC_Mode "Cyclic";
BA_ "GenSigSendType" SG_ 428 BR8_Fa_bremst "Cyclic";
BA_ "GenSigSendType" SG_ 428 BR8_Quattro "Cyclic";
BA_ "GenSigSendType" SG_ 428 BR8_Sta_BLS "Cyclic";
BA_ "GenSigSendType" SG_ 428 ESP_MKB_ausloesbar "Cyclic";
BA_ "GenSigSendType" SG_ 428 ESP_Haltebestaetigung "Cyclic";
BA_ "GenSigSendType" SG_ 428 ESC_Motorstartverzoegerung "Cyclic";
BA_ "GenMsgCycleTime" BO_ 174 10;
BA_ "GenMsgSendType" BO_ 174 "Cyclic";
BA_ "GenSigSendType" SG_ 174 BR9_Checksumme "Cyclic";
BA_ "GenSigSendType" SG_ 174 BR9_Sta_ESP_PLA "Cyclic";
BA_ "GenSigSendType" SG_ 174 BR9_Zaehler "Cyclic";
BA_ "GenSigSendType" SG_ 174 BR9_LMOffset "Cyclic";
BA_ "GenSigSendType" SG_ 174 BR9_LMOffSign "Cyclic";
BA_ "GenSigSendType" SG_ 174 BR9_LWOffset "Cyclic";
BA_ "GenSigSendType" SG_ 174 BR9_LWOffSign "Cyclic";
BA_ "GenSigSendType" SG_ 174 BR9_Sta_DSR "Cyclic";
BA_ "GenSigSendType" SG_ 174 BR9_PLA_Abbruch "Cyclic";
BA_ "GenMsgSendType" BO_ 1986 "IfActive";
BA_ "GenSigSendType" SG_ 1986 LWI_Init_ID "OnWrite";
BA_ "GenSigSendType" SG_ 1986 LWI_Codierbytes "OnWrite";
BA_ "GenMsgCycleTime" BO_ 912 100;
BA_ "GenMsgSendType" BO_ 912 "Cyclic";
BA_ "GenSigSendType" SG_ 912 GK1_SleepAckn "Cyclic";
BA_ "GenSigSendType" SG_ 912 GK1_Sta_Anhaen "Cyclic";
BA_ "GenSigSendType" SG_ 912 GK1_Sta_Licht1 "Cyclic";
BA_ "GenSigSendType" SG_ 912 GK1_Sta_Tuerkont "Cyclic";
BA_ "GenSigSendType" SG_ 912 GK1_Fa_Tuerkont "Cyclic";
BA_ "GenSigSendType" SG_ 912 GK1_Rueckfahr "Cyclic";
BA_ "GenSigSendType" SG_ 912 GK1_Anhaenger "OnChange";
BA_ "GenSigSendType" SG_ 912 GK1_Wischer_vorn "Cyclic";
BA_ "GenSigSendType" SG_ 912 GK1_Sta_ILM_F_1 "Cyclic";
BA_ "GenSigSendType" SG_ 912 GK1_Warnblk_Status "Cyclic";
BA_ "GenSigSendType" SG_ 912 GK1_Sta_RDK_Warn "Cyclic";
BA_ "GenSigSendType" SG_ 912 GK1_Sta_Licht3 "Cyclic";
BA_ "GenSigSendType" SG_ 912 GK1_Sta_Li_vorn "Cyclic";
BA_ "GenSigSendType" SG_ 912 LIA_Standlicht "OnChange";
BA_ "GenSigSendType" SG_ 912 GK1_CharismaModus "NoSigSendType";
BA_ "GenSigSendType" SG_ 912 GK1_SamFktNr "OnChange";
BA_ "GenSigSendType" SG_ 912 GK1_RueckfahrSch "Cyclic";
BA_ "GenSigSendType" SG_ 912 GK1_ELV_verrieg "OnChange";
BA_ "GenSigSendType" SG_ 912 GK1_Sta_Kessy_2 "Cyclic";
BA_ "GenSigSendType" SG_ 912 GK1_Sta_Stdhzg "Cyclic";
BA_ "GenSigSendType" SG_ 912 GK1_SH_Verbau "Cyclic";
BA_ "GenSigSendType" SG_ 912 GK1_ParkFrontWi "Cyclic";
BA_ "GenSigSendType" SG_ 912 GK1_KW_Warm "OnChange";
BA_ "GenSigSendType" SG_ 912 BCM_Remotestart_Betrieb "Cyclic";
BA_ "GenSigSendType" SG_ 912 BSK_HL_geoeffnet "Cyclic";
BA_ "GenSigSendType" SG_ 912 BSK_HR_geoeffnet "Cyclic";
BA_ "GenSigSendType" SG_ 912 GK1_BrLi_links "Cyclic";
BA_ "GenSigSendType" SG_ 912 GK1_BrLi_rechts "Cyclic";
BA_ "GenSigSendType" SG_ 912 GK1_BrLi_mitte "Cyclic";
BA_ "GenSigSendType" SG_ 912 GK1_BLS_ILM "Cyclic";
BA_ "GenSigSendType" SG_ 912 GK1_EDC_ILM "Cyclic";
BA_ "GenSigSendType" SG_ 912 GK1_Blinker_li "OnChange";
BA_ "GenSigSendType" SG_ 912 GK1_Blinker_re "OnChange";
BA_ "GenSigSendType" SG_ 912 GK1_def_P_verr "Cyclic";
BA_ "GenSigSendType" SG_ 912 GK1_LS1_Fernlicht "Cyclic";
BA_ "GenSigSendType" SG_ 912 GK1_Sta_Licht2 "Cyclic";
BA_ "GenSigSendType" SG_ 912 GK1_Sta_LSM "Cyclic";
BA_ "GenSigSendType" SG_ 912 WI1_Front_Wasch "Cyclic";
BA_ "GenSigSendType" SG_ 912 BSK_BT_geoeffnet "Cyclic";
BA_ "GenSigSendType" SG_ 912 BCM_CV_Taster "OnChange";
BA_ "GenSigSendType" SG_ 912 BSK_HD_Hauptraste "OnChange";
BA_ "GenSigSendType" SG_ 912 BSK_Tankklappe "Cyclic";
BA_ "GenSigSendType" SG_ 912 EV1_Anf_Klemme_50 "OnChange";
BA_ "GenSigSendType" SG_ 912 GK1_BrLi_Anhaen "OnChange";
BA_ "GenSigSendType" SG_ 912 GK1_Abblendlicht "Cyclic";
BA_ "GenSigSendType" SG_ 912 GK1_Fernlicht "Cyclic";
BA_ "GenSigSendType" SG_ 912 GK1_Abbl_VL_def "Cyclic";
BA_ "GenSigSendType" SG_ 912 GK1_Abbl_VR_def "Cyclic";
BA_ "GenSigSendType" SG_ 912 GK1_Blink_Autob "Cyclic";
BA_ "GenSigSendType" SG_ 912 GK1_SH_laeuft "Cyclic";
BA_ "GenSigSendType" SG_ 912 SH1_ein_Wasserpumpe "Cyclic";
BA_ "GenSigSendType" SG_ 912 GK1_Nebel_ein "Cyclic";
BA_ "GenSigSendType" SG_ 912 GK1_Bremslicht "Cyclic";
BA_ "GenSigSendType" SG_ 912 GK1_Anh_abgesteckt "Cyclic";
BA_ "GenSigSendType" SG_ 912 GK1_AnhKonLamp "Cyclic";
BA_ "GenSigSendType" SG_ 912 LDS_Stellung_AFL "Cyclic";
BA_ "GenSigSendType" SG_ 912 GK1_SH_Zusatzfkt "Cyclic";
BA_ "GenSigSendType" SG_ 912 BCM_Offroad_Taster "OnChange";
BA_ "GenMsgCycleTime" BO_ 194 10;
BA_ "GenMsgSendType" BO_ 194 "Cyclic";
BA_ "GenSigSendType" SG_ 194 LW1_Initquelle "Cyclic";
BA_ "GenSigSendType" SG_ 194 LW1_LRW "Cyclic";
BA_ "GenSigSendType" SG_ 194 LW1_LRW_Sign "Cyclic";
BA_ "GenSigSendType" SG_ 194 LW1_ID "Cyclic";
BA_ "GenSigSendType" SG_ 194 LW1_Status "Cyclic";
BA_ "GenSigSendType" SG_ 194 LW1_Sta_KL30 "Cyclic";
BA_ "GenSigSendType" SG_ 194 LW1_Zaehler "Cyclic";
BA_ "GenSigSendType" SG_ 194 LW1_CRC "Cyclic";
BA_ "GenSigSendType" SG_ 194 LW1_Lenk_Gesch "Cyclic";
BA_ "GenSigSendType" SG_ 194 LW1_Gesch_Sign "Cyclic";
BA_ "GenSigSendType" SG_ 194 LW1_Kodier "Cyclic";
BA_ "GenMsgCycleTime" BO_ 1420 100;
BA_ "GenMsgSendType" BO_ 1420 "Cyclic";
BA_ "GenSigSendType" SG_ 1420 M10_StartStopp_Fahrerwunsch "OnChange";
BA_ "GenSigSendType" SG_ 1420 M10_Status_StSt "Cyclic";
BA_ "GenSigSendType" SG_ 1420 M10_Wiederstart "OnChange";
BA_ "GenSigSendType" SG_ 1420 M10_Anzeige "Cyclic";
BA_ "GenSigSendType" SG_ 1420 M10_Anf_Kl75 "OnChange";
BA_ "GenSigSendType" SG_ 1420 MSG_Remotestart_Betrieb "OnChange";
BA_ "GenSigSendType" SG_ 1420 M10_SpannungsAnf "Cyclic";
BA_ "GenSigSendType" SG_ 1420 M10_UDruckDyn "Cyclic";
BA_ "GenSigSendType" SG_ 1420 M10_Freigabe_Reku "Cyclic";
BA_ "GenSigSendType" SG_ 1420 M10_Fahrbereitschaft "Cyclic";
BA_ "GenSigSendType" SG_ 1420 M10_Hybrid "Cyclic";
BA_ "GenSigSendType" SG_ 1420 M10_EM_aktiv "Cyclic";
BA_ "GenSigSendType" SG_ 1420 M10_VM_aktiv "Cyclic";
BA_ "GenSigSendType" SG_ 1420 M10_HYB_Bereitlampe "Cyclic";
BA_ "GenSigSendType" SG_ 1420 M10_HYB_Warnlampe "Cyclic";
BA_ "GenSigSendType" SG_ 1420 M10_HYB_Fehlerlampe "Cyclic";
BA_ "GenSigSendType" SG_ 1420 M10_Fehler_HV_Netz "Cyclic";
BA_ "GenSigSendType" SG_ 1420 M10_EKlKomLeiRed "Cyclic";
BA_ "GenSigSendType" SG_ 1420 M10_Klimadruck "Cyclic";
BA_ "GenSigSendType" SG_ 1420 M10_KompAusCode "Cyclic";
BA_ "GenSigSendType" SG_ 1420 M10_Akustik "Cyclic";
BA_ "GenSigSendType" SG_ 1420 M10_Text_1_Hybrid "Cyclic";
BA_ "GenSigSendType" SG_ 1420 M10_Text_2_Hybrid "Cyclic";
BA_ "GenSigSendType" SG_ 1420 M10_Text_3_Hybrid "Cyclic";
BA_ "GenSigSendType" SG_ 1420 M10_Text_4_Hybrid "Cyclic";
BA_ "GenSigSendType" SG_ 1420 M10_Text_5_Hybrid "Cyclic";
BA_ "GenSigSendType" SG_ 1420 M10_Text_6_Hybrid "Cyclic";
BA_ "GenSigSendType" SG_ 1420 M10_Text_7_Hybrid "Cyclic";
BA_ "GenSigSendType" SG_ 1420 M10_Text_8_Hybrid "Cyclic";
BA_ "GenSigSendType" SG_ 1420 M10_ShiftLockLampe "Cyclic";
BA_ "GenSigSendType" SG_ 1420 MO_Auth_Aufforderung_WFS "OnChange";
BA_ "GenSigSendType" SG_ 1420 M10_BMSInfo_gue "Cyclic";
BA_ "GenSigSendType" SG_ 1420 M10_VentilationReq "Cyclic";
BA_ "GenSigSendType" SG_ 1420 M10_BattFanSpd "Cyclic";
BA_ "GenSigSendType" SG_ 1420 M10_MotorStopp "OnChange";
BA_ "GenSigSendType" SG_ 1420 M10_Schubabschaltung "Cyclic";
BA_ "GenSigSendType" SG_ 1420 M10_Druck_err_gem "Cyclic";
BA_ "GenSigSendType" SG_ 1420 M10_rel_Saugrohrdruck "Cyclic";
BA_ "GenMsgCycleTime" BO_ 1152 20;
BA_ "GenMsgSendType" BO_ 1152 "Cyclic";
BA_ "GenSigSendType" SG_ 1152 MO5_Motortyp "NoSigSendType";
BA_ "GenSigSendType" SG_ 1152 MO5_Mp_Code "Cyclic";
BA_ "GenSigSendType" SG_ 1152 MO5_max_Moment "NoSigSendType";
BA_ "GenSigSendType" SG_ 1152 MO5_Drehzahl "NoSigSendType";
BA_ "GenSigSendType" SG_ 1152 MO5_Abgastyp "NoSigSendType";
BA_ "GenSigSendType" SG_ 1152 MO5_Abgastyp2 "NoSigSendType";
BA_ "GenSigSendType" SG_ 1152 MO5_Abgastyp3 "NoSigSendType";
BA_ "GenSigSendType" SG_ 1152 OBD_Kaltstart_Denominator "NoSigSendType";
BA_ "GenSigSendType" SG_ 1152 OBD_Minimum_Trip "NoSigSendType";
BA_ "GenSigSendType" SG_ 1152 MO5_DPF_reg "NoSigSendType";
BA_ "GenSigSendType" SG_ 1152 MO5_Vorgluehen "Cyclic";
BA_ "GenSigSendType" SG_ 1152 MO5_E_Gas "Cyclic";
BA_ "GenSigSendType" SG_ 1152 MO5_OBD_2 "Cyclic";
BA_ "GenSigSendType" SG_ 1152 MO5_Heissl "Cyclic";
BA_ "GenSigSendType" SG_ 1152 MO5_KlimaKompr "Cyclic";
BA_ "GenSigSendType" SG_ 1152 MO5_Feld_kuehl "Cyclic";
BA_ "GenSigSendType" SG_ 1152 MO5_KliKo_Red "Cyclic";
BA_ "GenSigSendType" SG_ 1152 MO5_Verbrauch "Cyclic";
BA_ "GenSigSendType" SG_ 1152 MO5_UeberlVerb "Cyclic";
BA_ "GenSigSendType" SG_ 1152 MO5_Luefter "Cyclic";
BA_ "GenSigSendType" SG_ 1152 MO5_HLeuchte "Cyclic";
BA_ "GenSigSendType" SG_ 1152 MO5_PartikelLamp "Cyclic";
BA_ "GenSigSendType" SG_ 1152 MO5_Sta_BKU "Cyclic";
BA_ "GenSigSendType" SG_ 1152 MO5_TypStartSteu "Cyclic";
BA_ "GenSigSendType" SG_ 1152 MO5_TDE_Lampe "Cyclic";
BA_ "GenSigSendType" SG_ 1152 MO5_TDE_Text "Cyclic";
BA_ "GenSigSendType" SG_ 1152 MO5_DZM_Daempf "Cyclic";
BA_ "GenSigSendType" SG_ 1152 MO5_Interlock "Cyclic";
BA_ "GenSigSendType" SG_ 1152 MO5_Start "Cyclic";
BA_ "GenSigSendType" SG_ 1152 MO5_Anlasser "Cyclic";
BA_ "GenSigSendType" SG_ 1152 MO5_GRA_Hauptsch "Cyclic";
BA_ "GenSigSendType" SG_ 1152 MO5_Momente "Cyclic";
BA_ "GenSigSendType" SG_ 1152 MO5_Motortext1 "Cyclic";
BA_ "GenSigSendType" SG_ 1152 MO5_Motortext2 "Cyclic";
BA_ "GenSigSendType" SG_ 1152 MO5_Motortext3 "Cyclic";
BA_ "GenSigSendType" SG_ 1152 MO5_Motortext4 "Cyclic";
BA_ "GenSigSendType" SG_ 1152 MO5_Checksumme "Cyclic";
BA_ "GenMsgCycleTime" BO_ 1408 1000;
BA_ "GenMsgSendType" BO_ 1408 "Cyclic";
BA_ "GenSigSendType" SG_ 1408 MFN_Warmup_Cycle "Cyclic";
BA_ "GenSigSendType" SG_ 1408 MFN_Zaehler "Cyclic";
BA_ "GenSigSendType" SG_ 1408 MFN_Zaehler_278 "Cyclic";
BA_ "GenSigSendType" SG_ 1408 MFN_Verbrenn_Typ "Cyclic";
BA_ "GenSigSendType" SG_ 1408 MFN_Motorleistung "NoSigSendType";
BA_ "GenSigSendType" SG_ 1408 MFN_Motorleistung_281 "NoSigSendType";
BA_ "GenSigSendType" SG_ 1408 MFN_Hubraum "NoSigSendType";
BA_ "GenSigSendType" SG_ 1408 MFN_Hubraum_283 "NoSigSendType";
BA_ "GenSigSendType" SG_ 1408 MFN_Drive_Cycle "Cyclic";
BA_ "GenSigSendType" SG_ 1408 MFN_NormedTrip "Cyclic";
BA_ "GenSigSendType" SG_ 1408 MFN_Russindex "NoSigSendType";
BA_ "GenSigSendType" SG_ 1408 MFN_Verschl "NoSigSendType";
BA_ "GenSigSendType" SG_ 1408 MFN_Russindex_1488 "NoSigSendType";
BA_ "GenSigSendType" SG_ 1408 MFN_Verschl_1489 "NoSigSendType";
BA_ "GenSigSendType" SG_ 1408 MFN_Drz_max_Mo "NoSigSendType";
BA_ "GenSigSendType" SG_ 1408 MFN_KurzzeitMW "NoSigSendType";
BA_ "GenSigSendType" SG_ 1408 MFN_Drz_max_Mo_1492 "NoSigSendType";
BA_ "GenSigSendType" SG_ 1408 MFN_Interv_Wmin "NoSigSendType";
BA_ "GenSigSendType" SG_ 1408 MFN_Fuell_Erk "NoSigSendType";
BA_ "GenSigSendType" SG_ 1408 MFN_max_Moment "NoSigSendType";
BA_ "GenSigSendType" SG_ 1408 MFN_Oelstand "NoSigSendType";
BA_ "GenSigSendType" SG_ 1408 MFN_max_Moment_1497 "NoSigSendType";
BA_ "GenSigSendType" SG_ 1408 MFN_Interv_Wmax "NoSigSendType";
BA_ "GenSigSendType" SG_ 1408 MFN_Oelwarnung "NoSigSendType";
BA_ "GenSigSendType" SG_ 1408 MFN_Sensorwarn "NoSigSendType";
BA_ "GenSigSendType" SG_ 1408 MFN_MaxOelst "NoSigSendType";
BA_ "GenSigSendType" SG_ 1408 MFN_AnzMitOel "NoSigSendType";
BA_ "GenSigSendType" SG_ 1408 MFN_Max_Offset "NoSigSendType";
BA_ "GenSigSendType" SG_ 1408 MFN_Anz_Mittel "NoSigSendType";
BA_ "GenSigSendType" SG_ 1408 MFN_Fuell_Hyst "NoSigSendType";
BA_ "GenSigSendType" SG_ 1408 MFN_Interv_tmin "NoSigSendType";
BA_ "GenSigSendType" SG_ 1408 MFN_Ventile "NoSigSendType";
BA_ "GenSigSendType" SG_ 1408 MFN_Ventile_1508 "NoSigSendType";
BA_ "GenSigSendType" SG_ 1408 MFN_Offset_Nachf "NoSigSendType";
BA_ "GenSigSendType" SG_ 1408 MFN_Interv_tmax "NoSigSendType";
BA_ "GenSigSendType" SG_ 1408 MFN_Tol_Oelwarn "NoSigSendType";
BA_ "GenSigSendType" SG_ 1408 MFN_Str_Mittel "NoSigSendType";
BA_ "GenSigSendType" SG_ 1408 MFN_Ansaugsys "NoSigSendType";
BA_ "GenSigSendType" SG_ 1408 MFN_Ansaugsys_1514 "NoSigSendType";
BA_ "GenSigSendType" SG_ 1408 MFN_Zylinder "NoSigSendType";
BA_ "GenSigSendType" SG_ 1408 MFN_Zylinder_2161 "NoSigSendType";
VAL_ 1827 NMH_ABS_Start_1 1 "START_v_SLEEP" ;
VAL_ 1827 NMH_ABS_Start_2 1 "START_v_PREP_TO_SLEEP" ;
VAL_ 1827 NMH_ABS_Normal_Mode_1 1 "NORMAL_MODE_v_START" ;
VAL_ 1827 NMH_ABS_Normal_Mode_2 1 "NORMAL_MODE_v_READY_TO_SLEEP" ;
VAL_ 1827 NMH_ABS_Per_WakeUp 3 "KL_15_HW" 2 "P_Wakeup_Ursache_unbekannt" 1 "CAN" 0 "Funktionswakeup" ;
VAL_ 1827 NMH_ABS_Fkt_WakeUp 0 "Peripheriewakeup" ;
VAL_ 1827 NMH_ABS_NM_aktiv_Klemme_15 1 "Klemme_15_ein" ;
VAL_ 1827 NMH_ABS_NM_aktiv_Diagnose 1 "Diagnose_bei_Kl_15_aus" ;
VAL_ 1827 NMH_ABS_NM_aktiv_Start 1 "Mindestaktivzeit_START" ;
VAL_ 1827 NMH_ABS_NL_aktiv_4 1 "kein_Stillstand_aller_Raeder_erkannt" ;
VAL_ 1827 NMH_ABS_TimeOut_Fehler 1 "Timeout_Fehlereintrag" ;
VAL_ 1827 NMH_ABS_CAN_Diag_deaktiv 1 "keine_CANbez_Eigendiag" ;
VAL_ 1827 NMH_ABS_KompSchutz 1 "Komponentenschutz_aktiv" ;
VAL_ 1827 NMH_ABS_Mute_Mode 1 "Mute_Mode_aktiv" ;
VAL_ 1827 NMH_ABS_Transport_Mode 1 "Transport_Mode_aktiv" ;
VAL_ 1827 NMH_ABS_Abschaltstufe_aktiv 1 "Abschaltstufe_aktiv" ;
VAL_ 1827 NMH_ABS_Eindraht_Fehler 1 "Eindrahtbetrieb_erkannt" ;
VAL_ 1827 NMH_ABS_Car_WakeUp 1 "Car_WakeUp" ;
VAL_ 1827 NMH_ABS_NL_aktiv_5 1 "Nachlaufursache_5" ;
VAL_ 1827 NMH_ABS_NL_aktiv_6 1 "Nachlaufursache_6" ;
VAL_ 1827 NMH_ABS_NL_aktiv_7 1 "Nachlaufursache_7" ;
VAL_ 1827 NMH_ABS_NL_aktiv_8 1 "Nachlaufursache_8" ;
VAL_ 1440 BR2_Blinkmode 1 "Ein" 0 "Aus" ;
VAL_ 1440 BR2_Querbeschl 255 "Fehler" ;
VAL_ 1440 BR2_Querb_Zahn 1 "Zaehnezahl_in_Byte_1" 0 "Querbeschl_In_Byte1" ;
VAL_ 1440 BR2_mi_Radgeschw 32742 "Sensorfehler" 32725 "Unterspannung" 32708 "Init_PQ25_35_46" ;
VAL_ 1440 BR2_Lampe_ABS 1 "Lampe_ein" 0 "Lampe_aus" ;
VAL_ 1440 BR2_Lampe_ASR 1 "Lampe_ein" 0 "Lampe_aus" ;
VAL_ 1440 BR2_Lampe_BK 1 "Lampe_ein" 0 "Lampe_aus" ;
VAL_ 1440 BR2_Lampe_RKA 1 "Lampe_ein" 0 "Lampe_aus" ;
VAL_ 1440 BR2_Text 14 "ESP_Sport" 13 "Reifen_pruefen" 12 "ABS_ASR_Stoerung" 11 "ASR_aktiviert" 10 "Keine_BKVerstaerkung" 9 "Stoerung_Hillholder" 8 "ESP_aktiv" 7 "ASR_deaktiv" 6 "ESP_deaktiv" 5 "ASR_Stoerung" 4 "Werkstatt_Bremse" 3 "ESP_ABS_Stoerung" 2 "ABS_Stoerung" 1 "ESP_Stoerung" 0 "Kein_Text" ;
VAL_ 1440 BR2_Aku_Warn 3 "ein_Mal_Summer_2kHz" 2 "drei_Mal_Gong_Summer" 1 "ein_Mal_Gong" 0 "Kein_Gong_bzw_Summer" ;
VAL_ 1440 BR2_HDC_aktiv 1 "HDC_aktiv_oder_standby" 0 "HDC_inaktiv" ;
VAL_ 1440 BR2_Ueberl_Imp 1 "mind_1mal_Ueberlauf" 0 "Reset_und_kein_Ueberlauf" ;
VAL_ 1440 BR2_Fehlereintr 1 "Fehlerspeichereintrag" 0 "kein_Fehlerspeichereintrag" ;
VAL_ 1440 BR2_LampeHDC 1 "Lampe_ein" 0 "Lampe_aus" ;
VAL_ 1440 BR2_QB_Querbeschl 1 "Ersatz_Init_oder_Fehlerwert" 0 "gueltiger_Wert" ;
VAL_ 1440 BR2_Sta_Imp 1 "Fehler" 0 "Wegimpulse_i_O" ;
VAL_ 1440 BR2_SleepInd 1 "Sleep_bereit" 0 "CAN_wird_benoetigt" ;
VAL_ 1440 BR2_Sta_Quer 1 "gemessen" 0 "errechnet" ;
VAL_ 416 BR1_ASR_Anf 1 "ASR_Anforderung" 0 "keine_Anforderung" ;
VAL_ 416 BR1_MSR_Anf 1 "MSR_Anforderung" 0 "keine_Anforderung" ;
VAL_ 416 BR1_ABS_Brems 1 "ABS_Regelung" 0 "keine_ABS_Regelung" ;
VAL_ 416 BR1_EDS_Eingr 1 "EDS_Eingriff" 0 "kein_EDS_Eingriff" ;
VAL_ 416 BR1_ESP_Eingr 1 "ESP_Eingriff" 0 "kein_ESP_Eingriff" ;
VAL_ 416 BR1_ASR_Eingr 3 "Schaltverbot" 2 "Rueckschaltung" 1 "ASR_Schaltkennfeld" 0 "keine_Anforderung" ;
VAL_ 416 BR1_EBV_Eingr 1 "EBV_Eingriff" 0 "kein_EBV_Eingriff" ;
VAL_ 416 BR1_Lampe_ABS 1 "Lampe_ein" 0 "Lampe_aus" ;
VAL_ 416 BR1_Lampe_ASR 1 "Lampe_ein" 0 "Lampe_aus" ;
VAL_ 416 BR1_Lampe_BK 1 "Lampe_ein" 0 "Lampe_aus" ;
VAL_ 416 BR1_Lichtschalt 1 "Bremse_betaetigt_Schw_ueberschr" 0 "kein_Bremsen_Schw_unterschr" ;
VAL_ 416 BR1_StaDruckschw 1 "Sta_n_verf__BKV_angest__Br" 0 "Sta_guel__BKV_n_angest__k_Br" ;
VAL_ 416 BR1_Diagnose 1 "in_Diagnose" 0 "nein" ;
VAL_ 416 BR1_Rad_kmh 32742 "Sensorfehler" 32725 "Unterspannung" 32708 "Init_PQ25_35_46" ;
VAL_ 416 BR1_ASRMo_fa 255 "Fehler" ;
VAL_ 416 BR1_MSR_Mo 255 "Fehler" ;
VAL_ 416 BR1_ASR_ESP 1 "ASR_ESP_MABS" 0 "ABS_ABS_EDS" ;
VAL_ 416 BR1_ESPASR_passiv 1 "ESP_oder_ASR_passiv_get_oder_Fktumsch_oder_Rollenmodus" 0 "ESP_ASR_aktiviert" ;
VAL_ 416 BR1_Sta_ESP 1 "Fehler" 0 "ok" ;
VAL_ 416 BR1_Ersatz_Kmh 1 "Ersatzwert" 0 "i_O" ;
VAL_ 416 BR1_MAD 1 "Ausblendung" 0 "keine_Ausblendung" ;
VAL_ 416 BR1_Sta_MAD 1 "ungueltig" 0 "gueltig" ;
VAL_ 416 BR1_BKV_aktiv 1 "BKV_verbaut_und_kein_Fehler" 0 "BKV_nicht_verbaut_oder_Fehler" ;
VAL_ 416 BR1_ASRMo_sl 255 "Fehler" ;
VAL_ 928 B10_QB_Wegimp_VL 1 "Ersatz_Init_oder_Fehlerwert" 0 "gueltiger_Wert" ;
VAL_ 928 B10_QB_Wegimp_VR 1 "Ersatz_Init_oder_Fehlerwert" 0 "gueltiger_Wert" ;
VAL_ 928 B10_QB_Wegimp_HL 1 "Ersatz_Init_oder_Fehlerwert" 0 "gueltiger_Wert" ;
VAL_ 928 B10_QB_Wegimp_HR 1 "Ersatz_Init_oder_Fehlerwert" 0 "gueltiger_Wert" ;
VAL_ 928 B10_Wegimp_VL 1023 "Sensorfehler" 1022 "Unterspannung" 1021 "Initwert" ;
VAL_ 928 B10_Wegimp_VR 1023 "Sensorfehler" 1022 "Unterspannung" 1021 "Initwert" ;
VAL_ 928 B10_Wegimp_HL 1023 "Sensorfehler" 1022 "Unterspannung" 1021 "Initwert" ;
VAL_ 928 B10_Wegimp_HR 1023 "Sensorfehler" 1022 "Unterspannung" 1021 "Initwert" ;
VAL_ 928 B10_QB_Fahrtr_VL 1 "Ersatz_Init_oder_Fehlerwert" 0 "gueltiger_Wert" ;
VAL_ 928 B10_QB_Fahrtr_VR 1 "Ersatz_Init_oder_Fehlerwert" 0 "gueltiger_Wert" ;
VAL_ 928 B10_QB_Fahrtr_HL 1 "Ersatz_Init_oder_Fehlerwert" 0 "gueltiger_Wert" ;
VAL_ 928 B10_QB_Fahrtr_HR 1 "Ersatz_Init_oder_Fehlerwert" 0 "gueltiger_Wert" ;
VAL_ 928 B10_Fahrtr_VL 1 "Rueckwaerts" 0 "Vorwaerts" ;
VAL_ 928 B10_Fahrtr_VR 1 "Rueckwaerts" 0 "Vorwaerts" ;
VAL_ 928 B10_Fahrtr_HL 1 "Rueckwaerts" 0 "Vorwaerts" ;
VAL_ 928 B10_Fahrtr_HR 1 "Rueckwaerts" 0 "Vorwaerts" ;
VAL_ 1463 B11_HydHalten 1 "Fzg_wird_hydr_gehalten" 0 "Fzg_wird_nicht_hydr_gehalten" ;
VAL_ 1463 B11_Br_StSt_Info 3 "Systemfehler" 2 "Motoranlauf_zwingend_notwendig_(Startanforderung)" 1 "Motoranlauf_nicht_zwingend_notwendig_(Stoppverbot,keine_Startanforderung)" 0 "Motorlauf_nicht_notwendig_(Stoppfreigabe)" ;
VAL_ 1463 B11_OBD_Nib_VL 15 "frei" 14 "frei" 13 "frei" 12 "frei" 11 "KS_MP_OC" 10 "KS_MP" 9 "KS_M_OC" 8 "KS_P_OC" 7 "RC_M" 6 "RC_P" 5 "OOR_M" 4 "OOR_P" 3 "OC" 2 "KS_P" 1 "KS_M" 0 "kein_Fehler" ;
VAL_ 1463 B11_OBD_Nib_VR 15 "frei" 14 "frei" 13 "frei" 12 "frei" 11 "KS_MP_OC" 10 "KS_MP" 9 "KS_M_OC" 8 "KS_P_OC" 7 "RC_M" 6 "RC_P" 5 "OOR_M" 4 "OOR_P" 3 "OC" 2 "KS_P" 1 "KS_M" 0 "kein_Fehler" ;
VAL_ 1463 B11_OBD_Nib_HL 15 "frei" 14 "frei" 13 "frei" 12 "frei" 11 "KS_MP_OC" 10 "KS_MP" 9 "KS_M_OC" 8 "KS_P_OC" 7 "RC_M" 6 "RC_P" 5 "OOR_M" 4 "OOR_P" 3 "OC" 2 "KS_P" 1 "KS_M" 0 "kein_Fehler" ;
VAL_ 1463 B11_OBD_Nib_HR 15 "frei" 14 "frei" 13 "frei" 12 "frei" 11 "KS_MP_OC" 10 "KS_MP" 9 "KS_M_OC" 8 "KS_P_OC" 7 "RC_M" 6 "RC_P" 5 "OOR_M" 4 "OOR_P" 3 "OC" 2 "KS_P" 1 "KS_M" 0 "kein_Fehler" ;
VAL_ 1463 B11_EPB_Steller_akt 1 "EPB_Steller_verfaehrt" 0 "EPB_Steller_verfaehrt_nicht" ;
VAL_ 1463 B11_EPB_Steller_gue 1 "EPB_Steller_Info_gueltig" 0 "EPB_Steller_Info_ungueltig" ;
VAL_ 1463 B11_Backup_MSR 1 "verfuegbar" 0 "nicht_verfuegbar" ;
VAL_ 1463 OBD_Fehler_Bremsdruck 15 "frei" 14 "frei" 13 "frei" 12 "frei" 11 "KS_MP_OC" 10 "KS_MP" 9 "KS_M_OC" 8 "KS_P_OC" 7 "RC_M" 6 "RC_P" 5 "OOR_M" 4 "OOR_P" 3 "OC" 2 "KS_P" 1 "KS_M" 0 "kein_Fehler" ;
VAL_ 1463 ESP_nachtr_Stopp_Anf 1 "angefordert" 0 "nicht_angefordert" ;
VAL_ 1184 BR3_Rad_kmh_VL 32742 "Sensorfehler" 32725 "Unterspannung" 32708 "Init_PQ25_35_46" ;
VAL_ 1184 BR3_Rad_kmh_VR 32742 "Sensorfehler" 32725 "Unterspannung" 32708 "Init_PQ25_35_46" ;
VAL_ 1184 BR3_Rad_kmh_HL 32742 "Sensorfehler" 32725 "Unterspannung" 32708 "Init_PQ25_35_46" ;
VAL_ 1184 BR3_Rad_kmh_HR 32742 "Sensorfehler" 32725 "Unterspannung" 32708 "Init_PQ25_35_46" ;
VAL_ 1184 BR3_Fahrtr_VL 1 "Rueckwaerts" 0 "Vorwaerts" ;
VAL_ 1184 BR3_Fahrtr_VR 1 "Rueckwaerts" 0 "Vorwaerts" ;
VAL_ 1184 BR3_Fahrtr_HL 1 "Rueckwaerts" 0 "Vorwaerts" ;
VAL_ 1184 BR3_Fahrtr_HR 1 "Rueckwaerts" 0 "Vorwaerts" ;
VAL_ 672 BR4_Vorgabe_Mi 255 "Fehler" 254 "Kupplung_ganz_schl" 127 "Kupplung_schnell_offen" 0 "keine_Vorgabe" ;
VAL_ 672 BR4_Einheit 2 "Nm_VAQ" 1 "Prozente" 0 "Nm_Haldex" ;
VAL_ 672 BR4_Schwelle 3 "U_Signal_temp_n_verf" 2 "Unterdruck_gr_450mbar" 1 "Unterdruck_klgl_450mbar" 0 "kein_Signal" ;
VAL_ 672 BR4_Lampentrennung_gue 1 "gueltig" 0 "ungueltig" ;
VAL_ 672 BR4_Lampe_ASRESP 1 "Lampe_ein" 0 "Lampe_aus" ;
VAL_ 672 BR4_ESP_Off 1 "Lampe_ein" 0 "Lampe_aus" ;
VAL_ 672 BR1_ASR_ESP 1 "ASR_ESP_MABS" 0 "ABS_ABS_EDS" ;
VAL_ 672 BR4_Unterdruck 255 "Fehler" ;
VAL_ 672 BR4_Vorgabe_Mi_308 255 "Fehler" 254 "Kupplung_schliessen_100_Prozent" 128 "Kupplung_oeffnen_0_Prozent" 127 "Kupplung_schnell_offen" ;
VAL_ 672 BR4_Vorgabe_Hi 255 "Fehler" 254 "Kupplung_schliessen_100_Prozent" 128 "Kupplung_oeffnen_0_Prozent" 127 "Kupplung_schnell_offen" ;
VAL_ 672 BR4_Abschaltung_VL 1 "EDS_VL_Temp_Absch" 0 "EDS_VL_i_O" ;
VAL_ 672 BR4_Abschaltung_VR 1 "EDS_VR_Temp_Absch" 0 "EDS_VR_i_O" ;
VAL_ 672 BR4_Abschaltung_HL 1 "EDS_HL_Temp_Absch" 0 "EDS_HL_i_O" ;
VAL_ 672 BR4_Abschaltung_HR 1 "EDS_HR_Temp_Absch" 0 "EDS_HR_i_O" ;
VAL_ 672 BR4_Lampe_RKA 1 "Lampe_ein" 0 "Lampe_aus" ;
VAL_ 672 BR4_Summer_RKA 1 "Summer_ein" 0 "Summer_aus" ;
VAL_ 672 BR4_Status_ESP 5 "AYC_Unterst_mo_regl_aktiv" 4 "ESP_Anf_VAQ" 3 "ESP_bereit" 2 "Kom_VAQ_gestoert" 1 "ESP_Fehlerstatus" 0 "VAQ_deaktiviert" ;
VAL_ 672 BR4_MABS_Verbau 1 "MABS_mit_ASR_Funktion_verbaut" 0 "kein_MABS_verbaut" ;
VAL_ 672 BR4_RKA_Verbau 2 "RKA_Signale_in_mBremse_RKA" 1 "RKA_Signale_in_mBremse_2" 0 "kein_RKA_verbaut_oder_unbekannt" ;
VAL_ 1192 BR5_Giergeschw 16383 "Fehler" 16382 "ABS_only_System" 16381 "MABS_System" ;
VAL_ 1192 BR5_Sta_Gierrate 1 "ungueltig" 0 "gueltig" ;
VAL_ 1192 BR5_Vorzeichen 1 "negatives_Vorzeichen" 0 "positives_Vorzeichen" ;
VAL_ 1192 BR5_Bremsdruck 4095 "Fehler" ;
VAL_ 1192 BR5_Stillstand 1 "Stillstand_erkannt" 0 "kein_Stillstand_erkannt" ;
VAL_ 1192 BR5_Druckgueltig 1 "ungueltig" 0 "gueltig" ;
VAL_ 1192 BR5_Sta_Druck 1 "aktiver_Druckaufbau" 0 "kein_aktiver_Druckaufbau" ;
VAL_ 1192 BR5_Sign_Druck 1 "negatives_Vorzeichen" 0 "positives_Vorzeichen" ;
VAL_ 1192 BR5_Bremslicht 1 "Bremslicht_an" 0 "keine_Bremslichtanforderung" ;
VAL_ 1192 BR5_AWV2_Bremsruck 1 "Bremsruck_wird_durchgefuehrt" 0 "kein_Bremsruck" ;
VAL_ 1192 BR5_AWV2_Fehler 1 "Fehler" 0 "kein_Fehler" ;
VAL_ 1192 ESP_Rollenmodus_Deaktivieren 1 "Abbruch" 0 "keine_Aenderung" ;
VAL_ 1192 ESP_Stat_FallBack_eBKV 1 "Rueckfallebene_vorhanden" 0 "Rueckfallebene_nicht_vorhanden" ;
VAL_ 1192 ESP_Anforderung_EPB 3 "Anforderung_Schliessen_mit_verminderter_Spannkraft" 2 "Anforderung_Schliessen" 1 "Anforderung_Oeffnen" 0 "keine_Anforderung" ;
VAL_ 1192 BR5_Anhi_akt 1 "aktiv" 0 "nicht_aktiv" ;
VAL_ 1192 BR5_v_Ueberw 1 "ja" 0 "nein" ;
VAL_ 1192 BR5_Fahrer_tritt_ZBR_Schw 1 "Fahrer_uebertritt_ZBR_Schwelle" 0 "Fahrer_uebertritt_ZBR_Schwelle_nicht" ;
VAL_ 1192 BR5_ECD_Lampe 1 "Ein" 0 "Aus" ;
VAL_ 1192 ESP_Autohold_aktiv 1 "Autohold_aktiv" 0 "Autohold_inaktiv" ;
VAL_ 1192 ESP_Autohold_Standby 1 "Autohold_im_Standby" 0 "Autohold_nicht_im_Standby" ;
VAL_ 1192 BR5_Anhi_Sta 1 "Fehler" 0 "kein_Fehler" ;
VAL_ 1192 BR5_Notbremsung 1 "Notbremsung_erk" 0 "keine_Notbremsung" ;
VAL_ 1192 BR5_ZT_Rueckk_Umsetz 1 "ZT_wird_durchgefuehrt" 0 "ZT_wird_nicht_durchgefuehrt" ;
VAL_ 1192 BR5_ANB_CM_Rueckk_Umsetz 1 "CM_wird_durchgefuehrt" 0 "CM_wird_nicht_durchgefuehrt" ;
VAL_ 1192 BR5_HDC_bereit 1 "HDC_bereit" 0 "HDC_nicht_bereit" ;
VAL_ 428 BR8_Sta_ACC_Anf 1 "aktiv" 0 "passiv" ;
VAL_ 428 BR8_Verz_EPB_akt 1 "aktiviert" 0 "nicht_aktiviert" ;
VAL_ 428 BR8_Sta_Br_temp 1 "ueberhitzt" 0 "nicht_ueberhitzt" ;
VAL_ 428 BR8_Sta_Br_Druck 1 "mit_Bremsdruck" 0 "Bremse_drucklos" ;
VAL_ 428 BR8_Istbeschl 511 "Fehler" ;
VAL_ 428 BR8_QB_LBeschl 1 "Ersatz_Init_oder_Fehlerwert" 0 "gueltiger_Wert" ;
VAL_ 428 BR8_aktBrSyst 1 "ja" 0 "nein" ;
VAL_ 428 BR8_StaBrSyst 1 "System_aktiv" 0 "System_inaktiv" ;
VAL_ 428 BR8_Laengsbeschl 1023 "Fehler" 0 "Init" ;
VAL_ 428 BR8_Sta_ADR_BR 1 "ACC_Botschaft_nicht_konsistent" 0 "ACC_Botschaft_konsistent" ;
VAL_ 428 BR8_Sta_VerzReg 1 "nicht_funktionsfaehig" 0 "funktionsfaehig" ;
VAL_ 428 BR8_Verz_EPB 1 "System_verfuegbar" 0 "nicht_verfuegbar" ;
VAL_ 428 BR8_Check_EPB 1 "plausibel" 0 "nicht_plausibel" ;
VAL_ 428 BR8_HHC_Haltebestaetigung 1 "Bremsdruck_ausreichend" 0 "Bremsdruck_nicht_ausreichend" ;
VAL_ 428 BR8_HHC_Signal_QBit 1 "Ersatz_Init_oder_Fehlerwert" 0 "gueltiger_Wert" ;
VAL_ 428 BR8_Sta_HW_BLS 1 "Ausgang_defekt" 0 "Ausgang_iO" ;
VAL_ 428 BR8_ESC_Mode 3 "ESC_Mode_3" 2 "ESC_Mode_2" 1 "ESC_Mode_1" 0 "ESC_Mode_0" ;
VAL_ 428 BR8_Fa_bremst 1 "Fahrer_bremst" 0 "Fahrer_bremst_nicht" ;
VAL_ 428 BR8_Quattro 1 "Quattro" 0 "Front" ;
VAL_ 428 BR8_Sta_BLS 1 "Fehler" 0 "kein_Fehler" ;
VAL_ 428 ESP_MKB_ausloesbar 1 "Multikollisionsbremsung_freigeschaltet" 0 "Multikollisionsbremsung_nicht_freigeschaltet" ;
VAL_ 428 ESP_Haltebestaetigung 1 "sicheres_Halten" 0 "kein_sicheres_Halten" ;
VAL_ 428 ESC_Motorstartverzoegerung 1 "Anforderung_Startverzoegerung" 0 "Startfreigabe" ;
VAL_ 174 BR9_Sta_ESP_PLA 10 "ESP_PLA_Abbruch" 9 "ESP_PLA_Neustart" 8 "ESP_PLA_funktionsbereit" 6 "ESP_PLA_Bremse_aktiv" 4 "ESP_PLA_Aktivierbar" 2 "Fehler" 1 "EPS_PLA_Init" 0 "ESP_PLA_Deaktiv" ;
VAL_ 174 BR9_LMOffSign 1 "negatives_Vorzeichen" 0 "positives_Vorzeichen" ;
VAL_ 174 BR9_LWOffSign 1 "negatives_Vorzeichen" 0 "positives_Vorzeichen" ;
VAL_ 174 BR9_Sta_DSR 7 "ext_MomLWeingriff_angef" 6 "ext_LWeingriff_angef" 5 "ext_Momeingriff_angef" 4 "offen" 3 "ESP_funktionsbereit" 2 "Kom_ESP_gestoert" 1 "DSR_Anf_nicht_ausfuehrbar" 0 "DSR_deaktiviert" ;
VAL_ 174 BR9_PLA_Abbruch 6 "Abbruch_durch_FT_offen" 5 "Abbruch_durch_Kl15_aus" 4 "PLA_Bremsanforderung_nach_Stillstand" 3 "Deaktivierung_durch_Abbruch_Lenkung" 2 "Falscher_PLA_Status" 1 "Geschwindigkeitsueberschreitung" ;
VAL_ 912 GK1_SleepAckn 1 "Sleep_Mode_Befehl" 0 "CAN_Kom_erforderlich" ;
VAL_ 912 GK1_Sta_Anhaen 1 "veraltet" 0 "aktuell_empfangen" ;
VAL_ 912 GK1_Sta_Licht1 1 "veraltet" 0 "aktuell_empfangen" ;
VAL_ 912 GK1_Sta_Tuerkont 1 "veraltet" 0 "aktuell_empfangen" ;
VAL_ 912 GK1_Fa_Tuerkont 1 "Tuer_offen" 0 "Tuer_geschlossen" ;
VAL_ 912 GK1_Rueckfahr 1 "Rueckfahrlicht_ein" ;
VAL_ 912 GK1_Anhaenger 1 "Anhaenger_erkannt" 0 "kein_Anhaenger_erkannt" ;
VAL_ 912 GK1_Wischer_vorn 1 "Wischer_vorne_laeuft" 0 "Wischer_aus" ;
VAL_ 912 GK1_Sta_ILM_F_1 1 "veraltet" 0 "aktuell_empfangen" ;
VAL_ 912 GK1_Warnblk_Status 1 "Warnblinkstatus_ein" ;
VAL_ 912 GK1_Sta_RDK_Warn 1 "veraltet" 0 "aktuell_empfangen" ;
VAL_ 912 GK1_Sta_Licht3 1 "veraltet" 0 "aktuell_empfangen" ;
VAL_ 912 GK1_Sta_Li_vorn 1 "veraltet" 0 "aktuell_empfangen" ;
VAL_ 912 LIA_Standlicht 1 "Kl58_ein" ;
VAL_ 912 GK1_CharismaModus 3 "sport" 2 "normal" 1 "comfort" 0 "Init" ;
VAL_ 912 GK1_SamFktNr 1 "Charisma" 0 "ungueltig_Init" ;
VAL_ 912 GK1_RueckfahrSch 1 "ein" 0 "aus" ;
VAL_ 912 GK1_ELV_verrieg 1 "ELV_verriegelt" 0 "ELV_nicht_verriegelt" ;
VAL_ 912 GK1_Sta_Kessy_2 1 "veraltet" 0 "aktuell_empfangen" ;
VAL_ 912 GK1_Sta_Stdhzg 1 "veraltet" 0 "aktuell_empfangen" ;
VAL_ 912 GK1_SH_Verbau 1 "Standheizung" 0 "Zuheizer" ;
VAL_ 912 GK1_ParkFrontWi 1 "Parklage" 0 "keine_Parklage" ;
VAL_ 912 GK1_KW_Warm 1 "ja" 0 "nein" ;
VAL_ 912 BCM_Remotestart_Betrieb 1 "RS_Betrieb" 0 "kein_RS_Betrieb" ;
VAL_ 912 BSK_HL_geoeffnet 1 "Tuer_offen" 0 "Tuer_geschlossen" ;
VAL_ 912 BSK_HR_geoeffnet 1 "Tuer_offen" 0 "Tuer_geschlossen" ;
VAL_ 912 GK1_BrLi_links 1 "Bremslicht_HL_def" 0 "Leuchte_i_O" ;
VAL_ 912 GK1_BrLi_rechts 1 "Bremslicht_HR_def" 0 "Leuchte_i_O" ;
VAL_ 912 GK1_BrLi_mitte 1 "Bremslicht_oben_def" 0 "Leuchte_i_O" ;
VAL_ 912 GK1_BLS_ILM 1 "unplausibel" 0 "ok" ;
VAL_ 912 GK1_EDC_ILM 1 "unplausibel" 0 "ok" ;
VAL_ 912 GK1_Blinker_li 1 "aktiviert" 0 "aus" ;
VAL_ 912 GK1_Blinker_re 1 "aktiviert" 0 "aus" ;
VAL_ 912 GK1_def_P_verr 1 "defekt" 0 "OK" ;
VAL_ 912 GK1_LS1_Fernlicht 1 "Fernlichtschalter_ein" 0 "Fernlichtschalter_aus" ;
VAL_ 912 GK1_Sta_Licht2 1 "veraltet" 0 "aktuell_empfangen" ;
VAL_ 912 GK1_Sta_LSM 1 "veraltet" 0 "aktuell_empfangen" ;
VAL_ 912 BSK_BT_geoeffnet 1 "Tuer_offen" 0 "Tuer_geschlossen" ;
VAL_ 912 BCM_CV_Taster 1 "Funktion_deaktiviert" 0 "Funktion_aktiviert" ;
VAL_ 912 BSK_HD_Hauptraste 1 "Hauptraste" 0 "geschlossen" ;
VAL_ 912 BSK_Tankklappe 1 "Tankklappe_offen" 0 "Tankklappe_zu" ;
VAL_ 912 EV1_Anf_Klemme_50 1 "Ein" 0 "Aus" ;
VAL_ 912 GK1_BrLi_Anhaen 1 "defekt" 0 "i_O" ;
VAL_ 912 GK1_Abblendlicht 1 "Kl56b_ein" 0 "aus" ;
VAL_ 912 GK1_Fernlicht 1 "Kl56a_ein" 0 "aus" ;
VAL_ 912 GK1_Abbl_VL_def 1 "Abblendlicht_VL_def" 0 "Leuchte_i_O" ;
VAL_ 912 GK1_Abbl_VR_def 1 "Abblendlicht_VR_def" 0 "Leuchte_i_O" ;
VAL_ 912 GK1_Blink_Autob 1 "Autobahnblinken_aktiviert" 0 "Autobahnblinken_aus" ;
VAL_ 912 GK1_SH_laeuft 1 "SH_ist_oder_war_aktiv" 0 "SH_aus" ;
VAL_ 912 SH1_ein_Wasserpumpe 1 "Wasserpumpe_EIN" 0 "Wasserpumpe_AUS" ;
VAL_ 912 GK1_Nebel_ein 1 "Kl83a_ein" 0 "aus" ;
VAL_ 912 GK1_Bremslicht 1 "Bremslicht_ein" 0 "aus" ;
VAL_ 912 GK1_Anh_abgesteckt 1 "ja" 0 "nein" ;
VAL_ 912 GK1_AnhKonLamp 1 "Lampe_ein" 0 "Lampe_aus" ;
VAL_ 912 LDS_Stellung_AFL 1 "LDS_Stellung_AFL" ;
VAL_ 912 GK1_SH_Zusatzfkt 1 "verfuegbar" 0 "nicht_verf" ;
VAL_ 912 BCM_Offroad_Taster 1 "betaetigt" 0 "nicht_betaetigt" ;
VAL_ 194 LW1_Initquelle 1 "EPS_Bit" 0 "Bremse_3" ;
VAL_ 194 LW1_LRW_Sign 1 "negatives_Vorzeichen" 0 "positives_Vorzeichen" ;
VAL_ 194 LW1_ID 128 "kalibriert_nur_bei_PQ35_46_VW32x_VW411" 0 "noch_nicht_kalibriert" ;
VAL_ 194 LW1_Status 3 "dauerhafter_Fehler" 2 "sporadischer_Fehler" 1 "no_init" 0 "ok" ;
VAL_ 194 LW1_Sta_KL30 1 "no_init_s" 0 "ok" ;
VAL_ 194 LW1_Gesch_Sign 1 "negatives_Vorzeichen" 0 "positives_Vorzeichen" ;
VAL_ 1420 M10_StartStopp_Fahrerwunsch 3 "Stoppanforderung_durch_Fahrer" 2 "Stoppfreigabe_durch_Fahrer" 1 "Stoppverbot_durch_Fahrer" 0 "Init" ;
VAL_ 1420 M10_Status_StSt 3 "System_aktiv_mindestens_eine_Freigabe_fehlt" 2 "System_aktiv_alle Freigaben_liegen_vor" 1 "System_aktiv_keine_Freigabe_durch_StartStop_Koordinator" 0 "System_in_diesem_KL15_Zyklus_nicht_verfuegbar" ;
VAL_ 1420 M10_Wiederstart 1 "Wiederstart_aktiv" 0 "Wiederstart_inaktiv" ;
VAL_ 1420 M10_Anzeige 15 "Bremse_treten" 14 "Waehlhebel_in_P_N_Position" 13 "Kupplung_betaetigen" 12 "Motor_startet" 9 "Unerwuenschter_Motorstillstand" 5 "Temporaer_nicht_verfuegbar_Symbol_durchgestr_A" 3 "Motor_manuell_starten" 2 "Systemfehler_Start_Stopp" 1 "Motor_in_Stoppbetrieb_Symbol_A" 0 "keine_Anzeige" ;
VAL_ 1420 M10_Anf_Kl75 1 "Anf_Kl75_einschalten" 0 "Anf_Kl75_ausschalten" ;
VAL_ 1420 MSG_Remotestart_Betrieb 1 "RS_Betrieb" 0 "kein_RS_Betrieb" ;
VAL_ 1420 M10_SpannungsAnf 1 "Anforderung" 0 "keine_Anforderung" ;
VAL_ 1420 M10_UDruckDyn 1 "Dyn_immer_kleiner_50mbar" 0 "Dyn_1mal_groesser_50mbar" ;
VAL_ 1420 M10_Freigabe_Reku 3 "RekuModus_aktiv" 2 "Empf_U_Absenkung" 1 "Empf_U_Anhebung" 0 "RekuModus_aus" ;
VAL_ 1420 M10_Fahrbereitschaft 1 "fahrbereit" 0 "nicht_fahrbereit" ;
VAL_ 1420 M10_Hybrid 1 "Hybrid" 0 "kein_Hybrid" ;
VAL_ 1420 M10_EM_aktiv 1 "EM_aktiv" 0 "EM_inaktiv" ;
VAL_ 1420 M10_VM_aktiv 1 "VM_aktiv" 0 "VM_inaktiv" ;
VAL_ 1420 M10_HYB_Bereitlampe 1 "Lampe_ein" 0 "Lampe_aus" ;
VAL_ 1420 M10_HYB_Warnlampe 1 "Lampe_ein" 0 "Lampe_aus" ;
VAL_ 1420 M10_HYB_Fehlerlampe 1 "Lampe_ein" 0 "Lampe_aus" ;
VAL_ 1420 M10_Fehler_HV_Netz 1 "kein_gen_Betrieb_moegl" 0 "iO" ;
VAL_ 1420 M10_EKlKomLeiRed 3 "LeistBegr_25" 2 "LeistBegr_50" 1 "LeistBegr_75" 0 "keine_LeistBegr" ;
VAL_ 1420 M10_Klimadruck 255 "Fehler" 254 "Init" ;
VAL_ 1420 M10_KompAusCode 7 "Unterspg_10" 6 "Ueberspg_13" 5 "HD_Sensor_def_17" 4 "MotManagem_12" 3 "Aussentemp_8" 2 "Niederdruck_3" 1 "Hochdruck_1" 0 "keine" ;
VAL_ 1420 M10_Akustik 3 "frei" 2 "Akustik_2" 1 "Akustik_1" 0 "keine_Akustik" ;
VAL_ 1420 M10_Text_1_Hybrid 1 "Text_1" 0 "kein_Text" ;
VAL_ 1420 M10_Text_2_Hybrid 1 "Text_2" 0 "kein_Text" ;
VAL_ 1420 M10_Text_3_Hybrid 1 "Text_3" 0 "kein_Text" ;
VAL_ 1420 M10_Text_4_Hybrid 1 "Text_4" 0 "kein_Text" ;
VAL_ 1420 M10_Text_5_Hybrid 1 "Text_5" 0 "kein_Text" ;
VAL_ 1420 M10_Text_6_Hybrid 1 "Text_6" 0 "kein_Text" ;
VAL_ 1420 M10_Text_7_Hybrid 1 "Text_7" 0 "kein_Text" ;
VAL_ 1420 M10_Text_8_Hybrid 1 "Text_8" 0 "kein_Text" ;
VAL_ 1420 M10_ShiftLockLampe 1 "Lampe_ein" 0 "Lampe_aus" ;
VAL_ 1420 MO_Auth_Aufforderung_WFS 1 "Ein" 0 "Aus" ;
VAL_ 1420 M10_BMSInfo_gue 1 "gueltig" 0 "nicht_gueltig_od_alt" ;
VAL_ 1420 M10_VentilationReq 1 "Umluftklappe_oeffnen" 0 "Umluftklappe_nicht_oeffnen" ;
VAL_ 1420 M10_BattFanSpd 15 "Fehler" ;
VAL_ 1420 M10_MotorStopp 1 "Motor_Stopp_aktiv" 0 "Motor_Stopp_inaktiv" ;
VAL_ 1420 M10_Schubabschaltung 1 "Schubabschaltung" 0 "keine_Schubabsch" ;
VAL_ 1420 M10_Druck_err_gem 1 "gemessen" 0 "errechnet" ;
VAL_ 1420 M10_rel_Saugrohrdruck 63 "Fehler_nicht_verf" ;
VAL_ 1152 MO5_Mp_Code 3 "Abgastyp_od_norm_Verbrauch" 2 "Motor_Typ" 1 "Drehzahl" 0 "Max_Moment" ;
VAL_ 1152 MO5_Abgastyp 1 "EOBD" 0 "kein_EOBD" ;
VAL_ 1152 MO5_Abgastyp2 1 "OBD" 0 "kein_OBD" ;
VAL_ 1152 MO5_Abgastyp3 1 "DPF_verbaut" 0 "kein_DPF_verbaut" ;
VAL_ 1152 OBD_Kaltstart_Denominator 1 "Bedingungen_zum_Inkr_des_Kaltstart_Denom_erf" 0 "Denominator_nicht_hochzaehlen" ;
VAL_ 1152 OBD_Minimum_Trip 1 "Min_Normed_Trip" 0 "kein_Min_Normed_Trip" ;
VAL_ 1152 MO5_DPF_reg 1 "DPF_regeneriert" 0 "DPF_regeneriert_nicht" ;
VAL_ 1152 MO5_Vorgluehen 1 "Lampe_ein" 0 "Lampe_aus" ;
VAL_ 1152 MO5_E_Gas 1 "Lampe_ein" 0 "Lampe_aus" ;
VAL_ 1152 MO5_OBD_2 1 "Lampe_ein" 0 "Lampe_aus" ;
VAL_ 1152 MO5_Heissl 1 "Lampe_ein" 0 "Lampe_aus" ;
VAL_ 1152 MO5_KlimaKompr 1 "Klimakompr_aus" 0 "keine_Anforderung" ;
VAL_ 1152 MO5_Feld_kuehl 1 "ja" 0 "nein" ;
VAL_ 1152 MO5_KliKo_Red 1 "ja" 0 "nein" ;
VAL_ 1152 MO5_UeberlVerb 1 "mindestens_einmal_uebergelaufen" 0 "kein_Ueberlauf" ;
VAL_ 1152 MO5_Luefter 255 "Fehler" 0 "keine_Anforderung" ;
VAL_ 1152 MO5_HLeuchte 1 "Vorwarnung" 0 "keine_Warnung" ;
VAL_ 1152 MO5_PartikelLamp 1 "Lampe_ein" 0 "Lampe_aus" ;
VAL_ 1152 MO5_Sta_BKU 1 "n_iO" 0 "iO_oder_nicht_verbaut" ;
VAL_ 1152 MO5_TypStartSteu 1 "Startersteuerung_durch_MSG" 0 "Startersteuerung_BSG_BCM_KessyD1_ZAS" ;
VAL_ 1152 MO5_TDE_Lampe 1 "Lampe_ein" 0 "Lampe_aus" ;
VAL_ 1152 MO5_TDE_Text 1 "Textanzeige_nach_ISO" 0 "kein_Text" ;
VAL_ 1152 MO5_DZM_Daempf 1 "dynamische_Daempfung" 0 "normale_Daempfung" ;
VAL_ 1152 MO5_Interlock 1 "Interlock_betaetigt" 0 "Interlock_nicht_betaetigt" ;
VAL_ 1152 MO5_Start 1 "Startfreigabe" 0 "Start_nicht_zulaessig" ;
VAL_ 1152 MO5_Anlasser 1 "Anlasser_ausspuren__Ansteuerung_nicht_moeglich" 0 "Anlasser_darf_angesteuert_werden" ;
VAL_ 1152 MO5_GRA_Hauptsch 1 "Ein" 0 "Aus" ;
VAL_ 1152 MO5_Momente 1 "Doppelt" 0 "Einfach" ;
VAL_ 1152 MO5_Motortext1 1 "Text_1" 0 "kein_Text" ;
VAL_ 1152 MO5_Motortext2 1 "Text_2" 0 "kein_Text" ;
VAL_ 1152 MO5_Motortext3 1 "Text_3" 0 "kein_Text" ;
VAL_ 1152 MO5_Motortext4 1 "Text_4" 0 "kein_Text" ;
VAL_ 1408 MFN_Warmup_Cycle 1 "erkannt" 0 "nicht_erkannt" ;
VAL_ 1408 MFN_Verbrenn_Typ 1 "Otto" 0 "Diesel" ;
VAL_ 1408 MFN_Drive_Cycle 1 "erkannt" 0 "nicht_erkannt" ;
VAL_ 1408 MFN_NormedTrip 1 "erkannt" 0 "nicht_erkannt" ;
VAL_ 1408 MFN_Russindex 65535 "Fehler" ;
VAL_ 1408 MFN_Verschl 65535 "Fehler" ;
VAL_ 1408 MFN_Russindex_1488 65535 "Fehler" ;
VAL_ 1408 MFN_Verschl_1489 65535 "Fehler" ;
VAL_ 1408 MFN_KurzzeitMW 255 "Fehler" 0 "kein_Wert" ;
VAL_ 1408 MFN_Fuell_Erk 1 "aktiviert" 0 "deaktiviert" ;
VAL_ 1408 MFN_Oelwarnung 1 "Warnung" 0 "keine_Warnung" ;
VAL_ 1408 MFN_Sensorwarn 1 "Warnung" 0 "keine_Warnung" ;
VAL_ 1408 MFN_Anz_Mittel 0 "Fehler" ;
VAL_ 1408 MFN_Str_Mittel 0 "Fehler" ;
VAL_ 1408 MFN_Ansaugsys 1 "Sauger" 0 "Turbo" ;
VAL_ 1408 MFN_Ansaugsys_1514 1 "Sauger" 0 "Turbo" ;
VAL_ 1408 MFN_Zylinder 15 "18_Zylinder" 14 "16_Zylinder" 13 "15_Zylinder" 12 "12_Zylinder" 11 "11_Zylinder" 10 "10_Zylinder" 9 "9_Zylinder" 8 "8_Zylinder" 7 "7_Zylinder" 6 "6_Zylinder" 5 "5_Zylinder" 4 "4_Zylinder" 3 "3_Zylinder" 2 "2_Zylinder" 1 "1_Zylinder" 0 "0_Zylinder" ;
VAL_ 1408 MFN_Zylinder_2161 15 "18_Zylinder" 14 "16_Zylinder" 13 "15_Zylinder" 12 "12_Zylinder" 11 "11_Zylinder" 10 "10_Zylinder" 9 "9_Zylinder" 8 "8_Zylinder" 7 "7_Zylinder" 6 "6_Zylinder" 5 "5_Zylinder" 4 "4_Zylinder" 3 "3_Zylinder" 2 "2_Zylinder" 1 "1_Zylinder" 0 "0_Zylinder" ;
